VERSION ""
BS_:
BU_:

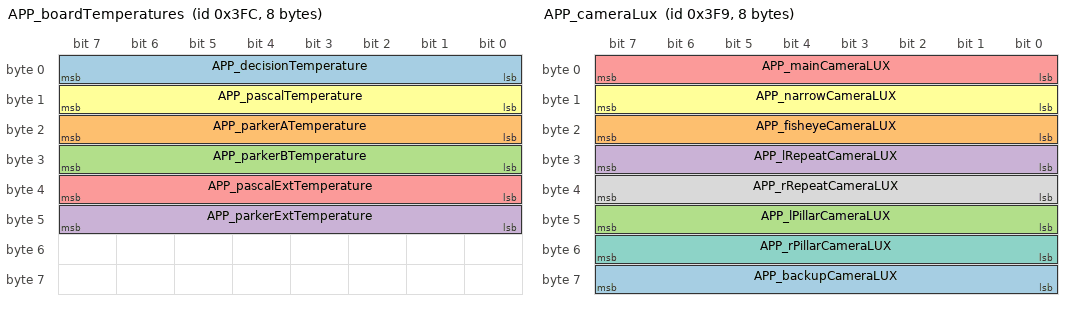
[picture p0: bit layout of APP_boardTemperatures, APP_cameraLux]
BO_ 1020 APP_boardTemperatures: 8 ETH
 SG_ APP_decisionTemperature: 0|8@1+ (1,-128) [0|0] "C" X
 SG_ APP_parkerATemperature: 16|8@1+ (1,-128) [0|0] "C" X
 SG_ APP_parkerBTemperature: 24|8@1+ (1,-128) [0|0] "C" X
 SG_ APP_parkerExtTemperature: 40|8@1+ (1,-128) [0|0] "C" X
 SG_ APP_pascalExtTemperature: 32|8@1+ (1,-128) [0|0] "C" X
 SG_ APP_pascalTemperature: 8|8@1+ (1,-128) [0|0] "C" X

BO_ 1010 APP_camCalibrationStatus: 6 ETH
 SG_ APP_cameraPosition M: 0|4@1+ (1,0) [0|0] "" X
 SG_ APP_mainCamExtPitchCal m1: 8|9@1+ (0.05,-12.5) [0|0] "deg" X
 SG_ APP_mainCamExtYawCal m1: 17|9@1+ (0.05,-12.5) [0|0] "deg" X
 SG_ APP_mainCalibTime m1: 26|7@1+ (1,0) [0|0] "min" X
 SG_ APP_mainCalibProgress m1: 33|7@1+ (1,0) [0|0] "percent" X
 SG_ APP_mainCalibrated m1: 40|1@1+ (1,0) [0|0] "" X
 SG_ APP_narrowCamExtPitchCal m2: 8|9@1+ (0.05,-12.5) [0|0] "deg" X
 SG_ APP_narrowCamExtYawCal m2: 17|9@1+ (0.05,-12.5) [0|0] "deg" X
 SG_ APP_narrowCalibTime m2: 26|7@1+ (1,0) [0|0] "min" X
 SG_ APP_narrowCalibProgress m2: 33|7@1+ (1,0) [0|0] "percent" X
 SG_ APP_narrowCalibrated m2: 40|1@1+ (1,0) [0|0] "" X
 SG_ APP_fisheyeCamExtPitchCal m3: 8|9@1+ (0.05,-12.5) [0|0] "deg" X
 SG_ APP_fisheyeCamExtYawCal m3: 17|9@1+ (0.05,-12.5) [0|0] "deg" X
 SG_ APP_fisheyeCalibTime m3: 26|7@1+ (1,0) [0|0] "min" X
 SG_ APP_fisheyeCalibProgress m3: 33|7@1+ (1,0) [0|0] "percent" X
 SG_ APP_fisheyeCalibrated m3: 40|1@1+ (1,0) [0|0] "" X
 SG_ APP_lPillarCamExtPitchCal m4: 8|9@1+ (0.05,-12.5) [0|0] "deg" X
 SG_ APP_lPillarCamExtYawCal m4: 17|9@1+ (0.05,-12.5) [0|0] "deg" X
 SG_ APP_lPillarCalibTime m4: 26|7@1+ (1,0) [0|0] "min" X
 SG_ APP_lPillarCalibProgress m4: 33|7@1+ (1,0) [0|0] "percent" X
 SG_ APP_lPillarCalibrated m4: 40|1@1+ (1,0) [0|0] "" X
 SG_ APP_rPillarCamExtPitchCal m5: 8|9@1+ (0.05,-12.5) [0|0] "deg" X
 SG_ APP_rPillarCamExtYawCal m5: 17|9@1+ (0.05,-12.5) [0|0] "deg" X
 SG_ APP_rPillarCalibTime m5: 26|7@1+ (1,0) [0|0] "min" X
 SG_ APP_rPillarCalibProgress m5: 33|7@1+ (1,0) [0|0] "percent" X
 SG_ APP_rPillarCalibrated m5: 40|1@1+ (1,0) [0|0] "" X
 SG_ APP_lRepeatCamExtPitchCal m6: 8|9@1+ (0.05,-12.5) [0|0] "deg" X
 SG_ APP_lRepeatCamExtYawCal m6: 17|9@1+ (0.05,-12.5) [0|0] "deg" X
 SG_ APP_lRepeatCalibTime m6: 26|7@1+ (1,0) [0|0] "min" X
 SG_ APP_lRepeatCalibProgress m6: 33|7@1+ (1,0) [0|0] "percent" X
 SG_ APP_lRepeatCalibrated m6: 40|1@1+ (1,0) [0|0] "" X
 SG_ APP_rRepeatCamExtPitchCal m7: 8|9@1+ (0.05,-12.5) [0|0] "deg" X
 SG_ APP_rRepeatCamExtYawCal m7: 17|9@1+ (0.05,-12.5) [0|0] "deg" X
 SG_ APP_rRepeatCalibTime m7: 26|7@1+ (1,0) [0|0] "min" X
 SG_ APP_rRepeatCalibProgress m7: 33|7@1+ (1,0) [0|0] "percent" X
 SG_ APP_rRepeatCalibrated m7: 40|1@1+ (1,0) [0|0] "" X
 SG_ APP_backupCamExtPitchCal m8: 8|9@1+ (0.05,-12.5) [0|0] "deg" X
 SG_ APP_backupCamExtYawCal m8: 17|9@1+ (0.05,-12.5) [0|0] "deg" X
 SG_ APP_backupCalibTime m8: 26|7@1+ (1,0) [0|0] "min" X
 SG_ APP_backupCalibProgress m8: 33|7@1+ (1,0) [0|0] "percent" X
 SG_ APP_backupCalibrated m8: 40|1@1+ (1,0) [0|0] "" X

BO_ 1017 APP_cameraLux: 8 ETH
 SG_ APP_backupCameraLUX: 56|8@1+ (50,0) [0|0] "lux" X
 SG_ APP_fisheyeCameraLUX: 16|8@1+ (50,0) [0|0] "lux" X
 SG_ APP_lPillarCameraLUX: 40|8@1+ (50,0) [0|0] "lux" X
 SG_ APP_lRepeatCameraLUX: 24|8@1+ (50,0) [0|0] "lux" X
 SG_ APP_mainCameraLUX: 0|8@1+ (50,0) [0|0] "lux" X
 SG_ APP_narrowCameraLUX: 8|8@1+ (50,0) [0|0] "lux" X
 SG_ APP_rPillarCameraLUX: 48|8@1+ (50,0) [0|0] "lux" X
 SG_ APP_rRepeatCameraLUX: 32|8@1+ (50,0) [0|0] "lux" X

BO_ 1040 APP_cameraStatus: 1 ETH
 SG_ APP_backupCameraFeedGood: 0|1@1+ (1,0) [0|0] "" X
 SG_ APP_backupCameraFrameRate: 1|6@1+ (1,0) [0|0] "" X

BO_ 1097 APP_warningMatrix0: 8 ETH
 SG_ APP_w002_ldwDisabled: 1|1@1+ (1,0) [0|0] "" X
 SG_ APP_w003_isaDisabled: 2|1@1+ (1,0) [0|0] "" X
 SG_ APP_w004_accDisabled: 3|1@1+ (1,0) [0|0] "" X
 SG_ APP_w005_fcwCancelled: 4|1@1+ (1,0) [0|0] "" X
 SG_ APP_w006_aebCancelled: 5|1@1+ (1,0) [0|0] "" X
 SG_ APP_w007_ahlbDisabled: 6|1@1+ (1,0) [0|0] "" X
 SG_ APP_w008_parkDisabled: 7|1@1+ (1,0) [0|0] "" X
 SG_ APP_w009_aebFault: 8|1@1+ (1,0) [0|0] "" X
 SG_ APP_w010_radcCalibIssue: 9|1@1+ (1,0) [0|0] "" X
 SG_ APP_w011_scaEvent: 10|1@1+ (1,0) [0|0] "" X
 SG_ APP_w012_Cam_BootFailure: 11|1@1+ (1,0) [0|0] "" X
 SG_ APP_w013_Cam_Watchdog: 12|1@1+ (1,0) [0|0] "" X
 SG_ APP_w014_swAssert: 13|1@1+ (1,0) [0|0] "" X
 SG_ APP_w015_Camera_Failsafes: 14|1@1+ (1,0) [0|0] "" X
 SG_ APP_w016_aeb_e_event: 15|1@1+ (1,0) [0|0] "" X
 SG_ APP_w017_Cam_Msg_MIA: 16|1@1+ (1,0) [0|0] "" X
 SG_ APP_w018_ECU_Power_Issue: 17|1@1+ (1,0) [0|0] "" X
 SG_ APP_w019_ECU_Stack_Overflow: 18|1@1+ (1,0) [0|0] "" X
 SG_ APP_w020_ECU_checkstopError: 19|1@1+ (1,0) [0|0] "" X
 SG_ APP_w021_ECU_Temperature_Issue: 20|1@1+ (1,0) [0|0] "" X
 SG_ APP_w022_ECU_EEPROM_Failure: 21|1@1+ (1,0) [0|0] "" X
 SG_ APP_w023_ECU_Cam_Statemismatc: 22|1@1+ (1,0) [0|0] "" X
 SG_ APP_w024_ECU_Watchdog_Reset: 23|1@1+ (1,0) [0|0] "" X
 SG_ APP_w025_LC_Steering_Override: 24|1@1+ (1,0) [0|0] "" X
 SG_ APP_w026_ECU_timingIssue: 25|1@1+ (1,0) [0|0] "" X
 SG_ APP_w027_ECU_Reset_Fault: 26|1@1+ (1,0) [0|0] "" X
 SG_ APP_w028_spi_rx_error: 27|1@1+ (1,0) [0|0] "" X
 SG_ APP_w029_spi_tx_error: 28|1@1+ (1,0) [0|0] "" X
 SG_ APP_w030_Heater_Issue: 29|1@1+ (1,0) [0|0] "" X
 SG_ APP_w031_canRxError: 30|1@1+ (1,0) [0|0] "" X
 SG_ APP_w032_canTxError: 31|1@1+ (1,0) [0|0] "" X
 SG_ APP_w033_gtwMia: 32|1@1+ (1,0) [0|0] "" X
 SG_ APP_w034_sccmMia: 33|1@1+ (1,0) [0|0] "" X
 SG_ APP_w035_espMia: 34|1@1+ (1,0) [0|0] "" X
 SG_ APP_w036_bdyMia: 35|1@1+ (1,0) [0|0] "" X
 SG_ APP_w037_camTacIssue: 36|1@1+ (1,0) [0|0] "" X
 SG_ APP_w038_camFailure: 37|1@1+ (1,0) [0|0] "" X
 SG_ APP_w039_sdm_rcm_Mia: 38|1@1+ (1,0) [0|0] "" X
 SG_ APP_w040_autopilotAngleSaturated: 39|1@1+ (1,0) [0|0] "" X
 SG_ APP_w041_autopilotRateSaturated: 40|1@1+ (1,0) [0|0] "" X
 SG_ APP_w042_autopilotAborting: 41|1@1+ (1,0) [0|0] "" X
 SG_ APP_w043_camLongRunTime: 42|1@1+ (1,0) [0|0] "" X
 SG_ APP_w044_appMobileyeFailure: 43|1@1+ (1,0) [0|0] "" X
 SG_ APP_w045_radMia: 44|1@1+ (1,0) [0|0] "" X
 SG_ APP_w046_eepromRecordAbsent: 45|1@1+ (1,0) [0|0] "" X
 SG_ APP_w047_edrEvent: 46|1@1+ (1,0) [0|0] "" X
 SG_ APP_w048_APP_Features_Disabled: 47|1@1+ (1,0) [0|0] "" X
 SG_ APP_w049_eyeqVersionMismatch: 48|1@1+ (1,0) [0|0] "" X
 SG_ APP_w050_aeb_event: 49|1@1+ (1,0) [0|0] "" X
 SG_ APP_w051_radcEcuIssue: 50|1@1+ (1,0) [0|0] "" X
 SG_ APP_w052_radcSensorIssue: 51|1@1+ (1,0) [0|0] "" X
 SG_ APP_w053_radcCommIssue: 52|1@1+ (1,0) [0|0] "" X
 SG_ APP_w054_camAutofix: 53|1@1+ (1,0) [0|0] "" X
 SG_ APP_w055_radcVersionMismatch: 54|1@1+ (1,0) [0|0] "" X
 SG_ APP_w056_diMia: 55|1@1+ (1,0) [0|0] "" X
 SG_ APP_w057_mcuMia: 56|1@1+ (1,0) [0|0] "" X
 SG_ APP_w058_epbMia: 57|1@1+ (1,0) [0|0] "" X
 SG_ APP_w059_parkMia: 58|1@1+ (1,0) [0|0] "" X
 SG_ APP_w060_fcw_event: 59|1@1+ (1,0) [0|0] "" X
 SG_ APP_w061_airSuspensionMia: 60|1@1+ (1,0) [0|0] "" X
 SG_ APP_w062_radcAlignment: 61|1@1+ (1,0) [0|0] "" X
 SG_ APP_w063_parkVersionMismatch: 62|1@1+ (1,0) [0|0] "" X
 SG_ APP_w064_epasMia: 63|1@1+ (1,0) [0|0] "" X

BO_ 1049 APP_warningMatrix1: 8 ETH
 SG_ APP_w065_deserializerOvercurrent: 0|1@1+ (1,0) [0|0] "" X
 SG_ APP_w066_deserializerLockLost: 1|1@1+ (1,0) [0|0] "" X
 SG_ APP_w067_steeringAlignment: 2|1@1+ (1,0) [0|0] "" X
 SG_ APP_w068_vlInconsistency: 3|1@1+ (1,0) [0|0] "" X
 SG_ APP_w069_apcSpaceMasked: 4|1@1+ (1,0) [0|0] "" X
 SG_ APP_w070_apcIncompleteCal: 5|1@1+ (1,0) [0|0] "" X
 SG_ APP_w071_selfparkStarted: 6|1@1+ (1,0) [0|0] "" X
 SG_ APP_w072_selfparkComplete: 7|1@1+ (1,0) [0|0] "" X
 SG_ APP_w073_issueEscalatedLDW: 8|1@1+ (1,0) [0|0] "" X
 SG_ APP_w074_inPathStationaryObst: 9|1@1+ (1,0) [0|0] "" X
 SG_ APP_w075_scMia: 10|1@1+ (1,0) [0|0] "" X
 SG_ APP_w076_mobilEyeSetC: 11|1@1+ (1,0) [0|0] "" X
 SG_ APP_w077_pmmActive: 12|1@1+ (1,0) [0|0] "" X
 SG_ APP_w078_pmmActive2: 13|1@1+ (1,0) [0|0] "" X
 SG_ APP_w079_edrAvailable: 14|1@1+ (1,0) [0|0] "" X
 SG_ APP_w080_accFailedActivation: 15|1@1+ (1,0) [0|0] "" X
 SG_ APP_w081_pmmActiveBraking: 16|1@1+ (1,0) [0|0] "" X
 SG_ APP_w082_inPathFSviolation: 17|1@1+ (1,0) [0|0] "" X
 SG_ APP_w083_inPathRADObject: 18|1@1+ (1,0) [0|0] "" X
 SG_ APP_w084_pmmIPSO: 19|1@1+ (1,0) [0|0] "" X
 SG_ APP_w085_pmmSteering: 20|1@1+ (1,0) [0|0] "" X
 SG_ APP_w086_robCollision: 21|1@1+ (1,0) [0|0] "" X
 SG_ APP_w087_DEPRECATED: 22|1@1+ (1,0) [0|0] "" X
 SG_ APP_w088_DEPRECATED: 23|1@1+ (1,0) [0|0] "" X
 SG_ APP_w089_DEPRECATED: 24|1@1+ (1,0) [0|0] "" X
 SG_ APP_w090_DEPRECATED: 25|1@1+ (1,0) [0|0] "" X
 SG_ APP_w091_DEPRECATED: 26|1@1+ (1,0) [0|0] "" X
 SG_ APP_w092_DEPRECATED: 27|1@1+ (1,0) [0|0] "" X
 SG_ APP_w093_DEPRECATED: 28|1@1+ (1,0) [0|0] "" X
 SG_ APP_w094_DEPRECATED: 29|1@1+ (1,0) [0|0] "" X
 SG_ APP_w095_DEPRECATED: 30|1@1+ (1,0) [0|0] "" X
 SG_ APP_w096_DEPRECATED: 31|1@1+ (1,0) [0|0] "" X
 SG_ APP_w097_DEPRECATED: 32|1@1+ (1,0) [0|0] "" X
 SG_ APP_w098_DEPRECATED: 33|1@1+ (1,0) [0|0] "" X
 SG_ APP_w099_DEPRECATED: 34|1@1+ (1,0) [0|0] "" X
 SG_ APP_w100_DEPRECATED: 35|1@1+ (1,0) [0|0] "" X
 SG_ APP_w101_DEPRECATED: 36|1@1+ (1,0) [0|0] "" X
 SG_ APP_w102_DEPRECATED: 37|1@1+ (1,0) [0|0] "" X
 SG_ APP_w103_robExperimentalAEB: 38|1@1+ (1,0) [0|0] "" X
 SG_ APP_w104_DEPRECATED: 39|1@1+ (1,0) [0|0] "" X
 SG_ APP_w105_DEPRECATED: 40|1@1+ (1,0) [0|0] "" X
 SG_ APP_w106_torsionBarCalibrated: 41|1@1+ (1,0) [0|0] "" X

BO_ 1065 APP_warningMatrix2: 8 ETH
 SG_ APP_w129_mainCamExtNotCal: 0|1@1+ (1,0) [0|0] "" X
 SG_ APP_w130_narrowCamExtNotCal: 1|1@1+ (1,0) [0|0] "" X
 SG_ APP_w131_mainCamCalSaved: 2|1@1+ (1,0) [0|0] "" X
 SG_ APP_w132_narrowCamCalSaved: 3|1@1+ (1,0) [0|0] "" X
 SG_ APP_w133_mainCamInitFault: 4|1@1+ (1,0) [0|0] "" X
 SG_ APP_w134_narrowCamInitFault: 5|1@1+ (1,0) [0|0] "" X
 SG_ APP_w135_fisheyeCamInitFault: 6|1@1+ (1,0) [0|0] "" X
 SG_ APP_w136_lPillarCamInitFault: 7|1@1+ (1,0) [0|0] "" X
 SG_ APP_w137_rPillarCamInitFault: 8|1@1+ (1,0) [0|0] "" X
 SG_ APP_w138_lRepeatCamInitFault: 9|1@1+ (1,0) [0|0] "" X
 SG_ APP_w139_rRepeatCamInitFault: 10|1@1+ (1,0) [0|0] "" X
 SG_ APP_w140_backupCamInitFault: 11|1@1+ (1,0) [0|0] "" X
 SG_ APP_w141_ECU_Thermal_Issue: 12|1@1+ (1,0) [0|0] "" X
 SG_ APP_w142_fwdCamPitchProblem: 13|1@1+ (1,0) [0|0] "" X
 SG_ APP_w143_IDF_event: 14|1@1+ (1,0) [0|0] "" X
 SG_ APP_w144_fanctrldError: 15|1@1+ (1,0) [0|0] "" X
 SG_ APP_w145_camSelfCalIssue: 16|1@1+ (1,0) [0|0] "" X
 SG_ APP_w146_telemetryProblem: 17|1@1+ (1,0) [0|0] "" X
 SG_ APP_w147_selfieCamInitFault: 18|1@1+ (1,0) [0|0] "" X
 SG_ APP_w148_overlayActive: 19|1@1+ (1,0) [0|0] "" X
 SG_ APP_w149_diskFull: 20|1@1+ (1,0) [0|0] "" X
 SG_ APP_w161_backupCameraUnavailable: 32|1@1+ (1,0) [0|0] "" X
 SG_ APP_w162_mainCameraTypeError: 33|1@1+ (1,0) [0|0] "" X
 SG_ APP_w163_narrowCameraTypeError: 34|1@1+ (1,0) [0|0] "" X
 SG_ APP_w164_fisheyeCameraTypeError: 35|1@1+ (1,0) [0|0] "" X
 SG_ APP_w165_lPillarCameraTypeError: 36|1@1+ (1,0) [0|0] "" X
 SG_ APP_w166_rPillarCameraTypeError: 37|1@1+ (1,0) [0|0] "" X
 SG_ APP_w167_lRepeatCameraTypeError: 38|1@1+ (1,0) [0|0] "" X
 SG_ APP_w168_rRepeatCameraTypeError: 39|1@1+ (1,0) [0|0] "" X
 SG_ APP_w169_backupCameraTypeError: 40|1@1+ (1,0) [0|0] "" X
 SG_ APP_w170_selfieCameraTypeError: 41|1@1+ (1,0) [0|0] "" X
 SG_ APP_w172_fisheyeCamExtNotCal: 43|1@1+ (1,0) [0|0] "" X
 SG_ APP_w173_lPillarCamExtNotCal: 44|1@1+ (1,0) [0|0] "" X
 SG_ APP_w174_rPillarCamExtNotCal: 45|1@1+ (1,0) [0|0] "" X
 SG_ APP_w175_lRepeatCamExtNotCal: 46|1@1+ (1,0) [0|0] "" X
 SG_ APP_w176_rRepeatCamExtNotCal: 47|1@1+ (1,0) [0|0] "" X
 SG_ APP_w177_fisheyeCamCalSaved: 48|1@1+ (1,0) [0|0] "" X
 SG_ APP_w178_lPillarCamCalSaved: 49|1@1+ (1,0) [0|0] "" X
 SG_ APP_w179_rPillarCamCalSaved: 50|1@1+ (1,0) [0|0] "" X
 SG_ APP_w180_lRepeatCamCalSaved: 51|1@1+ (1,0) [0|0] "" X
 SG_ APP_w181_rRepeatCamCalSaved: 52|1@1+ (1,0) [0|0] "" X
 SG_ APP_w182_mainCameraStreamExit: 53|1@1+ (1,0) [0|0] "" X
 SG_ APP_w183_narrowCameraStreamExit: 54|1@1+ (1,0) [0|0] "" X
 SG_ APP_w184_fisheyeCameraStreamExit: 55|1@1+ (1,0) [0|0] "" X
 SG_ APP_w185_lPillarCameraStreamExit: 56|1@1+ (1,0) [0|0] "" X
 SG_ APP_w186_rPillarCameraStreamExit: 57|1@1+ (1,0) [0|0] "" X
 SG_ APP_w187_lRepeatCameraStreamExit: 58|1@1+ (1,0) [0|0] "" X
 SG_ APP_w188_rRepeatCameraStreamExit: 59|1@1+ (1,0) [0|0] "" X
 SG_ APP_w189_backupCameraStreamExit: 60|1@1+ (1,0) [0|0] "" X
 SG_ APP_w190_selfieCameraStreamExit: 61|1@1+ (1,0) [0|0] "" X
 SG_ APP_w191_autopilotAborting: 62|1@1+ (1,0) [0|0] "" X
 SG_ APP_w192_emergencySpeakerFail: 63|1@1+ (1,0) [0|0] "" X

BO_ 1081 APP_warningMatrix3: 8 ETH
 SG_ APP_w193_camWindshieldUnclean: 0|1@1+ (1,0) [0|0] "" X
 SG_ APP_w194_accDriverResumeRqrd: 1|1@1+ (1,0) [0|0] "" X
 SG_ APP_w195_scwUnavailable: 2|1@1+ (1,0) [0|0] "" X
 SG_ APP_w196_stopSignWarning: 3|1@1+ (1,0) [0|0] "" X
 SG_ APP_w197_redLightWarning: 4|1@1+ (1,0) [0|0] "" X
 SG_ APP_w198_tsrUnavailable: 5|1@1+ (1,0) [0|0] "" X
 SG_ APP_w199_apcAbort: 6|1@1+ (1,0) [0|0] "" X
 SG_ APP_w200_lcSlowdown: 7|1@1+ (1,0) [0|0] "" X
 SG_ APP_w201_lcAborting: 8|1@1+ (1,0) [0|0] "" X
 SG_ APP_w202_scwNoisyEnvironment: 9|1@1+ (1,0) [0|0] "" X
 SG_ APP_w203_apcActivation: 10|1@1+ (1,0) [0|0] "" X
 SG_ APP_w204_apcFinalFront: 11|1@1+ (1,0) [0|0] "" X
 SG_ APP_w205_apcFinalRear: 12|1@1+ (1,0) [0|0] "" X
 SG_ APP_w206_autosteerNotEnabled: 13|1@1+ (1,0) [0|0] "" X
 SG_ APP_w207_autosteerUnavailable: 14|1@1+ (1,0) [0|0] "" X
 SG_ APP_w208_rackDetected: 15|1@1+ (1,0) [0|0] "" X
 SG_ APP_w209_autoSummonRequest: 16|1@1+ (1,0) [0|0] "" X
 SG_ APP_w210_camObstrcted: 17|1@1+ (1,0) [0|0] "" X
 SG_ APP_w211_accNoSeatBelt: 18|1@1+ (1,0) [0|0] "" X
 SG_ APP_w212_lcUnavailableStrikeOut: 19|1@1+ (1,0) [0|0] "" X
 SG_ APP_w213_autosteerStruckOut: 20|1@1+ (1,0) [0|0] "" X
 SG_ APP_w214_driverNotIntracting: 21|1@1+ (1,0) [0|0] "" X
 SG_ APP_w215_contDriverNotIntracting: 22|1@1+ (1,0) [0|0] "" X
 SG_ APP_w216_driverOverriding: 23|1@1+ (1,0) [0|0] "" X
 SG_ APP_w217_lcUnavailableSpeeding: 24|1@1+ (1,0) [0|0] "" X
 SG_ APP_w218_lcSpeedExceededLimit: 25|1@1+ (1,0) [0|0] "" X
 SG_ APP_w219_lcTempUnavailableSpeed: 26|1@1+ (1,0) [0|0] "" X
 SG_ APP_w220_lcTempUnavailableRoad: 27|1@1+ (1,0) [0|0] "" X
 SG_ APP_w221_accRadarBlind: 28|1@1+ (1,0) [0|0] "" X
 SG_ APP_w222_accCameraBlind: 29|1@1+ (1,0) [0|0] "" X
 SG_ APP_w223_accObjectInPath: 30|1@1+ (1,0) [0|0] "" X
 SG_ APP_w224_accCameraCalibration: 31|1@1+ (1,0) [0|0] "" X
 SG_ APP_w225_lcDegradedVisSpeedLmt: 32|1@1+ (1,0) [0|0] "" X
 SG_ APP_w226_lcCamCalNeededSpeedLmt: 33|1@1+ (1,0) [0|0] "" X
 SG_ APP_w227_virtualWallBlocked: 34|1@1+ (1,0) [0|0] "" X
 SG_ APP_w228_DEPRECATED: 35|1@1+ (1,0) [0|0] "" X
 SG_ APP_w229_alcUltrasoundDamaged: 36|1@1+ (1,0) [0|0] "" X
 SG_ APP_w230_alcUltrasoundBlocked: 37|1@1+ (1,0) [0|0] "" X
 SG_ APP_w231_idfEvent: 38|1@1+ (1,0) [0|0] "" X

BO_ 1129 APP_warningMatrix4: 8 ETH
 SG_ APP_w257_brakeJerkEvent: 0|1@1+ (1,0) [0|0] "" X
 SG_ APP_w258_aebEvent: 1|1@1+ (1,0) [0|0] "" X
 SG_ APP_w259_aebOverrideEvent: 2|1@1+ (1,0) [0|0] "" X
 SG_ APP_w260_collisionWarningEvent: 3|1@1+ (1,0) [0|0] "" X
 SG_ APP_w261_pcieHardwareErrors: 4|1@1+ (1,0) [0|0] "" X
 SG_ APP_w262_apeCalibMode: 5|1@1+ (1,0) [0|0] "" X
 SG_ APP_w263_lssAbort: 6|1@1+ (1,0) [0|0] "" X
 SG_ APP_w264_lssFault: 7|1@1+ (1,0) [0|0] "" X
 SG_ APP_w265_drvOnNavUnavailable: 8|1@1+ (1,0) [0|0] "" X
 SG_ APP_w266_visionScheduleFallback: 9|1@1+ (1,0) [0|0] "" X
 SG_ APP_w267_benchtopEcu: 10|1@1+ (1,0) [0|0] "" X
 SG_ APP_w268_backupCamExtNotCal: 11|1@1+ (1,0) [0|0] "" X
 SG_ APP_w269_autopilotLimited: 12|1@1+ (1,0) [0|0] "" X
 SG_ APP_w270_blindspotRestricted: 13|1@1+ (1,0) [0|0] "" X
 SG_ APP_w271_laneChangeAborted: 14|1@1+ (1,0) [0|0] "" X
 SG_ APP_w272_laneChangeUnavailable: 15|1@1+ (1,0) [0|0] "" X
 SG_ APP_w273_lssEvent: 16|1@1+ (1,0) [0|0] "" X
 SG_ APP_w274_mainCameraStreamErr: 17|1@1+ (1,0) [0|0] "" X
 SG_ APP_w275_narrowCameraStreamErr: 18|1@1+ (1,0) [0|0] "" X
 SG_ APP_w276_fisheyeCameraStreamErr: 19|1@1+ (1,0) [0|0] "" X
 SG_ APP_w277_lPillarCameraStreamErr: 20|1@1+ (1,0) [0|0] "" X
 SG_ APP_w278_rPillarCameraStreamErr: 21|1@1+ (1,0) [0|0] "" X
 SG_ APP_w279_lRepeatCameraStreamErr: 22|1@1+ (1,0) [0|0] "" X
 SG_ APP_w280_rRepeatCameraStreamErr: 23|1@1+ (1,0) [0|0] "" X
 SG_ APP_w281_backupCameraStreamErr: 24|1@1+ (1,0) [0|0] "" X
 SG_ APP_w282_selfieCameraStreamErr: 25|1@1+ (1,0) [0|0] "" X

BO_ 811 APS_warningMatrix0: 8 ETH
 SG_ APS_w002_ldwDisabled: 1|1@1+ (1,0) [0|0] "" X
 SG_ APS_w003_isaDisabled: 2|1@1+ (1,0) [0|0] "" X
 SG_ APS_w004_accDisabled: 3|1@1+ (1,0) [0|0] "" X
 SG_ APS_w005_fcwCancelled: 4|1@1+ (1,0) [0|0] "" X
 SG_ APS_w006_aebCancelled: 5|1@1+ (1,0) [0|0] "" X
 SG_ APS_w007_ahlbDisabled: 6|1@1+ (1,0) [0|0] "" X
 SG_ APS_w008_parkDisabled: 7|1@1+ (1,0) [0|0] "" X
 SG_ APS_w009_aebFault: 8|1@1+ (1,0) [0|0] "" X
 SG_ APS_w010_radcCalibIssue: 9|1@1+ (1,0) [0|0] "" X
 SG_ APS_w011_scaEvent: 10|1@1+ (1,0) [0|0] "" X
 SG_ APS_w012_Cam_BootFailure: 11|1@1+ (1,0) [0|0] "" X
 SG_ APS_w013_Cam_Watchdog: 12|1@1+ (1,0) [0|0] "" X
 SG_ APS_w014_swAssert: 13|1@1+ (1,0) [0|0] "" X
 SG_ APS_w015_Camera_Failsafes: 14|1@1+ (1,0) [0|0] "" X
 SG_ APS_w016_aeb_e_event: 15|1@1+ (1,0) [0|0] "" X
 SG_ APS_w017_Cam_Msg_MIA: 16|1@1+ (1,0) [0|0] "" X
 SG_ APS_w018_ECU_Power_Issue: 17|1@1+ (1,0) [0|0] "" X
 SG_ APS_w019_ECU_Stack_Overflow: 18|1@1+ (1,0) [0|0] "" X
 SG_ APS_w020_ECU_checkstopError: 19|1@1+ (1,0) [0|0] "" X
 SG_ APS_w021_ECU_Temperature_Issue: 20|1@1+ (1,0) [0|0] "" X
 SG_ APS_w022_ECU_EEPROM_Failure: 21|1@1+ (1,0) [0|0] "" X
 SG_ APS_w023_ECU_Cam_Statemismatc: 22|1@1+ (1,0) [0|0] "" X
 SG_ APS_w024_ECU_Watchdog_Reset: 23|1@1+ (1,0) [0|0] "" X
 SG_ APS_w025_LC_Steering_Override: 24|1@1+ (1,0) [0|0] "" X
 SG_ APS_w026_ECU_timingIssue: 25|1@1+ (1,0) [0|0] "" X
 SG_ APS_w027_ECU_Reset_Fault: 26|1@1+ (1,0) [0|0] "" X
 SG_ APS_w028_spi_rx_error: 27|1@1+ (1,0) [0|0] "" X
 SG_ APS_w029_spi_tx_error: 28|1@1+ (1,0) [0|0] "" X
 SG_ APS_w030_Heater_Issue: 29|1@1+ (1,0) [0|0] "" X
 SG_ APS_w031_canRxError: 30|1@1+ (1,0) [0|0] "" X
 SG_ APS_w032_canTxError: 31|1@1+ (1,0) [0|0] "" X
 SG_ APS_w033_gtwMia: 32|1@1+ (1,0) [0|0] "" X
 SG_ APS_w034_sccmMia: 33|1@1+ (1,0) [0|0] "" X
 SG_ APS_w035_espMia: 34|1@1+ (1,0) [0|0] "" X
 SG_ APS_w036_bdyMia: 35|1@1+ (1,0) [0|0] "" X
 SG_ APS_w037_camTacIssue: 36|1@1+ (1,0) [0|0] "" X
 SG_ APS_w038_camFailure: 37|1@1+ (1,0) [0|0] "" X
 SG_ APS_w039_sdm_rcm_Mia: 38|1@1+ (1,0) [0|0] "" X
 SG_ APS_w040_autopilotAngleSaturated: 39|1@1+ (1,0) [0|0] "" X
 SG_ APS_w041_autopilotRateSaturated: 40|1@1+ (1,0) [0|0] "" X
 SG_ APS_w042_autopilotAborting: 41|1@1+ (1,0) [0|0] "" X
 SG_ APS_w043_camLongRunTime: 42|1@1+ (1,0) [0|0] "" X
 SG_ APS_w044_appMobileyeFailure: 43|1@1+ (1,0) [0|0] "" X
 SG_ APS_w045_radMia: 44|1@1+ (1,0) [0|0] "" X
 SG_ APS_w046_eepromRecordAbsent: 45|1@1+ (1,0) [0|0] "" X
 SG_ APS_w047_edrEvent: 46|1@1+ (1,0) [0|0] "" X
 SG_ APS_w048_APS_Features_Disabled: 47|1@1+ (1,0) [0|0] "" X
 SG_ APS_w049_eyeqVersionMismatch: 48|1@1+ (1,0) [0|0] "" X
 SG_ APS_w050_aeb_event: 49|1@1+ (1,0) [0|0] "" X
 SG_ APS_w051_radcEcuIssue: 50|1@1+ (1,0) [0|0] "" X
 SG_ APS_w052_radcSensorIssue: 51|1@1+ (1,0) [0|0] "" X
 SG_ APS_w053_radcCommIssue: 52|1@1+ (1,0) [0|0] "" X
 SG_ APS_w054_camAutofix: 53|1@1+ (1,0) [0|0] "" X
 SG_ APS_w055_radcVersionMismatch: 54|1@1+ (1,0) [0|0] "" X
 SG_ APS_w056_diMia: 55|1@1+ (1,0) [0|0] "" X
 SG_ APS_w057_mcuMia: 56|1@1+ (1,0) [0|0] "" X
 SG_ APS_w058_epbMia: 57|1@1+ (1,0) [0|0] "" X
 SG_ APS_w059_parkMia: 58|1@1+ (1,0) [0|0] "" X
 SG_ APS_w060_fcw_event: 59|1@1+ (1,0) [0|0] "" X
 SG_ APS_w061_airSuspensionMia: 60|1@1+ (1,0) [0|0] "" X
 SG_ APS_w062_radcAlignment: 61|1@1+ (1,0) [0|0] "" X
 SG_ APS_w063_parkVersionMismatch: 62|1@1+ (1,0) [0|0] "" X
 SG_ APS_w064_epasMia: 63|1@1+ (1,0) [0|0] "" X

BO_ 876 APS_warningMatrix1: 8 ETH
 SG_ APS_w065_deserializerOvercurrent: 0|1@1+ (1,0) [0|0] "" X
 SG_ APS_w066_deserializerLockLost: 1|1@1+ (1,0) [0|0] "" X
 SG_ APS_w067_steeringAlignment: 2|1@1+ (1,0) [0|0] "" X
 SG_ APS_w068_vlInconsistency: 3|1@1+ (1,0) [0|0] "" X
 SG_ APS_w069_apcSpaceMasked: 4|1@1+ (1,0) [0|0] "" X
 SG_ APS_w070_apcIncompleteCal: 5|1@1+ (1,0) [0|0] "" X
 SG_ APS_w071_selfparkStarted: 6|1@1+ (1,0) [0|0] "" X
 SG_ APS_w072_selfparkComplete: 7|1@1+ (1,0) [0|0] "" X
 SG_ APS_w073_issueEscalatedLDW: 8|1@1+ (1,0) [0|0] "" X
 SG_ APS_w074_inPathStationaryObst: 9|1@1+ (1,0) [0|0] "" X
 SG_ APS_w075_scMia: 10|1@1+ (1,0) [0|0] "" X
 SG_ APS_w076_mobilEyeSetC: 11|1@1+ (1,0) [0|0] "" X
 SG_ APS_w077_pmmActive: 12|1@1+ (1,0) [0|0] "" X
 SG_ APS_w078_pmmActive2: 13|1@1+ (1,0) [0|0] "" X
 SG_ APS_w079_edrAvailable: 14|1@1+ (1,0) [0|0] "" X
 SG_ APS_w080_accFailedActivation: 15|1@1+ (1,0) [0|0] "" X
 SG_ APS_w081_pmmActiveBraking: 16|1@1+ (1,0) [0|0] "" X
 SG_ APS_w082_inPathFSviolation: 17|1@1+ (1,0) [0|0] "" X
 SG_ APS_w083_inPathRADObject: 18|1@1+ (1,0) [0|0] "" X
 SG_ APS_w084_pmmIPSO: 19|1@1+ (1,0) [0|0] "" X
 SG_ APS_w085_pmmSteering: 20|1@1+ (1,0) [0|0] "" X
 SG_ APS_w086_robCollision: 21|1@1+ (1,0) [0|0] "" X
 SG_ APS_w087_DEPRECATED: 22|1@1+ (1,0) [0|0] "" X
 SG_ APS_w088_DEPRECATED: 23|1@1+ (1,0) [0|0] "" X
 SG_ APS_w089_DEPRECATED: 24|1@1+ (1,0) [0|0] "" X
 SG_ APS_w090_DEPRECATED: 25|1@1+ (1,0) [0|0] "" X
 SG_ APS_w091_DEPRECATED: 26|1@1+ (1,0) [0|0] "" X
 SG_ APS_w092_DEPRECATED: 27|1@1+ (1,0) [0|0] "" X
 SG_ APS_w093_DEPRECATED: 28|1@1+ (1,0) [0|0] "" X
 SG_ APS_w094_DEPRECATED: 29|1@1+ (1,0) [0|0] "" X
 SG_ APS_w095_DEPRECATED: 30|1@1+ (1,0) [0|0] "" X
 SG_ APS_w096_DEPRECATED: 31|1@1+ (1,0) [0|0] "" X
 SG_ APS_w097_DEPRECATED: 32|1@1+ (1,0) [0|0] "" X
 SG_ APS_w098_DEPRECATED: 33|1@1+ (1,0) [0|0] "" X
 SG_ APS_w099_DEPRECATED: 34|1@1+ (1,0) [0|0] "" X
 SG_ APS_w100_DEPRECATED: 35|1@1+ (1,0) [0|0] "" X
 SG_ APS_w101_DEPRECATED: 36|1@1+ (1,0) [0|0] "" X
 SG_ APS_w102_DEPRECATED: 37|1@1+ (1,0) [0|0] "" X
 SG_ APS_w103_robExperimentalAEB: 38|1@1+ (1,0) [0|0] "" X
 SG_ APS_w104_DEPRECATED: 39|1@1+ (1,0) [0|0] "" X
 SG_ APS_w105_DEPRECATED: 40|1@1+ (1,0) [0|0] "" X
 SG_ APS_w106_torsionBarCalibrated: 41|1@1+ (1,0) [0|0] "" X

BO_ 1113 APS_warningMatrix2: 8 ETH
 SG_ APS_w129_ECU_Power_Issue: 0|1@1+ (1,0) [0|0] "" X
 SG_ APS_w130_ECU_Thermal_Issue: 1|1@1+ (1,0) [0|0] "" X
 SG_ APS_w131_trap_exception: 2|1@1+ (1,0) [0|0] "" X
 SG_ APS_w132_appVersionMismatch: 3|1@1+ (1,0) [0|0] "" X
 SG_ APS_w133_ETHSwitchError: 4|1@1+ (1,0) [0|0] "" X
 SG_ APS_w134_appMia: 5|1@1+ (1,0) [0|0] "" X
 SG_ APS_w135_appCritical: 6|1@1+ (1,0) [0|0] "" X
 SG_ APS_w136_gpsDisabled: 7|1@1+ (1,0) [0|0] "" X
 SG_ APS_w137_gpsFaultReset: 8|1@1+ (1,0) [0|0] "" X
 SG_ APS_w138_gpsComIssue: 9|1@1+ (1,0) [0|0] "" X
 SG_ APS_w139_udpBufferOverflow: 10|1@1+ (1,0) [0|0] "" X
 SG_ APS_w146_epas3pMiaPartyBus: 17|1@1+ (1,0) [0|0] "" X
 SG_ APS_w151_apRecovered: 22|1@1+ (1,0) [0|0] "" X
 SG_ APS_w152_gpsFusionStatus: 23|1@1+ (1,0) [0|0] "" X
 SG_ APS_w153_eacInhibit: 24|1@1+ (1,0) [0|0] "" X
 SG_ APS_w154_secEthPacketMIA: 25|1@1+ (1,0) [0|0] "" X
 SG_ APS_w155_ethLwipError: 26|1@1+ (1,0) [0|0] "" X
 SG_ APS_w156_lwipAssert: 27|1@1+ (1,0) [0|0] "" X
 SG_ APS_w157_autopilotReboot: 28|1@1+ (1,0) [0|0] "" X
 SG_ APS_w158_apbMia: 29|1@1+ (1,0) [0|0] "" X
 SG_ APS_w159_apbCritical: 30|1@1+ (1,0) [0|0] "" X
 SG_ APS_w160_apbVersionMismatch: 31|1@1+ (1,0) [0|0] "" X
 SG_ APS_w161_gpsAntennaDisconnected: 32|1@1+ (1,0) [0|0] "" X

BO_ 848 APS_warningMatrix3: 8 ETH
 SG_ APS_w193_camWindshieldUnclean: 0|1@1+ (1,0) [0|0] "" X
 SG_ APS_w194_accDriverResumeRqrd: 1|1@1+ (1,0) [0|0] "" X
 SG_ APS_w195_scwUnavailable: 2|1@1+ (1,0) [0|0] "" X
 SG_ APS_w196_stopSignWarning: 3|1@1+ (1,0) [0|0] "" X
 SG_ APS_w197_redLightWarning: 4|1@1+ (1,0) [0|0] "" X
 SG_ APS_w198_tsrUnavailable: 5|1@1+ (1,0) [0|0] "" X
 SG_ APS_w199_apcAbort: 6|1@1+ (1,0) [0|0] "" X
 SG_ APS_w200_lcSlowdown: 7|1@1+ (1,0) [0|0] "" X
 SG_ APS_w201_lcAborting: 8|1@1+ (1,0) [0|0] "" X
 SG_ APS_w202_scwNoisyEnvironment: 9|1@1+ (1,0) [0|0] "" X
 SG_ APS_w203_apcActivation: 10|1@1+ (1,0) [0|0] "" X
 SG_ APS_w204_apcFinalFront: 11|1@1+ (1,0) [0|0] "" X
 SG_ APS_w205_apcFinalRear: 12|1@1+ (1,0) [0|0] "" X
 SG_ APS_w206_autosteerNotEnabled: 13|1@1+ (1,0) [0|0] "" X
 SG_ APS_w207_autosteerUnavailable: 14|1@1+ (1,0) [0|0] "" X
 SG_ APS_w208_rackDetected: 15|1@1+ (1,0) [0|0] "" X
 SG_ APS_w209_autoSummonRequest: 16|1@1+ (1,0) [0|0] "" X
 SG_ APS_w210_camObstrcted: 17|1@1+ (1,0) [0|0] "" X
 SG_ APS_w211_accNoSeatBelt: 18|1@1+ (1,0) [0|0] "" X
 SG_ APS_w212_lcUnavailableStrikeOut: 19|1@1+ (1,0) [0|0] "" X
 SG_ APS_w213_autosteerStruckOut: 20|1@1+ (1,0) [0|0] "" X
 SG_ APS_w214_driverNotIntracting: 21|1@1+ (1,0) [0|0] "" X
 SG_ APS_w215_contDriverNotIntracting: 22|1@1+ (1,0) [0|0] "" X
 SG_ APS_w216_driverOverriding: 23|1@1+ (1,0) [0|0] "" X
 SG_ APS_w217_lcUnavailableSpeeding: 24|1@1+ (1,0) [0|0] "" X
 SG_ APS_w218_lcSpeedExceededLimit: 25|1@1+ (1,0) [0|0] "" X
 SG_ APS_w219_lcTempUnavailableSpeed: 26|1@1+ (1,0) [0|0] "" X
 SG_ APS_w220_lcTempUnavailableRoad: 27|1@1+ (1,0) [0|0] "" X
 SG_ APS_w221_accRadarBlind: 28|1@1+ (1,0) [0|0] "" X
 SG_ APS_w222_accCameraBlind: 29|1@1+ (1,0) [0|0] "" X
 SG_ APS_w223_accObjectInPath: 30|1@1+ (1,0) [0|0] "" X
 SG_ APS_w224_accCameraCalibration: 31|1@1+ (1,0) [0|0] "" X
 SG_ APS_w225_lcDegradedVisSpeedLmt: 32|1@1+ (1,0) [0|0] "" X
 SG_ APS_w226_lcCamCalNeededSpeedLmt: 33|1@1+ (1,0) [0|0] "" X
 SG_ APS_w227_virtualWallBlocked: 34|1@1+ (1,0) [0|0] "" X
 SG_ APS_w228_DEPRECATED: 35|1@1+ (1,0) [0|0] "" X
 SG_ APS_w229_alcUltrasoundDamaged: 36|1@1+ (1,0) [0|0] "" X
 SG_ APS_w230_alcUltrasoundBlocked: 37|1@1+ (1,0) [0|0] "" X
 SG_ APS_w231_idfEvent: 38|1@1+ (1,0) [0|0] "" X

BO_ 283 ASD_A2: 5 ETH
 SG_ ASD_A2_Checksum: 32|8@1+ (1,0) [0|0] "" X
 SG_ ASD_A2_Counter: 20|4@1+ (1,0) [0|0] "" X
 SG_ CompRun: 4|1@1+ (1,0) [0|0] "" X
 SG_ CurrentLevel: 16|3@1+ (1,0) [0|0] "" X
 SG_ EAS_HighLevelLamp: 26|1@1+ (1,0) [0|0] "" X
 SG_ EAS_JackModeLamp: 27|1@1+ (1,0) [0|0] "" X
 SG_ EAS_LevelingNotAllowed: 30|1@1+ (1,0) [0|0] "" X
 SG_ EAS_LevelingNotPossible: 29|1@1+ (1,0) [0|0] "" X
 SG_ EAS_LowLevelLamp: 24|1@1+ (1,0) [0|0] "" X
 SG_ EAS_NormalLevelLamp: 25|1@1+ (1,0) [0|0] "" X
 SG_ EAS_Req_ESP: 9|1@1+ (1,0) [0|0] "" X
 SG_ EAS_Req_VLimit: 8|1@1+ (1,0) [0|0] "" X
 SG_ EAS_VeryHighLevelLamp: 28|1@1+ (1,0) [0|0] "" X
 SG_ EAS_VeryLowLevelLamp: 31|1@1+ (1,0) [0|0] "" X
 SG_ EAS_extremeHighLevel: 2|1@1+ (1,0) [0|0] "" X
 SG_ EAS_extremeLowLevel: 3|1@1+ (1,0) [0|0] "" X
 SG_ EAS_reqReduceSpeedDisp: 10|1@1+ (1,0) [0|0] "" X
 SG_ LC_LimpHomeMode: 5|3@1- (1,0) [0|0] "" X
 SG_ SysDisabled: 11|1@1+ (1,0) [0|0] "" X
 SG_ TargetLevel: 12|3@1+ (1,0) [0|0] "" X
 SG_ Wala_LC_red: 0|1@1+ (1,0) [0|0] "" X
 SG_ Wala_LC_yel: 1|1@1+ (1,0) [0|0] "" X

BO_ 1297 BCCEN_info: 8 ETH
 SG_ BCCEN_infoIndex M: 0|8@1+ (1,0) [0|0] "" X
 SG_ BCCEN_infoBuildType m10: 8|8@1+ (1,0) [0|0] "" X
 SG_ BCCEN_infoBuildConfigID m10: 16|16@1+ (1,0) [0|0] "" X
 SG_ BCCEN_infoHardwareID m10: 32|16@1+ (1,0) [0|0] "" X
 SG_ BCCEN_infoComponentID m10: 48|16@1+ (1,0) [0|0] "" X
 SG_ BCCEN_infoPcbaID m11: 16|8@1+ (1,0) [0|0] "" X
 SG_ BCCEN_infoAssemblyID m11: 24|8@1+ (1,0) [0|0] "INTEGRAL" X
 SG_ BCCEN_infoUsageID m11: 32|16@1+ (1,0) [0|0] "" X
 SG_ BCCEN_infoSubUsageID m11: 48|16@1+ (1,0) [0|0] "" X
 SG_ BCCEN_infoApplicationCRC m13: 32|32@1+ (1,0) [0|0] "" X
 SG_ BCCEN_infoBootSvnRev m14: 8|24@1+ (1,0) [0|0] "" X
 SG_ BCCEN_infoSubcomponent1 m16: 16|32@1+ (1,0) [0|0] "" X
 SG_ BCCEN_infoAppGitHashBytes m17: 10|54@1+ (4,0) [0|0] "" X
 SG_ BCCEN_infoBootGitHashBytes m18: 10|54@1+ (4,0) [0|0] "" X
 SG_ BCCEN_infoPlatformType m19: 8|8@1+ (1,0) [0|0] "" X
 SG_ BCCEN_infoBootUdsProtoVersion m20: 8|8@1+ (1,0) [0|0] "" X
 SG_ BCCEN_infoBootloaderCRC m20: 32|32@1+ (1,0) [0|0] "" X
 SG_ BCCEN_infoSubcomponent2 m23: 16|32@1+ (1,0) [0|0] "" X
 SG_ BCCEN_infoSubcomponent3 m24: 16|32@1+ (1,0) [0|0] "" X
 SG_ BCCEN_infoSubcomponent4 m31: 16|32@1+ (1,0) [0|0] "" X

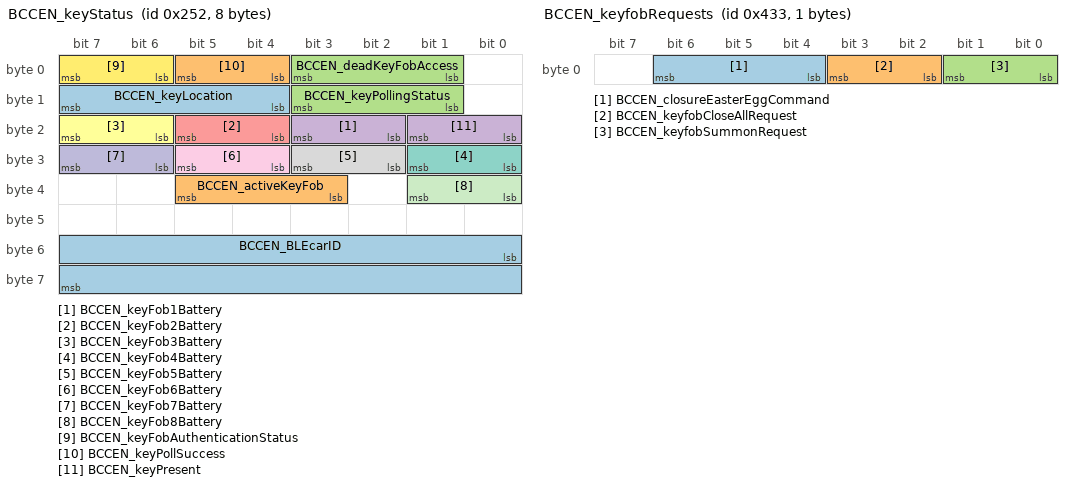
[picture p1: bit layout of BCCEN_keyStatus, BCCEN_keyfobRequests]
BO_ 594 BCCEN_keyStatus: 8 ETH
 SG_ BCCEN_BLEcarID: 48|16@1+ (1,0) [0|0] "" X
 SG_ BCCEN_activeKeyFob: 35|3@1+ (1,0) [0|0] "" X
 SG_ BCCEN_deadKeyFobAccess: 1|3@1+ (1,0) [0|0] "" X
 SG_ BCCEN_keyFob1Battery: 18|2@1+ (1,0) [0|0] "" X
 SG_ BCCEN_keyFob2Battery: 20|2@1+ (1,0) [0|0] "" X
 SG_ BCCEN_keyFob3Battery: 22|2@1+ (1,0) [0|0] "" X
 SG_ BCCEN_keyFob4Battery: 24|2@1+ (1,0) [0|0] "" X
 SG_ BCCEN_keyFob5Battery: 26|2@1+ (1,0) [0|0] "" X
 SG_ BCCEN_keyFob6Battery: 28|2@1+ (1,0) [0|0] "" X
 SG_ BCCEN_keyFob7Battery: 30|2@1+ (1,0) [0|0] "" X
 SG_ BCCEN_keyFob8Battery: 32|2@1+ (1,0) [0|0] "" X
 SG_ BCCEN_keyFobAuthenticationStatus: 6|2@1+ (1,0) [0|0] "" X
 SG_ BCCEN_keyLocation: 12|4@1+ (1,0) [0|0] "" X
 SG_ BCCEN_keyPollSuccess: 4|2@1+ (1,0) [0|0] "" X
 SG_ BCCEN_keyPollingStatus: 9|3@1+ (1,0) [0|0] "" X
 SG_ BCCEN_keyPresent: 16|2@1+ (1,0) [0|0] "" X

BO_ 1533 BCCEN_keyVersionInfo: 8 ETH
 SG_ BCCEN_keyVersionInfoIndex M: 0|8@1+ (1,0) [0|0] "" X
 SG_ BCCEN_key1HardwareID m0: 8|8@1+ (1,0) [0|0] "" X
 SG_ BCCEN_key1SEMajorVersion m0: 16|8@1+ (1,0) [0|0] "" X
 SG_ BCCEN_key1SEMinorVersion m0: 24|8@1+ (1,0) [0|0] "" X
 SG_ BCCEN_key1LFVersion m1: 8|32@1+ (1,0) [0|0] "" X
 SG_ BCCEN_key1ApplicationGitHash m2: 8|32@1+ (1,0) [0|0] "" X
 SG_ BCCEN_key1BootloaderGitHash m3: 8|32@1+ (1,0) [0|0] "" X
 SG_ BCCEN_key1ApplicationCRC m4: 8|16@1+ (1,0) [0|0] "" X
 SG_ BCCEN_key1BootloaderCRC m4: 24|16@1+ (1,0) [0|0] "" X
 SG_ BCCEN_key2HardwareID m5: 8|8@1+ (1,0) [0|0] "" X
 SG_ BCCEN_key2SEMajorVersion m5: 16|8@1+ (1,0) [0|0] "" X
 SG_ BCCEN_key2SEMinorVersion m5: 24|8@1+ (1,0) [0|0] "" X
 SG_ BCCEN_key2LFVersion m6: 8|32@1+ (1,0) [0|0] "" X
 SG_ BCCEN_key2ApplicationGitHash m7: 8|32@1+ (1,0) [0|0] "" X
 SG_ BCCEN_key2BootloaderGitHash m8: 8|32@1+ (1,0) [0|0] "" X
 SG_ BCCEN_key2ApplicationCRC m9: 8|16@1+ (1,0) [0|0] "" X
 SG_ BCCEN_key2BootloaderCRC m9: 24|16@1+ (1,0) [0|0] "" X
 SG_ BCCEN_key3HardwareID m10: 8|8@1+ (1,0) [0|0] "" X
 SG_ BCCEN_key3SEMajorVersion m10: 16|8@1+ (1,0) [0|0] "" X
 SG_ BCCEN_key3SEMinorVersion m10: 24|8@1+ (1,0) [0|0] "" X
 SG_ BCCEN_key3LFVersion m11: 8|32@1+ (1,0) [0|0] "" X
 SG_ BCCEN_key3ApplicationGitHash m12: 8|32@1+ (1,0) [0|0] "" X
 SG_ BCCEN_key3BootloaderGitHash m13: 8|32@1+ (1,0) [0|0] "" X
 SG_ BCCEN_key3ApplicationCRC m14: 8|16@1+ (1,0) [0|0] "" X
 SG_ BCCEN_key3BootloaderCRC m14: 24|16@1+ (1,0) [0|0] "" X
 SG_ BCCEN_key4HardwareID m15: 8|8@1+ (1,0) [0|0] "" X
 SG_ BCCEN_key4SEMajorVersion m15: 16|8@1+ (1,0) [0|0] "" X
 SG_ BCCEN_key4SEMinorVersion m15: 24|8@1+ (1,0) [0|0] "" X
 SG_ BCCEN_key4LFVersion m16: 8|32@1+ (1,0) [0|0] "" X
 SG_ BCCEN_key4ApplicationGitHash m17: 8|32@1+ (1,0) [0|0] "" X
 SG_ BCCEN_key4BootloaderGitHash m18: 8|32@1+ (1,0) [0|0] "" X
 SG_ BCCEN_key4ApplicationCRC m19: 8|16@1+ (1,0) [0|0] "" X
 SG_ BCCEN_key4BootloaderCRC m19: 24|16@1+ (1,0) [0|0] "" X
 SG_ BCCEN_key5HardwareID m20: 8|8@1+ (1,0) [0|0] "" X
 SG_ BCCEN_key5SEMajorVersion m20: 16|8@1+ (1,0) [0|0] "" X
 SG_ BCCEN_key5SEMinorVersion m20: 24|8@1+ (1,0) [0|0] "" X
 SG_ BCCEN_key5LFVersion m21: 8|32@1+ (1,0) [0|0] "" X
 SG_ BCCEN_key5ApplicationGitHash m22: 8|32@1+ (1,0) [0|0] "" X
 SG_ BCCEN_key5BootloaderGitHash m23: 8|32@1+ (1,0) [0|0] "" X
 SG_ BCCEN_key5ApplicationCRC m24: 8|16@1+ (1,0) [0|0] "" X
 SG_ BCCEN_key5BootloaderCRC m24: 24|16@1+ (1,0) [0|0] "" X
 SG_ BCCEN_key6HardwareID m25: 8|8@1+ (1,0) [0|0] "" X
 SG_ BCCEN_key6SEMajorVersion m25: 16|8@1+ (1,0) [0|0] "" X
 SG_ BCCEN_key6SEMinorVersion m25: 24|8@1+ (1,0) [0|0] "" X
 SG_ BCCEN_key6LFVersion m26: 8|32@1+ (1,0) [0|0] "" X
 SG_ BCCEN_key6ApplicationGitHash m27: 8|32@1+ (1,0) [0|0] "" X
 SG_ BCCEN_key6BootloaderGitHash m28: 8|32@1+ (1,0) [0|0] "" X
 SG_ BCCEN_key6ApplicationCRC m29: 8|16@1+ (1,0) [0|0] "" X
 SG_ BCCEN_key6BootloaderCRC m29: 24|16@1+ (1,0) [0|0] "" X
 SG_ BCCEN_key7HardwareID m30: 8|8@1+ (1,0) [0|0] "" X
 SG_ BCCEN_key7SEMajorVersion m30: 16|8@1+ (1,0) [0|0] "" X
 SG_ BCCEN_key7SEMinorVersion m30: 24|8@1+ (1,0) [0|0] "" X
 SG_ BCCEN_key7LFVersion m31: 8|32@1+ (1,0) [0|0] "" X
 SG_ BCCEN_key7ApplicationGitHash m32: 8|32@1+ (1,0) [0|0] "" X
 SG_ BCCEN_key7BootloaderGitHash m33: 8|32@1+ (1,0) [0|0] "" X
 SG_ BCCEN_key7ApplicationCRC m34: 8|16@1+ (1,0) [0|0] "" X
 SG_ BCCEN_key7BootloaderCRC m34: 24|16@1+ (1,0) [0|0] "" X
 SG_ BCCEN_key8HardwareID m35: 8|8@1+ (1,0) [0|0] "" X
 SG_ BCCEN_key8SEMajorVersion m35: 16|8@1+ (1,0) [0|0] "" X
 SG_ BCCEN_key8SEMinorVersion m35: 24|8@1+ (1,0) [0|0] "" X
 SG_ BCCEN_key8LFVersion m36: 8|32@1+ (1,0) [0|0] "" X
 SG_ BCCEN_key8ApplicationGitHash m37: 8|32@1+ (1,0) [0|0] "" X
 SG_ BCCEN_key8BootloaderGitHash m38: 8|32@1+ (1,0) [0|0] "" X
 SG_ BCCEN_key8ApplicationCRC m39: 8|16@1+ (1,0) [0|0] "" X
 SG_ BCCEN_key8BootloaderCRC m39: 24|16@1+ (1,0) [0|0] "" X
 SG_ BCCEN_blekeyTypeAStagedGitHash m40: 10|54@1+ (4,0) [0|0] "" X
 SG_ BCCEN_bckeyLFSEStagedGitHash m41: 10|54@1+ (4,0) [0|0] "" X
 SG_ BCCEN_bcSEStagedGitHash m42: 10|54@1+ (4,0) [0|0] "" X
 SG_ BCCEN_blekeyTypeAStagedHWID m43: 32|16@1+ (1,0) [0|0] "" X
 SG_ BCCEN_blekeyTypeAStagedCompID m43: 48|16@1+ (1,0) [0|0] "" X
 SG_ BCCEN_bckeyLfStagedCRC m44: 16|16@1+ (1,0) [0|0] "" X
 SG_ BCCEN_bckeyLfStagedHWID m44: 32|16@1+ (1,0) [0|0] "" X
 SG_ BCCEN_bckeyLfStagedCompID m44: 48|16@1+ (1,0) [0|0] "" X
 SG_ BCCEN_bcSEStagedCRC m45: 16|32@1+ (1,0) [0|0] "" X
 SG_ BCCEN_bcSEStagedHWID m45: 48|16@1+ (1,0) [0|0] "" X

BO_ 1075 BCCEN_keyfobRequests: 1 ETH
 SG_ BCCEN_closureEasterEggCommand: 4|3@1+ (1,0) [0|0] "" X
 SG_ BCCEN_keyfobCloseAllRequest: 2|2@1+ (1,0) [0|0] "" X
 SG_ BCCEN_keyfobSummonRequest: 0|2@1+ (1,0) [0|0] "" X

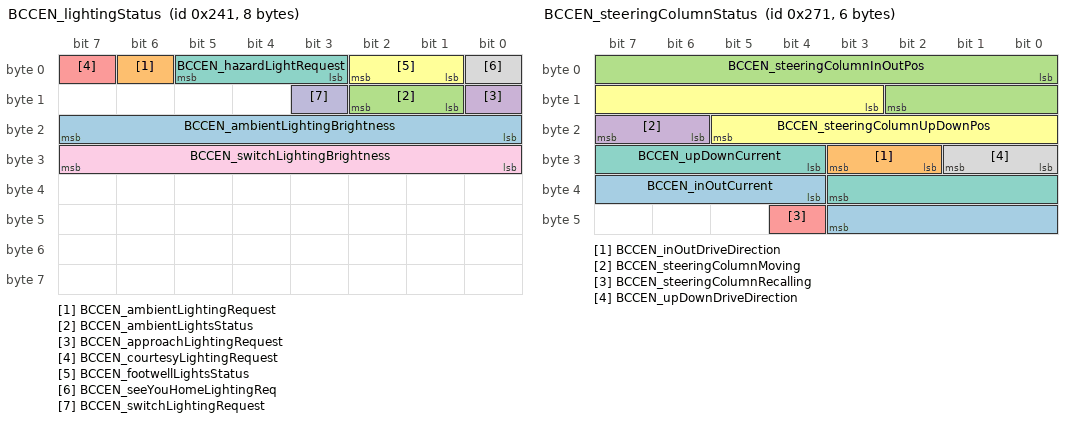
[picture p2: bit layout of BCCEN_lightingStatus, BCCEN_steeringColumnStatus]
BO_ 577 BCCEN_lightingStatus: 8 ETH
 SG_ BCCEN_ambientLightingBrightness: 16|8@1+ (0.5,0) [0|0] "%" X
 SG_ BCCEN_ambientLightingRequest: 6|1@1+ (1,0) [0|0] "" X
 SG_ BCCEN_ambientLightsStatus: 9|2@1+ (1,0) [0|0] "" X
 SG_ BCCEN_approachLightingRequest: 8|1@1+ (1,0) [0|0] "" X
 SG_ BCCEN_courtesyLightingRequest: 7|1@1+ (1,0) [0|0] "" X
 SG_ BCCEN_footwellLightsStatus: 1|2@1+ (1,0) [0|0] "" X
 SG_ BCCEN_hazardLightRequest: 3|3@1+ (1,0) [0|0] "" X
 SG_ BCCEN_seeYouHomeLightingReq: 0|1@1+ (1,0) [0|0] "" X
 SG_ BCCEN_switchLightingBrightness: 24|8@1+ (0.5,0) [0|0] "%" X
 SG_ BCCEN_switchLightingRequest: 11|1@1+ (1,0) [0|0] "" X

BO_ 517 BCCEN_status: 8 ETH
 SG_ BCCEN_accRailStatus: 63|1@1+ (1,0) [0|0] "" X
 SG_ BCCEN_alarmStatus: 0|4@1+ (1,0) [0|0] "" X
 SG_ BCCEN_anyKeyfobButtonPressed: 54|1@1+ (1,0) [0|0] "" X
 SG_ BCCEN_batteryBackedSirenStatus: 24|2@1+ (1,0) [0|0] "" X
 SG_ BCCEN_brakePressed: 58|1@1+ (1,0) [0|0] "" X
 SG_ BCCEN_chargePortRequest: 8|2@1+ (1,0) [0|0] "" X
 SG_ BCCEN_crashStatus: 16|2@1+ (1,0) [0|0] "" X
 SG_ BCCEN_driveRailStatus: 62|1@1+ (1,0) [0|0] "" X
 SG_ BCCEN_driverFrontLockStatus: 48|1@1+ (1,0) [0|0] "" X
 SG_ BCCEN_driverPresent: 52|1@1+ (1,0) [0|0] "" X
 SG_ BCCEN_driverRearLockStatus: 49|1@1+ (1,0) [0|0] "" X
 SG_ BCCEN_falconLeftRequest: 34|2@1+ (1,0) [0|0] "" X
 SG_ BCCEN_falconRightRequest: 36|2@1+ (1,0) [0|0] "" X
 SG_ BCCEN_frontHoodCommand: 44|2@1+ (1,0) [0|0] "" X
 SG_ BCCEN_frunkLockStatus: 61|1@1+ (1,0) [0|0] "" X
 SG_ BCCEN_gloveBoxStatus: 56|2@1+ (1,0) [0|0] "" X
 SG_ BCCEN_gloveBoxSwitchStatus: 29|3@1+ (1,0) [0|0] "" X
 SG_ BCCEN_hvacRailStatus: 60|1@1+ (1,0) [0|0] "" X
 SG_ BCCEN_indicatorLeftRequest: 40|2@1+ (1,0) [0|0] "" X
 SG_ BCCEN_indicatorRightRequest: 42|2@1+ (1,0) [0|0] "" X
 SG_ BCCEN_intrusionTiltSensorStatus: 18|2@1+ (1,0) [0|0] "" X
 SG_ BCCEN_lastRKEKeyChannel: 13|3@1+ (1,0) [0|0] "" X
 SG_ BCCEN_lockRejected: 53|1@1+ (1,0) [0|0] "" X
 SG_ BCCEN_lockRequestType: 20|4@1+ (1,0) [0|0] "" X
 SG_ BCCEN_numberOfKeysPaired: 4|4@1+ (1,0) [0|0] "" X
 SG_ BCCEN_passengerFrontLockStatus: 50|1@1+ (1,0) [0|0] "" X
 SG_ BCCEN_passengerRearLockStatus: 51|1@1+ (1,0) [0|0] "" X
 SG_ BCCEN_rearTrunkRequest: 38|2@1+ (1,0) [0|0] "" X
 SG_ BCCEN_remoteAccessState: 46|2@1+ (1,0) [0|0] "" X
 SG_ BCCEN_rkeUnlockRequiredForStart: 55|1@1+ (1,0) [0|0] "" X
 SG_ BCCEN_trunkLockStatus: 59|1@1+ (1,0) [0|0] "" X
 SG_ BCCEN_vehicleLockStatus: 10|3@1+ (1,0) [0|0] "" X
 SG_ BCCEN_windowControlAvailable: 32|2@1+ (1,0) [0|0] "" X
 SG_ BCCEN_windowRequest: 26|3@1+ (1,0) [0|0] "" X

BO_ 938 BCCEN_status2: 8 ETH
 SG_ BCCEN_SBCTemperature: 0|8@1- (1,0) [0|0] "C" X
 SG_ BCCEN_SEMajorVersion: 20|3@1+ (1,0) [0|0] "" X
 SG_ BCCEN_SEMinorVersion: 23|3@1+ (1,0) [0|0] "" X
 SG_ BCCEN_autoPairingStatus: 38|3@1+ (1,0) [0|0] "" X
 SG_ BCCEN_autoUpdateFault: 52|4@1+ (1,0) [0|0] "" X
 SG_ BCCEN_autoUpdateStatus: 48|4@1+ (1,0) [0|0] "" X
 SG_ BCCEN_autoUpdaterFile: 56|1@1+ (1,0) [0|0] "" X
 SG_ BCCEN_closeAllStatus: 58|2@1+ (1,0) [0|0] "" X
 SG_ BCCEN_connection1Status: 26|3@1+ (1,0) [0|0] "" X
 SG_ BCCEN_connection2Status: 29|3@1+ (1,0) [0|0] "" X
 SG_ BCCEN_connection3Status: 32|3@1+ (1,0) [0|0] "" X
 SG_ BCCEN_immobilizerState: 16|4@1+ (1,0) [0|0] "" X
 SG_ BCCEN_keyUpdatePercentComplete: 41|7@1+ (1,0) [0|0] "" X
 SG_ BCCEN_pairingStep: 35|3@1+ (1,0) [0|0] "" X
 SG_ BCCEN_parkECUPowerStatus: 62|2@1+ (1,0) [0|0] "" X
 SG_ BCCEN_remoteControlLockedOut: 57|1@1+ (1,0) [0|0] "" X
 SG_ BCCEN_vehicle12V: 8|8@1+ (0.1,0) [0|0] "V" X

BO_ 625 BCCEN_steeringColumnStatus: 6 ETH
 SG_ BCCEN_inOutCurrent: 36|8@1+ (0.1,0) [0|0] "A" X
 SG_ BCCEN_inOutDriveDirection: 26|2@1+ (1,0) [0|0] "" X
 SG_ BCCEN_steeringColumnInOutPos: 0|11@1- (1,0) [0|0] "INTEGRAL" X
 SG_ BCCEN_steeringColumnMoving: 22|2@1+ (1,0) [0|0] "" X
 SG_ BCCEN_steeringColumnRecalling: 44|1@1+ (1,0) [0|0] "" X
 SG_ BCCEN_steeringColumnUpDownPos: 11|11@1- (1,0) [0|0] "INTEGRAL" X
 SG_ BCCEN_upDownCurrent: 28|8@1+ (0.1,0) [0|0] "A" X
 SG_ BCCEN_upDownDriveDirection: 24|2@1+ (1,0) [0|0] "" X

BO_ 1681 BCCEN_udsResponse: 8 ETH
 SG_ BCCEN_udsResponseData_H: 0|32@0+ (1,0) [0|0] "" X
 SG_ BCCEN_udsResponseData_L: 32|32@0+ (1,0) [0|0] "" X

BO_ 769 BCCEN_warningMatrix1: 8 ETH
 SG_ BCCEN_w001_WatchdogReset: 0|1@1+ (1,0) [0|0] "" X
 SG_ BCCEN_w002_PowerLossReset: 1|1@1+ (1,0) [0|0] "" X
 SG_ BCCEN_w003_SWAssertion: 2|1@1+ (1,0) [0|0] "" X
 SG_ BCCEN_w004_CANMIA: 3|1@1+ (1,0) [0|0] "" X
 SG_ BCCEN_w005_CANHighError: 4|1@1+ (1,0) [0|0] "" X
 SG_ BCCEN_w006_CANLowError: 5|1@1+ (1,0) [0|0] "" X
 SG_ BCCEN_w007_LINTimeout: 6|1@1+ (1,0) [0|0] "" X
 SG_ BCCEN_w008_LIN2Error: 7|1@1+ (1,0) [0|0] "" X
 SG_ BCCEN_w009_LIN3Error: 8|1@1+ (1,0) [0|0] "" X
 SG_ BCCEN_w010_ExtSupplyVoltError: 9|1@1+ (1,0) [0|0] "" X
 SG_ BCCEN_w011_ECUSupplyVoltError: 10|1@1+ (1,0) [0|0] "" X
 SG_ BCCEN_w012_CPUReset: 11|1@1+ (1,0) [0|0] "" X
 SG_ BCCEN_w013_Shared13: 12|1@1+ (1,0) [0|0] "" X
 SG_ BCCEN_w014_BridgeFault: 13|1@1+ (1,0) [0|0] "" X
 SG_ BCCEN_w015_NVMMAlert: 14|1@1+ (1,0) [0|0] "" X
 SG_ BCCEN_w016_MessageTimingError: 15|1@1+ (1,0) [0|0] "" X
 SG_ BCCEN_w017_AwakeForTooLong: 16|1@1+ (1,0) [0|0] "" X
 SG_ BCCEN_w018_ADCError: 17|1@1+ (1,0) [0|0] "" X
 SG_ BCCEN_w019_I2CError: 18|1@1+ (1,0) [0|0] "" X
 SG_ BCCEN_w020_PWMError: 19|1@1+ (1,0) [0|0] "" X
 SG_ BCCEN_w021_TaskSchedulerError: 20|1@1+ (1,0) [0|0] "" X
 SG_ BCCEN_w022_TaskInitError: 21|1@1+ (1,0) [0|0] "" X
 SG_ BCCEN_w023_SleepError: 22|1@1+ (1,0) [0|0] "" X
 SG_ BCCEN_w024_WakeError: 23|1@1+ (1,0) [0|0] "" X
 SG_ BCCEN_w025_CrashEvent: 24|1@1+ (1,0) [0|0] "" X
 SG_ BCCEN_w026_FlashMemoryError: 25|1@1+ (1,0) [0|0] "" X
 SG_ BCCEN_w027_NVRAMCorruption: 26|1@1+ (1,0) [0|0] "" X
 SG_ BCCEN_w028_NVRAMNotResponding: 27|1@1+ (1,0) [0|0] "" X
 SG_ BCCEN_w029_NVRAMUninitialized: 28|1@1+ (1,0) [0|0] "" X
 SG_ BCCEN_w035_UHFAntennaError: 34|1@1+ (1,0) [0|0] "" X
 SG_ BCCEN_w036_BLEAntenna0Error: 35|1@1+ (1,0) [0|0] "" X
 SG_ BCCEN_w037_KeyAuthError: 36|1@1+ (1,0) [0|0] "" X
 SG_ BCCEN_w038_KeyfobLowBattery: 37|1@1+ (1,0) [0|0] "" X
 SG_ BCCEN_w039_transponderAccess: 38|1@1+ (1,0) [0|0] "" X
 SG_ BCCEN_w040_BaseStationCommError: 39|1@1+ (1,0) [0|0] "" X
 SG_ BCCEN_w041_KeyfobRSSIError: 40|1@1+ (1,0) [0|0] "" X
 SG_ BCCEN_w042_SecureElementError: 41|1@1+ (1,0) [0|0] "" X
 SG_ BCCEN_w043_SecureElementFailure: 42|1@1+ (1,0) [0|0] "" X
 SG_ BCCEN_w044_BCCENSEVerNotLatest: 43|1@1+ (1,0) [0|0] "" X
 SG_ BCCEN_w045_BaseStationFWUpdate: 44|1@1+ (1,0) [0|0] "" X
 SG_ BCCEN_w046_KeyfobCommError: 45|1@1+ (1,0) [0|0] "" X
 SG_ BCCEN_w047_KeyfobButtonError: 46|1@1+ (1,0) [0|0] "" X
 SG_ BCCEN_w048_KeyfobCoilError: 47|1@1+ (1,0) [0|0] "" X
 SG_ BCCEN_w049_BrakePedalMismatch: 48|1@1+ (1,0) [0|0] "" X
 SG_ BCCEN_w050_RearFootwellIllum: 49|1@1+ (1,0) [0|0] "" X
 SG_ BCCEN_w051_CourtesyLightingReq: 50|1@1+ (1,0) [0|0] "" X
 SG_ BCCEN_w052_GloveBoxSwitchLED: 51|1@1+ (1,0) [0|0] "" X
 SG_ BCCEN_w053_RLSError: 52|1@1+ (1,0) [0|0] "" X
 SG_ BCCEN_w054_RLSCommError: 53|1@1+ (1,0) [0|0] "" X
 SG_ BCCEN_w055_HazardSwitchLED: 54|1@1+ (1,0) [0|0] "" X
 SG_ BCCEN_w056_SeeYouHomeLighting: 55|1@1+ (1,0) [0|0] "" X
 SG_ BCCEN_w057_ApproachLighting: 56|1@1+ (1,0) [0|0] "" X
 SG_ BCCEN_w058_HornFault: 57|1@1+ (1,0) [0|0] "" X
 SG_ BCCEN_w059_SteeringColumnMIA: 58|1@1+ (1,0) [0|0] "" X
 SG_ BCCEN_w060_WiperECUError: 59|1@1+ (1,0) [0|0] "" X
 SG_ BCCEN_w061_WiperLINError: 60|1@1+ (1,0) [0|0] "" X
 SG_ BCCEN_w062_WiperCommError: 61|1@1+ (1,0) [0|0] "" X
 SG_ BCCEN_w063_WiperParkError: 62|1@1+ (1,0) [0|0] "" X
 SG_ BCCEN_w064_AccRailError: 63|1@1+ (1,0) [0|0] "" X

BO_ 785 BCCEN_warningMatrix2: 8 ETH
 SG_ BCCEN_w065_DriverDetection: 0|1@1+ (1,0) [0|0] "" X
 SG_ BCCEN_w066_AlarmReporting: 1|1@1+ (1,0) [0|0] "" X
 SG_ BCCEN_w067_ValetMode: 2|1@1+ (1,0) [0|0] "" X
 SG_ BCCEN_w068_GloveBoxSwitch: 3|1@1+ (1,0) [0|0] "" X
 SG_ BCCEN_w069_GloveBoxLight: 4|1@1+ (1,0) [0|0] "" X
 SG_ BCCEN_w070_RemoteAuthFail: 5|1@1+ (1,0) [0|0] "" X
 SG_ BCCEN_w071_IntrusionCommError: 6|1@1+ (1,0) [0|0] "" X
 SG_ BCCEN_w072_SCMotorError: 7|1@1+ (1,0) [0|0] "" X
 SG_ BCCEN_w073_SteeringColumnMemory: 8|1@1+ (1,0) [0|0] "" X
 SG_ BCCEN_w074_SirenCommError: 9|1@1+ (1,0) [0|0] "" X
 SG_ BCCEN_w075_SCUncalibrated: 10|1@1+ (1,0) [0|0] "" X
 SG_ BCCEN_w076_HVACRailError: 11|1@1+ (1,0) [0|0] "" X
 SG_ BCCEN_w077_DriveRailError: 12|1@1+ (1,0) [0|0] "" X
 SG_ BCCEN_w078_GloveBoxHSD: 13|1@1+ (1,0) [0|0] "" X
 SG_ BCCEN_w079_DvrSideCfgMismatch: 14|1@1+ (1,0) [0|0] "" X
 SG_ BCCEN_w080_GloveBoxLatch: 15|1@1+ (1,0) [0|0] "" X
 SG_ BCCEN_w081_AmbientLighting: 16|1@1+ (1,0) [0|0] "" X
 SG_ BCCEN_w082_FrontFootwellIllum: 17|1@1+ (1,0) [0|0] "" X
 SG_ BCCEN_w083_CourtesyLighting: 18|1@1+ (1,0) [0|0] "" X
 SG_ BCCEN_w084_KeyfobSEVersionTooOld: 19|1@1+ (1,0) [0|0] "" X
 SG_ BCCEN_w085_UHFReceiverReset: 20|1@1+ (1,0) [0|0] "" X
 SG_ BCCEN_w086_UHFResponseTimeout: 21|1@1+ (1,0) [0|0] "" X
 SG_ BCCEN_w087_UHFSpiTimeout: 22|1@1+ (1,0) [0|0] "" X
 SG_ BCCEN_w088_UHFRadioBadState: 23|1@1+ (1,0) [0|0] "" X
 SG_ BCCEN_w089_AutomaticPairAttempt: 24|1@1+ (1,0) [0|0] "" X
 SG_ BCCEN_w090_CrashUnlockError: 25|1@1+ (1,0) [0|0] "" X
 SG_ BCCEN_w091_CrashStateMismatch: 26|1@1+ (1,0) [0|0] "" X
 SG_ BCCEN_w092_AmbientTmpSensor: 27|1@1+ (1,0) [0|0] "" X
 SG_ BCCEN_w093_OTPError: 28|1@1+ (1,0) [0|0] "" X
 SG_ BCCEN_w094_transponderKeyNotSet: 29|1@1+ (1,0) [0|0] "" X
 SG_ BCCEN_w095_AlarmTriggered: 30|1@1+ (1,0) [0|0] "" X
 SG_ BCCEN_w096_UHFPLLNotlocked: 31|1@1+ (1,0) [0|0] "" X
 SG_ BCCEN_w097_UHFCalibrationFail: 32|1@1+ (1,0) [0|0] "" X
 SG_ BCCEN_w098_UHFSleepRequestFail: 33|1@1+ (1,0) [0|0] "" X
 SG_ BCCEN_w099_UHFWakeRequestFail: 34|1@1+ (1,0) [0|0] "" X
 SG_ BCCEN_w100_TrailerAuxRailError: 35|1@1+ (1,0) [0|0] "" X
 SG_ BCCEN_w102_CloseAllFlicker: 37|1@1+ (1,0) [0|0] "" X
 SG_ BCCEN_w103_KeyfobUpdateFailure: 38|1@1+ (1,0) [0|0] "" X
 SG_ BCCEN_w104_KeyfobUpdateSuccess: 39|1@1+ (1,0) [0|0] "" X
 SG_ BCCEN_w105_ECUDebugMode: 40|1@1+ (1,0) [0|0] "" X
 SG_ BCCEN_w106_HighCPULoad: 41|1@1+ (1,0) [0|0] "" X
 SG_ BCCEN_w107_HighStackUsage: 42|1@1+ (1,0) [0|0] "" X
 SG_ BCCEN_w108_immobOperationFault: 43|1@1+ (1,0) [0|0] "" X
 SG_ BCCEN_w109_LFBootloading: 44|1@1+ (1,0) [0|0] "" X
 SG_ BCCEN_w110_LFAntErrorPassenger: 45|1@1+ (1,0) [0|0] "" X
 SG_ BCCEN_w111_LFAntErrorFront: 46|1@1+ (1,0) [0|0] "" X
 SG_ BCCEN_w112_LFAntErrorRear: 47|1@1+ (1,0) [0|0] "" X
 SG_ BCCEN_w113_LFAntErrorCenter: 48|1@1+ (1,0) [0|0] "" X
 SG_ BCCEN_w114_LFAntErrorDriver: 49|1@1+ (1,0) [0|0] "" X
 SG_ BCCEN_w115_LF_MAX2153_MIA: 50|1@1+ (1,0) [0|0] "" X
 SG_ BCCEN_w116_SeeYouHomeNoResponse: 51|1@1+ (1,0) [0|0] "" X
 SG_ BCCEN_w117_BLENotInReceivingMode: 52|1@1+ (1,0) [0|0] "" X
 SG_ BCCEN_w118_BLE1DeviceDiscoFail: 53|1@1+ (1,0) [0|0] "" X
 SG_ BCCEN_w119_BLE2DeviceDiscoFail: 54|1@1+ (1,0) [0|0] "" X
 SG_ BCCEN_w120_BLE3DeviceDiscoFail: 55|1@1+ (1,0) [0|0] "" X
 SG_ BCCEN_w121_BLE1FailedHeap: 56|1@1+ (1,0) [0|0] "" X
 SG_ BCCEN_w122_BLE2FailedHeap: 57|1@1+ (1,0) [0|0] "" X
 SG_ BCCEN_w123_BLE3FailedHeap: 58|1@1+ (1,0) [0|0] "" X
 SG_ BCCEN_w124_holidayParty: 59|1@1+ (1,0) [0|0] "" X
 SG_ BCCEN_w125_immobKeyNotGenerated: 60|1@1+ (1,0) [0|0] "" X
 SG_ BCCEN_w126_tooFewKeysPaired: 61|1@1+ (1,0) [0|0] "" X
 SG_ BCCEN_w127_VINNotLearnt: 62|1@1+ (1,0) [0|0] "" X
 SG_ BCCEN_w128_SENotLockedDown: 63|1@1+ (1,0) [0|0] "" X

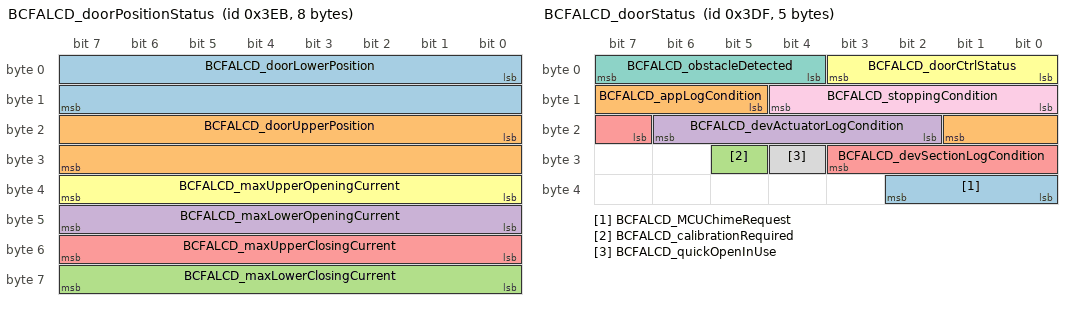
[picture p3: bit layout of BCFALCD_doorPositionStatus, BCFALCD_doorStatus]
BO_ 1003 BCFALCD_doorPositionStatus: 8 ETH
 SG_ BCFALCD_doorLowerPosition: 0|16@1- (0.00549325,0) [0|0] "deg" X
 SG_ BCFALCD_doorUpperPosition: 16|16@1- (0.00549325,0) [0|0] "deg" X
 SG_ BCFALCD_maxLowerClosingCurrent: 56|8@1- (0.2,0) [0|0] "A" X
 SG_ BCFALCD_maxLowerOpeningCurrent: 40|8@1- (0.2,0) [0|0] "A" X
 SG_ BCFALCD_maxUpperClosingCurrent: 48|8@1- (0.2,0) [0|0] "A" X
 SG_ BCFALCD_maxUpperOpeningCurrent: 32|8@1- (0.2,0) [0|0] "A" X

BO_ 991 BCFALCD_doorStatus: 5 ETH
 SG_ BCFALCD_MCUChimeRequest: 32|3@1+ (1,0) [0|0] "" X
 SG_ BCFALCD_appLogCondition: 13|5@1+ (1,0) [0|0] "" X
 SG_ BCFALCD_calibrationRequired: 29|1@1+ (1,0) [0|0] "" X
 SG_ BCFALCD_devActuatorLogCondition: 18|5@1+ (1,0) [0|0] "" X
 SG_ BCFALCD_devSectionLogCondition: 23|5@1+ (1,0) [0|0] "" X
 SG_ BCFALCD_doorCtrlStatus: 0|4@1+ (1,0) [0|0] "" X
 SG_ BCFALCD_obstacleDetected: 4|4@1+ (1,0) [0|0] "" X
 SG_ BCFALCD_quickOpenInUse: 28|1@1+ (1,0) [0|0] "" X
 SG_ BCFALCD_stoppingCondition: 8|5@1+ (1,0) [0|0] "" X

BO_ 1313 BCFALCD_info: 8 ETH
 SG_ BCFALCD_infoIndex M: 0|8@1+ (1,0) [0|0] "" X
 SG_ BCFALCD_infoBuildType m10: 8|8@1+ (1,0) [0|0] "" X
 SG_ BCFALCD_infoBuildConfigID m10: 16|16@1+ (1,0) [0|0] "" X
 SG_ BCFALCD_infoHardwareID m10: 32|16@1+ (1,0) [0|0] "" X
 SG_ BCFALCD_infoComponentID m10: 48|16@1+ (1,0) [0|0] "" X
 SG_ BCFALCD_infoPcbaID m11: 16|8@1+ (1,0) [0|0] "" X
 SG_ BCFALCD_infoAssemblyID m11: 24|8@1+ (1,0) [0|0] "INTEGRAL" X
 SG_ BCFALCD_infoUsageID m11: 32|16@1+ (1,0) [0|0] "" X
 SG_ BCFALCD_infoSubUsageID m11: 48|16@1+ (1,0) [0|0] "" X
 SG_ BCFALCD_infoApplicationCRC m13: 32|32@1+ (1,0) [0|0] "" X
 SG_ BCFALCD_infoBootSvnRev m14: 8|24@1+ (1,0) [0|0] "" X
 SG_ BCFALCD_infoAppGitHashBytes m17: 10|54@1+ (4,0) [0|0] "" X
 SG_ BCFALCD_infoBootGitHashBytes m18: 10|54@1+ (4,0) [0|0] "" X
 SG_ BCFALCD_infoPlatformType m19: 8|8@1+ (1,0) [0|0] "" X
 SG_ BCFALCD_infoBootUdsProtoVersion m20: 8|8@1+ (1,0) [0|0] "" X
 SG_ BCFALCD_infoBootloaderCRC m20: 32|32@1+ (1,0) [0|0] "" X

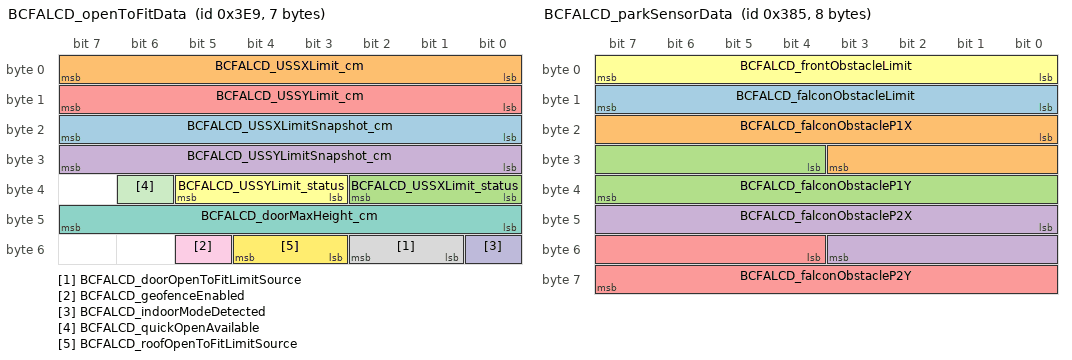
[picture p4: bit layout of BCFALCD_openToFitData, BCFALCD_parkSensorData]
BO_ 1001 BCFALCD_openToFitData: 7 ETH
 SG_ BCFALCD_USSXLimitSnapshot_cm: 16|8@1+ (1,0) [0|0] "cm" X
 SG_ BCFALCD_USSXLimit_cm: 0|8@1+ (1,0) [0|0] "cm" X
 SG_ BCFALCD_USSXLimit_status: 32|3@1+ (1,0) [0|0] "" X
 SG_ BCFALCD_USSYLimitSnapshot_cm: 24|8@1+ (1,0) [0|0] "cm" X
 SG_ BCFALCD_USSYLimit_cm: 8|8@1+ (1,0) [0|0] "cm" X
 SG_ BCFALCD_USSYLimit_status: 35|3@1+ (1,0) [0|0] "" X
 SG_ BCFALCD_doorMaxHeight_cm: 40|8@1+ (1,0) [0|0] "cm" X
 SG_ BCFALCD_doorOpenToFitLimitSource: 49|2@1+ (1,0) [0|0] "" X
 SG_ BCFALCD_geofenceEnabled: 53|1@1+ (1,0) [0|0] "" X
 SG_ BCFALCD_indoorModeDetected: 48|1@1+ (1,0) [0|0] "" X
 SG_ BCFALCD_quickOpenAvailable: 38|1@1+ (1,0) [0|0] "" X
 SG_ BCFALCD_roofOpenToFitLimitSource: 51|2@1+ (1,0) [0|0] "" X

BO_ 901 BCFALCD_parkSensorData: 8 ETH
 SG_ BCFALCD_falconObstacleLimit: 8|8@1+ (1,0) [0|0] "cm" X
 SG_ BCFALCD_falconObstacleP1X: 16|12@1- (1,0) [0|0] "" X
 SG_ BCFALCD_falconObstacleP1Y: 28|12@1- (1,0) [0|0] "" X
 SG_ BCFALCD_falconObstacleP2X: 40|12@1- (1,0) [0|0] "" X
 SG_ BCFALCD_falconObstacleP2Y: 52|12@1- (1,0) [0|0] "" X
 SG_ BCFALCD_frontObstacleLimit: 0|8@1+ (1,0) [0|0] "cm" X

BO_ 1726 BCFALCD_udsResponse: 8 ETH
 SG_ BCFALCD_udsResponseData_H: 0|32@0+ (1,0) [0|0] "" X
 SG_ BCFALCD_udsResponseData_L: 32|32@0+ (1,0) [0|0] "" X

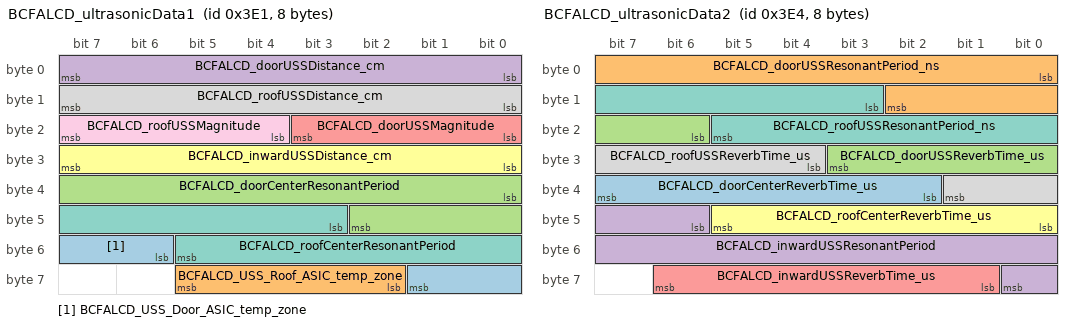
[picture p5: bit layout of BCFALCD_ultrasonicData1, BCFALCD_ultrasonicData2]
BO_ 993 BCFALCD_ultrasonicData1: 8 ETH
 SG_ BCFALCD_USS_Door_ASIC_temp_zone: 54|4@1+ (1,0) [0|0] "" X
 SG_ BCFALCD_USS_Roof_ASIC_temp_zone: 58|4@1+ (1,0) [0|0] "" X
 SG_ BCFALCD_doorCenterResonantPeriod: 32|11@1+ (25,0) [0|0] "ns" X
 SG_ BCFALCD_doorUSSDistance_cm: 0|8@1+ (1,0) [0|0] "cm" X
 SG_ BCFALCD_doorUSSMagnitude: 16|4@1+ (6.66667,0) [0|0] "%" X
 SG_ BCFALCD_inwardUSSDistance_cm: 24|8@1+ (1,0) [0|0] "cm" X
 SG_ BCFALCD_roofCenterResonantPeriod: 43|11@1+ (25,0) [0|0] "ns" X
 SG_ BCFALCD_roofUSSDistance_cm: 8|8@1+ (1,0) [0|0] "cm" X
 SG_ BCFALCD_roofUSSMagnitude: 20|4@1+ (6.66667,0) [0|0] "%" X

BO_ 996 BCFALCD_ultrasonicData2: 8 ETH
 SG_ BCFALCD_doorCenterReverbTime_us: 34|6@1+ (51.2,0) [0|0] "us" X
 SG_ BCFALCD_doorUSSResonantPeriod_ns: 0|11@1+ (25,0) [0|0] "ns" X
 SG_ BCFALCD_doorUSSReverbTime_us: 22|6@1+ (51.2,0) [0|0] "us" X
 SG_ BCFALCD_inwardUSSResonantPeriod: 46|11@1+ (25,0) [0|0] "ns" X
 SG_ BCFALCD_inwardUSSReverbTime_us: 57|6@1+ (51.2,0) [0|0] "us" X
 SG_ BCFALCD_roofCenterReverbTime_us: 40|6@1+ (51.2,0) [0|0] "us" X
 SG_ BCFALCD_roofUSSResonantPeriod_ns: 11|11@1+ (25,0) [0|0] "ns" X
 SG_ BCFALCD_roofUSSReverbTime_us: 28|6@1+ (51.2,0) [0|0] "us" X

BO_ 318 BCFALCD_warningMatrix1: 8 ETH
 SG_ BCFALCD_w001_WatchdogReset: 0|1@1+ (1,0) [0|0] "" X
 SG_ BCFALCD_w002_PowerLossReset: 1|1@1+ (1,0) [0|0] "" X
 SG_ BCFALCD_w003_SWAssertion: 2|1@1+ (1,0) [0|0] "" X
 SG_ BCFALCD_w004_CANMIA: 3|1@1+ (1,0) [0|0] "" X
 SG_ BCFALCD_w005_CANHighError: 4|1@1+ (1,0) [0|0] "" X
 SG_ BCFALCD_w006_CANLowError: 5|1@1+ (1,0) [0|0] "" X
 SG_ BCFALCD_w007_LINTimeout: 6|1@1+ (1,0) [0|0] "" X
 SG_ BCFALCD_w008_LIN2Error: 7|1@1+ (1,0) [0|0] "" X
 SG_ BCFALCD_w009_LIN3Error: 8|1@1+ (1,0) [0|0] "" X
 SG_ BCFALCD_w010_ExtSupplyVoltError: 9|1@1+ (1,0) [0|0] "" X
 SG_ BCFALCD_w011_ECUSupplyVoltError: 10|1@1+ (1,0) [0|0] "" X
 SG_ BCFALCD_w012_CPUReset: 11|1@1+ (1,0) [0|0] "" X
 SG_ BCFALCD_w013_Shared13: 12|1@1+ (1,0) [0|0] "" X
 SG_ BCFALCD_w014_BridgeFault: 13|1@1+ (1,0) [0|0] "" X
 SG_ BCFALCD_w015_NVMMAlert: 14|1@1+ (1,0) [0|0] "" X
 SG_ BCFALCD_w016_MessageTimingError: 15|1@1+ (1,0) [0|0] "" X
 SG_ BCFALCD_w017_AwakeForTooLong: 16|1@1+ (1,0) [0|0] "" X
 SG_ BCFALCD_w018_ADCError: 17|1@1+ (1,0) [0|0] "" X
 SG_ BCFALCD_w019_I2CError: 18|1@1+ (1,0) [0|0] "" X
 SG_ BCFALCD_w020_PWMError: 19|1@1+ (1,0) [0|0] "" X
 SG_ BCFALCD_w021_TaskSchedulerError: 20|1@1+ (1,0) [0|0] "" X
 SG_ BCFALCD_w022_TaskInitError: 21|1@1+ (1,0) [0|0] "" X
 SG_ BCFALCD_w023_SleepError: 22|1@1+ (1,0) [0|0] "" X
 SG_ BCFALCD_w024_WakeError: 23|1@1+ (1,0) [0|0] "" X
 SG_ BCFALCD_w025_CrashEvent: 24|1@1+ (1,0) [0|0] "" X
 SG_ BCFALCD_w026_FlashMemoryError: 25|1@1+ (1,0) [0|0] "" X
 SG_ BCFALCD_w027_NVRAMCorruption: 26|1@1+ (1,0) [0|0] "" X
 SG_ BCFALCD_w028_NVRAMNotResponding: 27|1@1+ (1,0) [0|0] "" X
 SG_ BCFALCD_w029_NVRAMUninitialized: 28|1@1+ (1,0) [0|0] "" X
 SG_ BCFALCD_w042_actuator12VFault: 41|1@1+ (1,0) [0|0] "" X
 SG_ BCFALCD_w044_FalconOpenAtSpeed: 43|1@1+ (1,0) [0|0] "" X
 SG_ BCFALCD_w045_ChassisCollision: 44|1@1+ (1,0) [0|0] "" X
 SG_ BCFALCD_w046_doorUSSInvaliddist: 45|1@1+ (1,0) [0|0] "" X
 SG_ BCFALCD_w047_roofUSSInvaliddist: 46|1@1+ (1,0) [0|0] "" X
 SG_ BCFALCD_w050_sideConfigError: 49|1@1+ (1,0) [0|0] "" X
 SG_ BCFALCD_w051_BlockedDoorRequest: 50|1@1+ (1,0) [0|0] "" X
 SG_ BCFALCD_w052_USS_RHOverTemp: 51|1@1+ (1,0) [0|0] "" X
 SG_ BCFALCD_w053_USS_RHSnsBlocked: 52|1@1+ (1,0) [0|0] "" X
 SG_ BCFALCD_w054_USS_RHSnsIntrnlFail: 53|1@1+ (1,0) [0|0] "" X
 SG_ BCFALCD_w055_USS_RHLinCommError: 54|1@1+ (1,0) [0|0] "" X
 SG_ BCFALCD_w056_USS_LHOverTemp: 55|1@1+ (1,0) [0|0] "" X
 SG_ BCFALCD_w057_USS_LHSnsBlocked: 56|1@1+ (1,0) [0|0] "" X
 SG_ BCFALCD_w058_USS_RoofSnsBlocked: 57|1@1+ (1,0) [0|0] "" X
 SG_ BCFALCD_w059_USS_LHSnsIntrnlFail: 58|1@1+ (1,0) [0|0] "" X
 SG_ BCFALCD_w060_USS_LHLinCommError: 59|1@1+ (1,0) [0|0] "" X
 SG_ BCFALCD_w061_USS_RoofOverTemp: 60|1@1+ (1,0) [0|0] "" X
 SG_ BCFALCD_w062_USS_RoofSnsIntFail: 61|1@1+ (1,0) [0|0] "" X
 SG_ BCFALCD_w063_USS_RoofLinComError: 62|1@1+ (1,0) [0|0] "" X
 SG_ BCFALCD_w064_USS_ECUUnderVoltage: 63|1@1+ (1,0) [0|0] "" X

BO_ 334 BCFALCD_warningMatrix2: 8 ETH
 SG_ BCFALCD_w065_USS_ECUOverVoltage: 0|1@1+ (1,0) [0|0] "" X
 SG_ BCFALCD_w066_USS_SnsSupplyError: 1|1@1+ (1,0) [0|0] "" X
 SG_ BCFALCD_w067_USS_ECUIntrnlFailur: 2|1@1+ (1,0) [0|0] "" X
 SG_ BCFALCD_w068_USS_calibCRCFailure: 3|1@1+ (1,0) [0|0] "" X
 SG_ BCFALCD_w069_USS_calibMissing: 4|1@1+ (1,0) [0|0] "" X
 SG_ BCFALCD_w070_USS_canBusOff: 5|1@1+ (1,0) [0|0] "" X
 SG_ BCFALCD_w071_USS_hwWatchdogFail: 6|1@1+ (1,0) [0|0] "" X
 SG_ BCFALCD_w072_USS_LHInwardLINerr: 7|1@1+ (1,0) [0|0] "" X
 SG_ BCFALCD_w073_USS_RHInwardLINerr: 8|1@1+ (1,0) [0|0] "" X
 SG_ BCFALCD_w074_USS_LHInwardIntFail: 9|1@1+ (1,0) [0|0] "" X
 SG_ BCFALCD_w075_USS_RHInwardIntFail: 10|1@1+ (1,0) [0|0] "" X
 SG_ BCFALCD_w079_DvrSideCfgMismatch: 14|1@1+ (1,0) [0|0] "" X
 SG_ BCFALCD_w083_FalconPinchFault: 18|1@1+ (1,0) [0|0] "" X
 SG_ BCFALCD_w086_CalibrationRequired: 21|1@1+ (1,0) [0|0] "" X
 SG_ BCFALCD_w087_UpperSagPrevention: 22|1@1+ (1,0) [0|0] "" X
 SG_ BCFALCD_w088_LowerPinchProtect: 23|1@1+ (1,0) [0|0] "" X
 SG_ BCFALCD_w089_UnexpectedStop: 24|1@1+ (1,0) [0|0] "" X
 SG_ BCFALCD_w090_CrashUnlockError: 25|1@1+ (1,0) [0|0] "" X
 SG_ BCFALCD_w091_CrashStateMismatch: 26|1@1+ (1,0) [0|0] "" X
 SG_ BCFALCD_w092_movementPrevented: 27|1@1+ (1,0) [0|0] "" X
 SG_ BCFALCD_w093_OTPError: 28|1@1+ (1,0) [0|0] "" X
 SG_ BCFALCD_w094_ObstacleOverride: 29|1@1+ (1,0) [0|0] "" X
 SG_ BCFALCD_w095_UnexpectLatchClosed: 30|1@1+ (1,0) [0|0] "" X
 SG_ BCFALCD_w096_UnexpectedDuty: 31|1@1+ (1,0) [0|0] "" X
 SG_ BCFALCD_w097_inwardUSSLog: 32|1@1+ (1,0) [0|0] "" X
 SG_ BCFALCD_w098_LatchCinchRelease: 33|1@1+ (1,0) [0|0] "" X
 SG_ BCFALCD_w100_ChargePumpFault: 35|1@1+ (1,0) [0|0] "" X
 SG_ BCFALCD_w101_VbatUnplugged: 36|1@1+ (1,0) [0|0] "" X
 SG_ BCFALCD_w102_RegulatorFault: 37|1@1+ (1,0) [0|0] "" X
 SG_ BCFALCD_w103_OverCurrent: 38|1@1+ (1,0) [0|0] "" X
 SG_ BCFALCD_w105_ECUDebugMode: 40|1@1+ (1,0) [0|0] "" X
 SG_ BCFALCD_w106_HighCPULoad: 41|1@1+ (1,0) [0|0] "" X
 SG_ BCFALCD_w107_HighStackUsage: 42|1@1+ (1,0) [0|0] "" X
 SG_ BCFALCD_w110_InteriorOpenSwitch: 45|1@1+ (1,0) [0|0] "" X
 SG_ BCFALCD_w111_InteriorCloseSwitch: 46|1@1+ (1,0) [0|0] "" X
 SG_ BCFALCD_w112_LatchEntryTimeout: 47|1@1+ (1,0) [0|0] "" X
 SG_ BCFALCD_w113_InfoCapTripleTap: 48|1@1+ (1,0) [0|0] "" X
 SG_ BCFALCD_w114_InfoCapSwipeFront: 49|1@1+ (1,0) [0|0] "" X
 SG_ BCFALCD_w115_InfoCapSwipeRear: 50|1@1+ (1,0) [0|0] "" X
 SG_ BCFALCD_w116_InfoCapHold: 51|1@1+ (1,0) [0|0] "" X
 SG_ BCFALCD_w117_InfoV2CapTripleTap: 52|1@1+ (1,0) [0|0] "" X
 SG_ BCFALCD_w118_InfoV2CapSwipe: 53|1@1+ (1,0) [0|0] "" X
 SG_ BCFALCD_w119_InfoV2CapHold: 54|1@1+ (1,0) [0|0] "" X
 SG_ BCFALCD_w120_IMUMIA: 55|1@1+ (1,0) [0|0] "" X
 SG_ BCFALCD_w121_DoorUSSMIA: 56|1@1+ (1,0) [0|0] "" X
 SG_ BCFALCD_w122_RoofUSSMIA: 57|1@1+ (1,0) [0|0] "" X
 SG_ BCFALCD_w123_capacitiveMIA: 58|1@1+ (1,0) [0|0] "" X
 SG_ BCFALCD_w124_inductiveMIA: 59|1@1+ (1,0) [0|0] "" X

BO_ 350 BCFALCD_warningMatrix3: 8 ETH
 SG_ BCFALCD_w130_upperFrontCurError: 1|1@1+ (1,0) [0|0] "" X
 SG_ BCFALCD_w131_upperRearCurError: 2|1@1+ (1,0) [0|0] "" X
 SG_ BCFALCD_w132_lowerFrontCurError: 3|1@1+ (1,0) [0|0] "" X
 SG_ BCFALCD_w133_lowerRearCurError: 4|1@1+ (1,0) [0|0] "" X
 SG_ BCFALCD_w134_lowerEndStopDetect: 5|1@1+ (1,0) [0|0] "" X
 SG_ BCFALCD_w140_upperFrontPosError: 11|1@1+ (1,0) [0|0] "" X
 SG_ BCFALCD_w141_upperRearPosError: 12|1@1+ (1,0) [0|0] "" X
 SG_ BCFALCD_w142_lowerFrontPosError: 13|1@1+ (1,0) [0|0] "" X
 SG_ BCFALCD_w143_lowerRearPosError: 14|1@1+ (1,0) [0|0] "" X
 SG_ BCFALCD_w144_upperFrontCurLimit: 15|1@1+ (1,0) [0|0] "" X
 SG_ BCFALCD_w145_upperRearCurLimit: 16|1@1+ (1,0) [0|0] "" X
 SG_ BCFALCD_w146_lowerFrontCurLimit: 17|1@1+ (1,0) [0|0] "" X
 SG_ BCFALCD_w147_lowerRearCurLimit: 18|1@1+ (1,0) [0|0] "" X
 SG_ BCFALCD_w148_upperSpeedAdjusted: 19|1@1+ (1,0) [0|0] "" X
 SG_ BCFALCD_w149_lowerSpeedAdjusted: 20|1@1+ (1,0) [0|0] "" X
 SG_ BCFALCD_w150_upperFrontNoResp: 21|1@1+ (1,0) [0|0] "" X
 SG_ BCFALCD_w151_upperRearNoResp: 22|1@1+ (1,0) [0|0] "" X
 SG_ BCFALCD_w152_lowerFrontNoResp: 23|1@1+ (1,0) [0|0] "" X
 SG_ BCFALCD_w153_lowerRearNoResp: 24|1@1+ (1,0) [0|0] "" X
 SG_ BCFALCD_w159_IMUSensitiveTrigger: 30|1@1+ (1,0) [0|0] "" X
 SG_ BCFALCD_w160_IMUObstacleDetected: 31|1@1+ (1,0) [0|0] "" X
 SG_ BCFALCD_w161_DoorUSSObsDetected: 32|1@1+ (1,0) [0|0] "" X
 SG_ BCFALCD_w162_RoofUSSObsDetected: 33|1@1+ (1,0) [0|0] "" X
 SG_ BCFALCD_w163_CapacitObsDetected: 34|1@1+ (1,0) [0|0] "" X
 SG_ BCFALCD_w164_InductivObsDetected: 35|1@1+ (1,0) [0|0] "" X
 SG_ BCFALCD_w165_PinchObsDetected: 36|1@1+ (1,0) [0|0] "" X
 SG_ BCFALCD_w166_CapHarnessErr: 37|1@1+ (1,0) [0|0] "" X
 SG_ BCFALCD_w167_CapGenealogyErr: 38|1@1+ (1,0) [0|0] "" X
 SG_ BCFALCD_w168_IndHarnessErr: 39|1@1+ (1,0) [0|0] "" X
 SG_ BCFALCD_w169_IndGenealogyErr: 40|1@1+ (1,0) [0|0] "" X
 SG_ BCFALCD_w170_upperFrontOverTemp: 41|1@1+ (1,0) [0|0] "" X
 SG_ BCFALCD_w171_upperRearOverTemp: 42|1@1+ (1,0) [0|0] "" X
 SG_ BCFALCD_w172_lowerFrontOverTemp: 43|1@1+ (1,0) [0|0] "" X
 SG_ BCFALCD_w173_lowerRearOverTemp: 44|1@1+ (1,0) [0|0] "" X
 SG_ BCFALCD_w174_USSRoofResonanceErr: 45|1@1+ (1,0) [0|0] "" X
 SG_ BCFALCD_w175_USSRoofReverbErr: 46|1@1+ (1,0) [0|0] "" X
 SG_ BCFALCD_w176_USSRoofNotCaptured: 47|1@1+ (1,0) [0|0] "" X
 SG_ BCFALCD_w177_USSDoorResonanceErr: 48|1@1+ (1,0) [0|0] "" X
 SG_ BCFALCD_w178_USSDoorReverbErr: 49|1@1+ (1,0) [0|0] "" X
 SG_ BCFALCD_w179_USSDoorNotCaptured: 50|1@1+ (1,0) [0|0] "" X
 SG_ BCFALCD_w180_UpperCurrentThresh: 51|1@1+ (1,0) [0|0] "" X
 SG_ BCFALCD_w181_UpperTrajPosition: 52|1@1+ (1,0) [0|0] "" X
 SG_ BCFALCD_w182_UpperTrajSpeed: 53|1@1+ (1,0) [0|0] "" X
 SG_ BCFALCD_w183_UpperLatchEntry: 54|1@1+ (1,0) [0|0] "" X
 SG_ BCFALCD_w184_LowerCurrentThresh: 55|1@1+ (1,0) [0|0] "" X
 SG_ BCFALCD_w185_LowerTrajPosition: 56|1@1+ (1,0) [0|0] "" X
 SG_ BCFALCD_w186_LowerTrajSpeed: 57|1@1+ (1,0) [0|0] "" X
 SG_ BCFALCD_w187_LowerLatchEntry: 58|1@1+ (1,0) [0|0] "" X
 SG_ BCFALCD_w190_RoofUSSUnstable: 61|1@1+ (1,0) [0|0] "" X
 SG_ BCFALCD_w191_DoorUSSUnstable: 62|1@1+ (1,0) [0|0] "" X
 SG_ BCFALCD_w192_eFuseNotReady: 63|1@1+ (1,0) [0|0] "" X

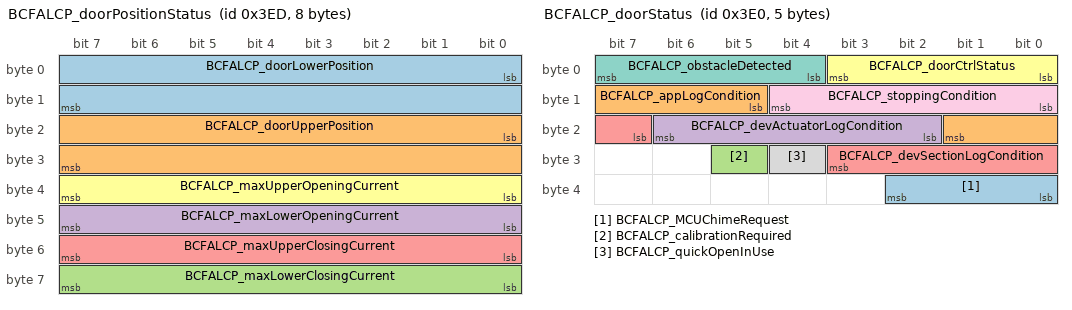
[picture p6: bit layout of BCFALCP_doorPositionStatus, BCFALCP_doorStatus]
BO_ 1005 BCFALCP_doorPositionStatus: 8 ETH
 SG_ BCFALCP_doorLowerPosition: 0|16@1- (0.00549325,0) [0|0] "deg" X
 SG_ BCFALCP_doorUpperPosition: 16|16@1- (0.00549325,0) [0|0] "deg" X
 SG_ BCFALCP_maxLowerClosingCurrent: 56|8@1- (0.2,0) [0|0] "A" X
 SG_ BCFALCP_maxLowerOpeningCurrent: 40|8@1- (0.2,0) [0|0] "A" X
 SG_ BCFALCP_maxUpperClosingCurrent: 48|8@1- (0.2,0) [0|0] "A" X
 SG_ BCFALCP_maxUpperOpeningCurrent: 32|8@1- (0.2,0) [0|0] "A" X

BO_ 992 BCFALCP_doorStatus: 5 ETH
 SG_ BCFALCP_MCUChimeRequest: 32|3@1+ (1,0) [0|0] "" X
 SG_ BCFALCP_appLogCondition: 13|5@1+ (1,0) [0|0] "" X
 SG_ BCFALCP_calibrationRequired: 29|1@1+ (1,0) [0|0] "" X
 SG_ BCFALCP_devActuatorLogCondition: 18|5@1+ (1,0) [0|0] "" X
 SG_ BCFALCP_devSectionLogCondition: 23|5@1+ (1,0) [0|0] "" X
 SG_ BCFALCP_doorCtrlStatus: 0|4@1+ (1,0) [0|0] "" X
 SG_ BCFALCP_obstacleDetected: 4|4@1+ (1,0) [0|0] "" X
 SG_ BCFALCP_quickOpenInUse: 28|1@1+ (1,0) [0|0] "" X
 SG_ BCFALCP_stoppingCondition: 8|5@1+ (1,0) [0|0] "" X

BO_ 1316 BCFALCP_info: 8 ETH
 SG_ BCFALCP_infoIndex M: 0|8@1+ (1,0) [0|0] "" X
 SG_ BCFALCP_infoBuildType m10: 8|8@1+ (1,0) [0|0] "" X
 SG_ BCFALCP_infoBuildConfigID m10: 16|16@1+ (1,0) [0|0] "" X
 SG_ BCFALCP_infoHardwareID m10: 32|16@1+ (1,0) [0|0] "" X
 SG_ BCFALCP_infoComponentID m10: 48|16@1+ (1,0) [0|0] "" X
 SG_ BCFALCP_infoPcbaID m11: 16|8@1+ (1,0) [0|0] "" X
 SG_ BCFALCP_infoAssemblyID m11: 24|8@1+ (1,0) [0|0] "INTEGRAL" X
 SG_ BCFALCP_infoUsageID m11: 32|16@1+ (1,0) [0|0] "" X
 SG_ BCFALCP_infoSubUsageID m11: 48|16@1+ (1,0) [0|0] "" X
 SG_ BCFALCP_infoApplicationCRC m13: 32|32@1+ (1,0) [0|0] "" X
 SG_ BCFALCP_infoBootSvnRev m14: 8|24@1+ (1,0) [0|0] "" X
 SG_ BCFALCP_infoAppGitHashBytes m17: 10|54@1+ (4,0) [0|0] "" X
 SG_ BCFALCP_infoBootGitHashBytes m18: 10|54@1+ (4,0) [0|0] "" X
 SG_ BCFALCP_infoPlatformType m19: 8|8@1+ (1,0) [0|0] "" X
 SG_ BCFALCP_infoBootUdsProtoVersion m20: 8|8@1+ (1,0) [0|0] "" X
 SG_ BCFALCP_infoBootloaderCRC m20: 32|32@1+ (1,0) [0|0] "" X

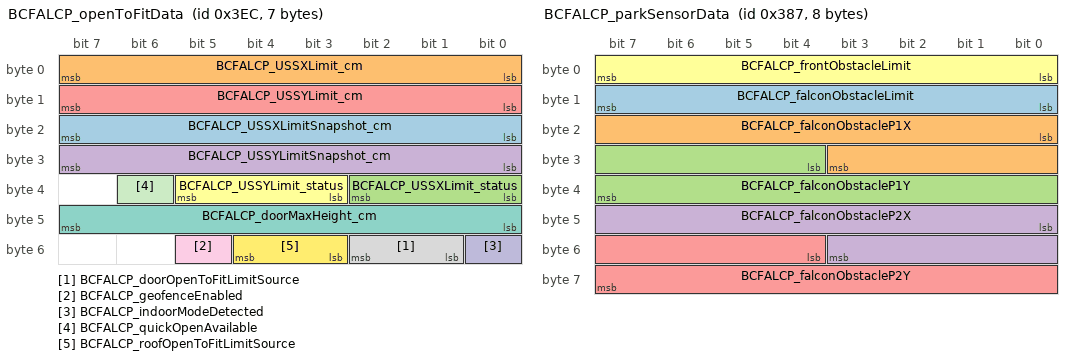
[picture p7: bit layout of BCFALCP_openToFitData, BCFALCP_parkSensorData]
BO_ 1004 BCFALCP_openToFitData: 7 ETH
 SG_ BCFALCP_USSXLimitSnapshot_cm: 16|8@1+ (1,0) [0|0] "cm" X
 SG_ BCFALCP_USSXLimit_cm: 0|8@1+ (1,0) [0|0] "cm" X
 SG_ BCFALCP_USSXLimit_status: 32|3@1+ (1,0) [0|0] "" X
 SG_ BCFALCP_USSYLimitSnapshot_cm: 24|8@1+ (1,0) [0|0] "cm" X
 SG_ BCFALCP_USSYLimit_cm: 8|8@1+ (1,0) [0|0] "cm" X
 SG_ BCFALCP_USSYLimit_status: 35|3@1+ (1,0) [0|0] "" X
 SG_ BCFALCP_doorMaxHeight_cm: 40|8@1+ (1,0) [0|0] "cm" X
 SG_ BCFALCP_doorOpenToFitLimitSource: 49|2@1+ (1,0) [0|0] "" X
 SG_ BCFALCP_geofenceEnabled: 53|1@1+ (1,0) [0|0] "" X
 SG_ BCFALCP_indoorModeDetected: 48|1@1+ (1,0) [0|0] "" X
 SG_ BCFALCP_quickOpenAvailable: 38|1@1+ (1,0) [0|0] "" X
 SG_ BCFALCP_roofOpenToFitLimitSource: 51|2@1+ (1,0) [0|0] "" X

BO_ 903 BCFALCP_parkSensorData: 8 ETH
 SG_ BCFALCP_falconObstacleLimit: 8|8@1+ (1,0) [0|0] "cm" X
 SG_ BCFALCP_falconObstacleP1X: 16|12@1- (1,0) [0|0] "" X
 SG_ BCFALCP_falconObstacleP1Y: 28|12@1- (1,0) [0|0] "" X
 SG_ BCFALCP_falconObstacleP2X: 40|12@1- (1,0) [0|0] "" X
 SG_ BCFALCP_falconObstacleP2Y: 52|12@1- (1,0) [0|0] "" X
 SG_ BCFALCP_frontObstacleLimit: 0|8@1+ (1,0) [0|0] "cm" X

BO_ 1722 BCFALCP_udsResponse: 8 ETH
 SG_ BCFALCP_udsResponseData_H: 0|32@0+ (1,0) [0|0] "" X
 SG_ BCFALCP_udsResponseData_L: 32|32@0+ (1,0) [0|0] "" X

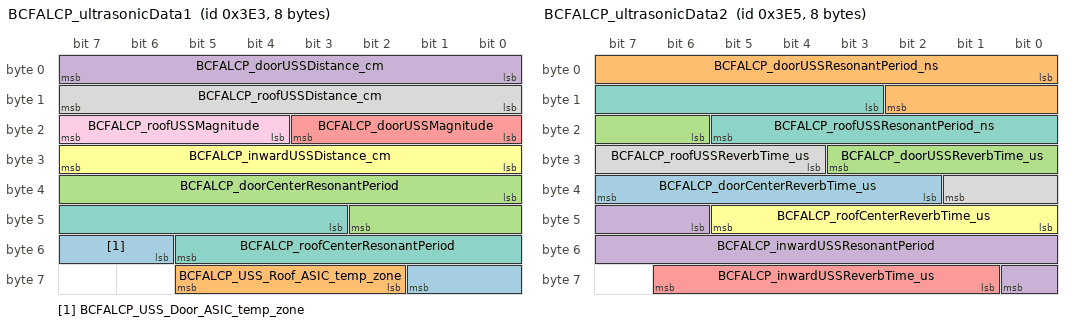
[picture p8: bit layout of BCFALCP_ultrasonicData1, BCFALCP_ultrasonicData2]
BO_ 995 BCFALCP_ultrasonicData1: 8 ETH
 SG_ BCFALCP_USS_Door_ASIC_temp_zone: 54|4@1+ (1,0) [0|0] "" X
 SG_ BCFALCP_USS_Roof_ASIC_temp_zone: 58|4@1+ (1,0) [0|0] "" X
 SG_ BCFALCP_doorCenterResonantPeriod: 32|11@1+ (25,0) [0|0] "ns" X
 SG_ BCFALCP_doorUSSDistance_cm: 0|8@1+ (1,0) [0|0] "cm" X
 SG_ BCFALCP_doorUSSMagnitude: 16|4@1+ (6.66667,0) [0|0] "%" X
 SG_ BCFALCP_inwardUSSDistance_cm: 24|8@1+ (1,0) [0|0] "cm" X
 SG_ BCFALCP_roofCenterResonantPeriod: 43|11@1+ (25,0) [0|0] "ns" X
 SG_ BCFALCP_roofUSSDistance_cm: 8|8@1+ (1,0) [0|0] "cm" X
 SG_ BCFALCP_roofUSSMagnitude: 20|4@1+ (6.66667,0) [0|0] "%" X

BO_ 997 BCFALCP_ultrasonicData2: 8 ETH
 SG_ BCFALCP_doorCenterReverbTime_us: 34|6@1+ (51.2,0) [0|0] "us" X
 SG_ BCFALCP_doorUSSResonantPeriod_ns: 0|11@1+ (25,0) [0|0] "ns" X
 SG_ BCFALCP_doorUSSReverbTime_us: 22|6@1+ (51.2,0) [0|0] "us" X
 SG_ BCFALCP_inwardUSSResonantPeriod: 46|11@1+ (25,0) [0|0] "ns" X
 SG_ BCFALCP_inwardUSSReverbTime_us: 57|6@1+ (51.2,0) [0|0] "us" X
 SG_ BCFALCP_roofCenterReverbTime_us: 40|6@1+ (51.2,0) [0|0] "us" X
 SG_ BCFALCP_roofUSSResonantPeriod_ns: 11|11@1+ (25,0) [0|0] "ns" X
 SG_ BCFALCP_roofUSSReverbTime_us: 28|6@1+ (51.2,0) [0|0] "us" X

BO_ 314 BCFALCP_warningMatrix1: 8 ETH
 SG_ BCFALCP_w001_WatchdogReset: 0|1@1+ (1,0) [0|0] "" X
 SG_ BCFALCP_w002_PowerLossReset: 1|1@1+ (1,0) [0|0] "" X
 SG_ BCFALCP_w003_SWAssertion: 2|1@1+ (1,0) [0|0] "" X
 SG_ BCFALCP_w004_CANMIA: 3|1@1+ (1,0) [0|0] "" X
 SG_ BCFALCP_w005_CANHighError: 4|1@1+ (1,0) [0|0] "" X
 SG_ BCFALCP_w006_CANLowError: 5|1@1+ (1,0) [0|0] "" X
 SG_ BCFALCP_w007_LINTimeout: 6|1@1+ (1,0) [0|0] "" X
 SG_ BCFALCP_w008_LIN2Error: 7|1@1+ (1,0) [0|0] "" X
 SG_ BCFALCP_w009_LIN3Error: 8|1@1+ (1,0) [0|0] "" X
 SG_ BCFALCP_w010_ExtSupplyVoltError: 9|1@1+ (1,0) [0|0] "" X
 SG_ BCFALCP_w011_ECUSupplyVoltError: 10|1@1+ (1,0) [0|0] "" X
 SG_ BCFALCP_w012_CPUReset: 11|1@1+ (1,0) [0|0] "" X
 SG_ BCFALCP_w013_Shared13: 12|1@1+ (1,0) [0|0] "" X
 SG_ BCFALCP_w014_BridgeFault: 13|1@1+ (1,0) [0|0] "" X
 SG_ BCFALCP_w015_NVMMAlert: 14|1@1+ (1,0) [0|0] "" X
 SG_ BCFALCP_w016_MessageTimingError: 15|1@1+ (1,0) [0|0] "" X
 SG_ BCFALCP_w017_AwakeForTooLong: 16|1@1+ (1,0) [0|0] "" X
 SG_ BCFALCP_w018_ADCError: 17|1@1+ (1,0) [0|0] "" X
 SG_ BCFALCP_w019_I2CError: 18|1@1+ (1,0) [0|0] "" X
 SG_ BCFALCP_w020_PWMError: 19|1@1+ (1,0) [0|0] "" X
 SG_ BCFALCP_w021_TaskSchedulerError: 20|1@1+ (1,0) [0|0] "" X
 SG_ BCFALCP_w022_TaskInitError: 21|1@1+ (1,0) [0|0] "" X
 SG_ BCFALCP_w023_SleepError: 22|1@1+ (1,0) [0|0] "" X
 SG_ BCFALCP_w024_WakeError: 23|1@1+ (1,0) [0|0] "" X
 SG_ BCFALCP_w025_CrashEvent: 24|1@1+ (1,0) [0|0] "" X
 SG_ BCFALCP_w026_FlashMemoryError: 25|1@1+ (1,0) [0|0] "" X
 SG_ BCFALCP_w027_NVRAMCorruption: 26|1@1+ (1,0) [0|0] "" X
 SG_ BCFALCP_w028_NVRAMNotResponding: 27|1@1+ (1,0) [0|0] "" X
 SG_ BCFALCP_w029_NVRAMUninitialized: 28|1@1+ (1,0) [0|0] "" X
 SG_ BCFALCP_w042_actuator12VFault: 41|1@1+ (1,0) [0|0] "" X
 SG_ BCFALCP_w044_FalconOpenAtSpeed: 43|1@1+ (1,0) [0|0] "" X
 SG_ BCFALCP_w045_ChassisCollision: 44|1@1+ (1,0) [0|0] "" X
 SG_ BCFALCP_w046_doorUSSInvaliddist: 45|1@1+ (1,0) [0|0] "" X
 SG_ BCFALCP_w047_roofUSSInvaliddist: 46|1@1+ (1,0) [0|0] "" X
 SG_ BCFALCP_w050_sideConfigError: 49|1@1+ (1,0) [0|0] "" X
 SG_ BCFALCP_w051_BlockedDoorRequest: 50|1@1+ (1,0) [0|0] "" X
 SG_ BCFALCP_w052_USS_RHOverTemp: 51|1@1+ (1,0) [0|0] "" X
 SG_ BCFALCP_w053_USS_RHSnsBlocked: 52|1@1+ (1,0) [0|0] "" X
 SG_ BCFALCP_w054_USS_RHSnsIntrnlFail: 53|1@1+ (1,0) [0|0] "" X
 SG_ BCFALCP_w055_USS_RHLinCommError: 54|1@1+ (1,0) [0|0] "" X
 SG_ BCFALCP_w056_USS_LHOverTemp: 55|1@1+ (1,0) [0|0] "" X
 SG_ BCFALCP_w057_USS_LHSnsBlocked: 56|1@1+ (1,0) [0|0] "" X
 SG_ BCFALCP_w058_USS_RoofSnsBlocked: 57|1@1+ (1,0) [0|0] "" X
 SG_ BCFALCP_w059_USS_LHSnsIntrnlFail: 58|1@1+ (1,0) [0|0] "" X
 SG_ BCFALCP_w060_USS_LHLinCommError: 59|1@1+ (1,0) [0|0] "" X
 SG_ BCFALCP_w061_USS_RoofOverTemp: 60|1@1+ (1,0) [0|0] "" X
 SG_ BCFALCP_w062_USS_RoofSnsIntFail: 61|1@1+ (1,0) [0|0] "" X
 SG_ BCFALCP_w063_USS_RoofLinComError: 62|1@1+ (1,0) [0|0] "" X
 SG_ BCFALCP_w064_USS_ECUUnderVoltage: 63|1@1+ (1,0) [0|0] "" X

BO_ 330 BCFALCP_warningMatrix2: 8 ETH
 SG_ BCFALCP_w065_USS_ECUOverVoltage: 0|1@1+ (1,0) [0|0] "" X
 SG_ BCFALCP_w066_USS_SnsSupplyError: 1|1@1+ (1,0) [0|0] "" X
 SG_ BCFALCP_w067_USS_ECUIntrnlFailur: 2|1@1+ (1,0) [0|0] "" X
 SG_ BCFALCP_w068_USS_calibCRCFailure: 3|1@1+ (1,0) [0|0] "" X
 SG_ BCFALCP_w069_USS_calibMissing: 4|1@1+ (1,0) [0|0] "" X
 SG_ BCFALCP_w070_USS_canBusOff: 5|1@1+ (1,0) [0|0] "" X
 SG_ BCFALCP_w071_USS_hwWatchdogFail: 6|1@1+ (1,0) [0|0] "" X
 SG_ BCFALCP_w072_USS_LHInwardLINerr: 7|1@1+ (1,0) [0|0] "" X
 SG_ BCFALCP_w073_USS_RHInwardLINerr: 8|1@1+ (1,0) [0|0] "" X
 SG_ BCFALCP_w074_USS_LHInwardIntFail: 9|1@1+ (1,0) [0|0] "" X
 SG_ BCFALCP_w075_USS_RHInwardIntFail: 10|1@1+ (1,0) [0|0] "" X
 SG_ BCFALCP_w079_DvrSideCfgMismatch: 14|1@1+ (1,0) [0|0] "" X
 SG_ BCFALCP_w083_FalconPinchFault: 18|1@1+ (1,0) [0|0] "" X
 SG_ BCFALCP_w086_CalibrationRequired: 21|1@1+ (1,0) [0|0] "" X
 SG_ BCFALCP_w087_UpperSagPrevention: 22|1@1+ (1,0) [0|0] "" X
 SG_ BCFALCP_w088_LowerPinchProtect: 23|1@1+ (1,0) [0|0] "" X
 SG_ BCFALCP_w089_UnexpectedStop: 24|1@1+ (1,0) [0|0] "" X
 SG_ BCFALCP_w090_CrashUnlockError: 25|1@1+ (1,0) [0|0] "" X
 SG_ BCFALCP_w091_CrashStateMismatch: 26|1@1+ (1,0) [0|0] "" X
 SG_ BCFALCP_w092_movementPrevented: 27|1@1+ (1,0) [0|0] "" X
 SG_ BCFALCP_w093_OTPError: 28|1@1+ (1,0) [0|0] "" X
 SG_ BCFALCP_w094_ObstacleOverride: 29|1@1+ (1,0) [0|0] "" X
 SG_ BCFALCP_w095_UnexpectLatchClosed: 30|1@1+ (1,0) [0|0] "" X
 SG_ BCFALCP_w096_UnexpectedDuty: 31|1@1+ (1,0) [0|0] "" X
 SG_ BCFALCP_w097_inwardUSSLog: 32|1@1+ (1,0) [0|0] "" X
 SG_ BCFALCP_w098_LatchCinchRelease: 33|1@1+ (1,0) [0|0] "" X
 SG_ BCFALCP_w100_ChargePumpFault: 35|1@1+ (1,0) [0|0] "" X
 SG_ BCFALCP_w101_VbatUnplugged: 36|1@1+ (1,0) [0|0] "" X
 SG_ BCFALCP_w102_RegulatorFault: 37|1@1+ (1,0) [0|0] "" X
 SG_ BCFALCP_w103_OverCurrent: 38|1@1+ (1,0) [0|0] "" X
 SG_ BCFALCP_w105_ECUDebugMode: 40|1@1+ (1,0) [0|0] "" X
 SG_ BCFALCP_w106_HighCPULoad: 41|1@1+ (1,0) [0|0] "" X
 SG_ BCFALCP_w107_HighStackUsage: 42|1@1+ (1,0) [0|0] "" X
 SG_ BCFALCP_w110_InteriorOpenSwitch: 45|1@1+ (1,0) [0|0] "" X
 SG_ BCFALCP_w111_InteriorCloseSwitch: 46|1@1+ (1,0) [0|0] "" X
 SG_ BCFALCP_w112_LatchEntryTimeout: 47|1@1+ (1,0) [0|0] "" X
 SG_ BCFALCP_w113_InfoCapTripleTap: 48|1@1+ (1,0) [0|0] "" X
 SG_ BCFALCP_w114_InfoCapSwipeFront: 49|1@1+ (1,0) [0|0] "" X
 SG_ BCFALCP_w115_InfoCapSwipeRear: 50|1@1+ (1,0) [0|0] "" X
 SG_ BCFALCP_w116_InfoCapHold: 51|1@1+ (1,0) [0|0] "" X
 SG_ BCFALCP_w117_InfoV2CapTripleTap: 52|1@1+ (1,0) [0|0] "" X
 SG_ BCFALCP_w118_InfoV2CapSwipe: 53|1@1+ (1,0) [0|0] "" X
 SG_ BCFALCP_w119_InfoV2CapHold: 54|1@1+ (1,0) [0|0] "" X
 SG_ BCFALCP_w120_IMUMIA: 55|1@1+ (1,0) [0|0] "" X
 SG_ BCFALCP_w121_DoorUSSMIA: 56|1@1+ (1,0) [0|0] "" X
 SG_ BCFALCP_w122_RoofUSSMIA: 57|1@1+ (1,0) [0|0] "" X
 SG_ BCFALCP_w123_capacitiveMIA: 58|1@1+ (1,0) [0|0] "" X
 SG_ BCFALCP_w124_inductiveMIA: 59|1@1+ (1,0) [0|0] "" X

BO_ 346 BCFALCP_warningMatrix3: 8 ETH
 SG_ BCFALCP_w130_upperFrontCurError: 1|1@1+ (1,0) [0|0] "" X
 SG_ BCFALCP_w131_upperRearCurError: 2|1@1+ (1,0) [0|0] "" X
 SG_ BCFALCP_w132_lowerFrontCurError: 3|1@1+ (1,0) [0|0] "" X
 SG_ BCFALCP_w133_lowerRearCurError: 4|1@1+ (1,0) [0|0] "" X
 SG_ BCFALCP_w134_lowerEndStopDetect: 5|1@1+ (1,0) [0|0] "" X
 SG_ BCFALCP_w140_upperFrontPosError: 11|1@1+ (1,0) [0|0] "" X
 SG_ BCFALCP_w141_upperRearPosError: 12|1@1+ (1,0) [0|0] "" X
 SG_ BCFALCP_w142_lowerFrontPosError: 13|1@1+ (1,0) [0|0] "" X
 SG_ BCFALCP_w143_lowerRearPosError: 14|1@1+ (1,0) [0|0] "" X
 SG_ BCFALCP_w144_upperFrontCurLimit: 15|1@1+ (1,0) [0|0] "" X
 SG_ BCFALCP_w145_upperRearCurLimit: 16|1@1+ (1,0) [0|0] "" X
 SG_ BCFALCP_w146_lowerFrontCurLimit: 17|1@1+ (1,0) [0|0] "" X
 SG_ BCFALCP_w147_lowerRearCurLimit: 18|1@1+ (1,0) [0|0] "" X
 SG_ BCFALCP_w148_upperSpeedAdjusted: 19|1@1+ (1,0) [0|0] "" X
 SG_ BCFALCP_w149_lowerSpeedAdjusted: 20|1@1+ (1,0) [0|0] "" X
 SG_ BCFALCP_w150_upperFrontNoResp: 21|1@1+ (1,0) [0|0] "" X
 SG_ BCFALCP_w151_upperRearNoResp: 22|1@1+ (1,0) [0|0] "" X
 SG_ BCFALCP_w152_lowerFrontNoResp: 23|1@1+ (1,0) [0|0] "" X
 SG_ BCFALCP_w153_lowerRearNoResp: 24|1@1+ (1,0) [0|0] "" X
 SG_ BCFALCP_w159_IMUSensitiveTrigger: 30|1@1+ (1,0) [0|0] "" X
 SG_ BCFALCP_w160_IMUObstacleDetected: 31|1@1+ (1,0) [0|0] "" X
 SG_ BCFALCP_w161_DoorUSSObsDetected: 32|1@1+ (1,0) [0|0] "" X
 SG_ BCFALCP_w162_RoofUSSObsDetected: 33|1@1+ (1,0) [0|0] "" X
 SG_ BCFALCP_w163_CapacitObsDetected: 34|1@1+ (1,0) [0|0] "" X
 SG_ BCFALCP_w164_InductivObsDetected: 35|1@1+ (1,0) [0|0] "" X
 SG_ BCFALCP_w165_PinchObsDetected: 36|1@1+ (1,0) [0|0] "" X
 SG_ BCFALCP_w166_CapHarnessErr: 37|1@1+ (1,0) [0|0] "" X
 SG_ BCFALCP_w167_CapGenealogyErr: 38|1@1+ (1,0) [0|0] "" X
 SG_ BCFALCP_w168_IndHarnessErr: 39|1@1+ (1,0) [0|0] "" X
 SG_ BCFALCP_w169_IndGenealogyErr: 40|1@1+ (1,0) [0|0] "" X
 SG_ BCFALCP_w170_upperFrontOverTemp: 41|1@1+ (1,0) [0|0] "" X
 SG_ BCFALCP_w171_upperRearOverTemp: 42|1@1+ (1,0) [0|0] "" X
 SG_ BCFALCP_w172_lowerFrontOverTemp: 43|1@1+ (1,0) [0|0] "" X
 SG_ BCFALCP_w173_lowerRearOverTemp: 44|1@1+ (1,0) [0|0] "" X
 SG_ BCFALCP_w174_USSRoofResonanceErr: 45|1@1+ (1,0) [0|0] "" X
 SG_ BCFALCP_w175_USSRoofReverbErr: 46|1@1+ (1,0) [0|0] "" X
 SG_ BCFALCP_w176_USSRoofNotCaptured: 47|1@1+ (1,0) [0|0] "" X
 SG_ BCFALCP_w177_USSDoorResonanceErr: 48|1@1+ (1,0) [0|0] "" X
 SG_ BCFALCP_w178_USSDoorReverbErr: 49|1@1+ (1,0) [0|0] "" X
 SG_ BCFALCP_w179_USSDoorNotCaptured: 50|1@1+ (1,0) [0|0] "" X
 SG_ BCFALCP_w180_UpperCurrentThresh: 51|1@1+ (1,0) [0|0] "" X
 SG_ BCFALCP_w181_UpperTrajPosition: 52|1@1+ (1,0) [0|0] "" X
 SG_ BCFALCP_w182_UpperTrajSpeed: 53|1@1+ (1,0) [0|0] "" X
 SG_ BCFALCP_w183_UpperLatchEntry: 54|1@1+ (1,0) [0|0] "" X
 SG_ BCFALCP_w184_LowerCurrentThresh: 55|1@1+ (1,0) [0|0] "" X
 SG_ BCFALCP_w185_LowerTrajPosition: 56|1@1+ (1,0) [0|0] "" X
 SG_ BCFALCP_w186_LowerTrajSpeed: 57|1@1+ (1,0) [0|0] "" X
 SG_ BCFALCP_w187_LowerLatchEntry: 58|1@1+ (1,0) [0|0] "" X
 SG_ BCFALCP_w190_RoofUSSUnstable: 61|1@1+ (1,0) [0|0] "" X
 SG_ BCFALCP_w191_DoorUSSUnstable: 62|1@1+ (1,0) [0|0] "" X
 SG_ BCFALCP_w192_eFuseNotReady: 63|1@1+ (1,0) [0|0] "" X

BO_ 1956 BCFDM_debug: 3 ETH
 SG_ BCFDM_LINFailure: 3|4@1+ (1,0) [0|0] "" X
 SG_ BCFDM_LINMechRelease: 7|1@1+ (1,0) [0|0] "" X
 SG_ BCFDM_LINOpenRequested: 8|1@1+ (1,0) [0|0] "" X
 SG_ BCFDM_LINStatus: 0|3@1+ (1,0) [0|0] "" X
 SG_ BCFDM_LINVehicleLocked: 9|1@1+ (1,0) [0|0] "" X
 SG_ BCFDM_LINVehicleMoving: 10|1@1+ (1,0) [0|0] "" X
 SG_ BCFDM_cinchStatusSwitchActive: 20|1@1+ (1,0) [0|0] "" X
 SG_ BCFDM_cinchStatusSwitchEnabled: 21|1@1+ (1,0) [0|0] "" X
 SG_ BCFDM_keyAbsenceCloseReqStatus: 18|1@1+ (1,0) [0|0] "" X
 SG_ BCFDM_keyLocationCloseReqStatus: 17|1@1+ (1,0) [0|0] "" X
 SG_ BCFDM_keyLockInhibitAutoPresent: 16|1@1+ (1,0) [0|0] "" X
 SG_ BCFDM_keyRegionOpenReqStatus: 14|1@1+ (1,0) [0|0] "" X
 SG_ BCFDM_keyVectorOpenReqStatus: 15|1@1+ (1,0) [0|0] "" X
 SG_ BCFDM_nonLINAjarSwitchActive: 12|1@1+ (1,0) [0|0] "" X
 SG_ BCFDM_nonLINCinchMotorDriven: 19|1@1+ (1,0) [0|0] "" X
 SG_ BCFDM_nonLINOpenSwitchActive: 13|1@1+ (1,0) [0|0] "" X
 SG_ BCFDM_nonLINReleaseMotorDriven: 11|1@1+ (1,0) [0|0] "" X

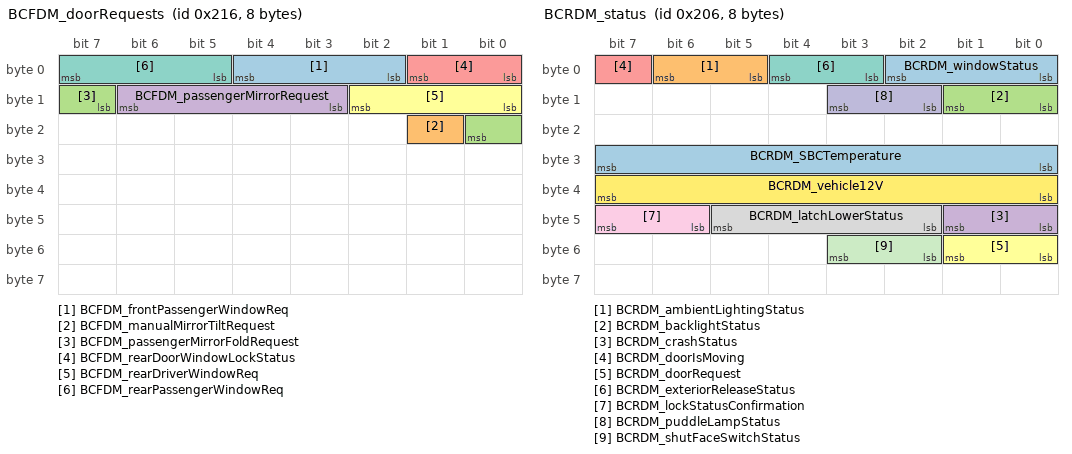
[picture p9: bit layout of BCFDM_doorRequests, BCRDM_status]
BO_ 534 BCFDM_doorRequests: 8 ETH
 SG_ BCFDM_frontPassengerWindowReq: 2|3@1+ (1,0) [0|0] "" X
 SG_ BCFDM_manualMirrorTiltRequest: 17|1@1+ (1,0) [0|0] "" X
 SG_ BCFDM_passengerMirrorFoldRequest: 15|2@1+ (1,0) [0|0] "" X
 SG_ BCFDM_passengerMirrorRequest: 11|4@1+ (1,0) [0|0] "" X
 SG_ BCFDM_rearDoorWindowLockStatus: 0|2@1+ (1,0) [0|0] "" X
 SG_ BCFDM_rearDriverWindowReq: 8|3@1+ (1,0) [0|0] "" X
 SG_ BCFDM_rearPassengerWindowReq: 5|3@1+ (1,0) [0|0] "" X

BO_ 1295 BCFDM_info: 8 ETH
 SG_ BCFDM_infoIndex M: 0|8@1+ (1,0) [0|0] "" X
 SG_ BCFDM_infoBuildType m10: 8|8@1+ (1,0) [0|0] "" X
 SG_ BCFDM_infoBuildConfigID m10: 16|16@1+ (1,0) [0|0] "" X
 SG_ BCFDM_infoHardwareID m10: 32|16@1+ (1,0) [0|0] "" X
 SG_ BCFDM_infoComponentID m10: 48|16@1+ (1,0) [0|0] "" X
 SG_ BCFDM_infoPcbaID m11: 16|8@1+ (1,0) [0|0] "" X
 SG_ BCFDM_infoAssemblyID m11: 24|8@1+ (1,0) [0|0] "INTEGRAL" X
 SG_ BCFDM_infoUsageID m11: 32|16@1+ (1,0) [0|0] "" X
 SG_ BCFDM_infoSubUsageID m11: 48|16@1+ (1,0) [0|0] "" X
 SG_ BCFDM_infoApplicationCRC m13: 32|32@1+ (1,0) [0|0] "" X
 SG_ BCFDM_infoBootSvnRev m14: 8|24@1+ (1,0) [0|0] "" X
 SG_ BCFDM_infoAppGitHashBytes m17: 10|54@1+ (4,0) [0|0] "" X
 SG_ BCFDM_infoBootGitHashBytes m18: 10|54@1+ (4,0) [0|0] "" X
 SG_ BCFDM_infoPlatformType m19: 8|8@1+ (1,0) [0|0] "" X
 SG_ BCFDM_infoBootUdsProtoVersion m20: 8|8@1+ (1,0) [0|0] "" X
 SG_ BCFDM_infoBootloaderCRC m20: 32|32@1+ (1,0) [0|0] "" X

BO_ 514 BCFDM_status: 8 ETH
 SG_ BCFDM_PFDSimpleState: 52|3@1+ (1,0) [0|0] "" X
 SG_ BCFDM_SBCTemperature: 24|8@1- (1,0) [0|0] "C" X
 SG_ BCFDM_ambientLightingStatus: 4|4@1+ (1,0) [0|0] "" X
 SG_ BCFDM_backlightStatus: 20|2@1+ (1,0) [0|0] "" X
 SG_ BCFDM_crashStatus: 22|2@1+ (1,0) [0|0] "" X
 SG_ BCFDM_doorHandleLampStatus: 50|2@1+ (1,0) [0|0] "" X
 SG_ BCFDM_doorIsMoving: 11|1@1+ (1,0) [0|0] "" X
 SG_ BCFDM_doorNextAction: 59|1@1+ (1,0) [0|0] "" X
 SG_ BCFDM_doorPercentOpen: 32|8@1+ (0.5,0) [0|0] "%" X
 SG_ BCFDM_exteriorReleaseStatus: 14|2@1+ (1,0) [0|0] "" X
 SG_ BCFDM_interiorReleaseStatus: 12|2@1+ (1,0) [0|0] "" X
 SG_ BCFDM_keyLocationRequired: 55|1@1+ (1,0) [0|0] "" X
 SG_ BCFDM_latchStatus: 0|4@1+ (1,0) [0|0] "" X
 SG_ BCFDM_lockStatusConfirmation: 16|2@1+ (1,0) [0|0] "" X
 SG_ BCFDM_masterKeyChannel: 56|3@1+ (1,0) [0|0] "" X
 SG_ BCFDM_partyStatus: 60|3@1+ (1,0) [0|0] "" X
 SG_ BCFDM_puddleLampStatus: 18|2@1+ (1,0) [0|0] "" X
 SG_ BCFDM_vehicle12V: 40|8@1+ (0.1,0) [0|0] "V" X
 SG_ BCFDM_windowStatus: 8|3@1+ (1,0) [0|0] "" X

BO_ 1716 BCFDM_udsResponse: 8 ETH
 SG_ BCFDM_udsResponseData_H: 0|32@0+ (1,0) [0|0] "" X
 SG_ BCFDM_udsResponseData_L: 32|32@0+ (1,0) [0|0] "" X

BO_ 872 BCFDM_warningMatrix1: 8 ETH
 SG_ BCFDM_w001_WatchdogReset: 0|1@1+ (1,0) [0|0] "" X
 SG_ BCFDM_w002_PowerLossReset: 1|1@1+ (1,0) [0|0] "" X
 SG_ BCFDM_w003_SWAssertion: 2|1@1+ (1,0) [0|0] "" X
 SG_ BCFDM_w004_CANMIA: 3|1@1+ (1,0) [0|0] "" X
 SG_ BCFDM_w005_CANHighError: 4|1@1+ (1,0) [0|0] "" X
 SG_ BCFDM_w006_CANLowError: 5|1@1+ (1,0) [0|0] "" X
 SG_ BCFDM_w007_LINTimeout: 6|1@1+ (1,0) [0|0] "" X
 SG_ BCFDM_w008_LIN2Error: 7|1@1+ (1,0) [0|0] "" X
 SG_ BCFDM_w009_LIN3Error: 8|1@1+ (1,0) [0|0] "" X
 SG_ BCFDM_w010_ExtSupplyVoltError: 9|1@1+ (1,0) [0|0] "" X
 SG_ BCFDM_w011_ECUSupplyVoltError: 10|1@1+ (1,0) [0|0] "" X
 SG_ BCFDM_w012_CPUReset: 11|1@1+ (1,0) [0|0] "" X
 SG_ BCFDM_w013_Shared13: 12|1@1+ (1,0) [0|0] "" X
 SG_ BCFDM_w014_BridgeFault: 13|1@1+ (1,0) [0|0] "" X
 SG_ BCFDM_w015_NVMMAlert: 14|1@1+ (1,0) [0|0] "" X
 SG_ BCFDM_w016_MessageTimingError: 15|1@1+ (1,0) [0|0] "" X
 SG_ BCFDM_w017_AwakeForTooLong: 16|1@1+ (1,0) [0|0] "" X
 SG_ BCFDM_w018_ADCError: 17|1@1+ (1,0) [0|0] "" X
 SG_ BCFDM_w019_I2CError: 18|1@1+ (1,0) [0|0] "" X
 SG_ BCFDM_w020_PWMError: 19|1@1+ (1,0) [0|0] "" X
 SG_ BCFDM_w021_TaskSchedulerError: 20|1@1+ (1,0) [0|0] "" X
 SG_ BCFDM_w022_TaskInitError: 21|1@1+ (1,0) [0|0] "" X
 SG_ BCFDM_w023_SleepError: 22|1@1+ (1,0) [0|0] "" X
 SG_ BCFDM_w024_WakeError: 23|1@1+ (1,0) [0|0] "" X
 SG_ BCFDM_w025_CrashEvent: 24|1@1+ (1,0) [0|0] "" X
 SG_ BCFDM_w026_FlashMemoryError: 25|1@1+ (1,0) [0|0] "" X
 SG_ BCFDM_w027_NVRAMCorruption: 26|1@1+ (1,0) [0|0] "" X
 SG_ BCFDM_w028_NVRAMNotResponding: 27|1@1+ (1,0) [0|0] "" X
 SG_ BCFDM_w029_NVRAMUninitialized: 28|1@1+ (1,0) [0|0] "" X
 SG_ BCFDM_w030_LockedDoorOpened: 29|1@1+ (1,0) [0|0] "" X
 SG_ BCFDM_w031_WindowRegulator: 30|1@1+ (1,0) [0|0] "" X
 SG_ BCFDM_w032_WindowCommError: 31|1@1+ (1,0) [0|0] "" X
 SG_ BCFDM_w033_PuddleLamp: 32|1@1+ (1,0) [0|0] "" X
 SG_ BCFDM_w034_WindowSwitchLED: 33|1@1+ (1,0) [0|0] "" X
 SG_ BCFDM_w035_AmbientLighting: 34|1@1+ (1,0) [0|0] "" X
 SG_ BCFDM_w036_InteriorSwitch: 35|1@1+ (1,0) [0|0] "" X
 SG_ BCFDM_w037_ExteriorSwitch: 36|1@1+ (1,0) [0|0] "" X
 SG_ BCFDM_w038_SwitchpackError: 37|1@1+ (1,0) [0|0] "" X
 SG_ BCFDM_w039_MirrorMovement: 38|1@1+ (1,0) [0|0] "" X
 SG_ BCFDM_w040_MirrorMotor: 39|1@1+ (1,0) [0|0] "" X
 SG_ BCFDM_w041_MirrorPosition: 40|1@1+ (1,0) [0|0] "" X
 SG_ BCFDM_w042_MirrorMemory: 41|1@1+ (1,0) [0|0] "" X
 SG_ BCFDM_w043_MirrorFolding: 42|1@1+ (1,0) [0|0] "" X
 SG_ BCFDM_w044_MirrorHeat: 43|1@1+ (1,0) [0|0] "" X
 SG_ BCFDM_w045_doorIcedRetryUnlatch: 44|1@1+ (1,0) [0|0] "" X
 SG_ BCFDM_w046_DoorIceBreaker: 45|1@1+ (1,0) [0|0] "" X
 SG_ BCFDM_w047_DoorEncoder: 46|1@1+ (1,0) [0|0] "" X
 SG_ BCFDM_w048_DoorMotor: 47|1@1+ (1,0) [0|0] "" X
 SG_ BCFDM_w049_DoorStall: 48|1@1+ (1,0) [0|0] "" X
 SG_ BCFDM_w050_DoorReactiveObstacle: 49|1@1+ (1,0) [0|0] "" X
 SG_ BCFDM_w051_DoorBrake: 50|1@1+ (1,0) [0|0] "" X
 SG_ BCFDM_w052_PFDBadState: 51|1@1+ (1,0) [0|0] "" X
 SG_ BCFDM_w053_PFDIOInit: 52|1@1+ (1,0) [0|0] "" X
 SG_ BCFDM_w054_PFDIOProcessData: 53|1@1+ (1,0) [0|0] "" X
 SG_ BCFDM_w055_PFDSetState: 54|1@1+ (1,0) [0|0] "" X
 SG_ BCFDM_w056_MirrorHeatError: 55|1@1+ (1,0) [0|0] "" X
 SG_ BCFDM_w057_ReflectorLamp: 56|1@1+ (1,0) [0|0] "" X
 SG_ BCFDM_w058_DoorConfigError: 57|1@1+ (1,0) [0|0] "" X
 SG_ BCFDM_w059_LatchCommError: 58|1@1+ (1,0) [0|0] "" X
 SG_ BCFDM_w060_LatchReportsFailure: 59|1@1+ (1,0) [0|0] "" X
 SG_ BCFDM_w061_DoorBrakeUncalibrated: 60|1@1+ (1,0) [0|0] "" X
 SG_ BCFDM_w062_PFDLinkageFault: 61|1@1+ (1,0) [0|0] "" X
 SG_ BCFDM_w063_LatchSwitchError: 62|1@1+ (1,0) [0|0] "" X
 SG_ BCFDM_w064_LatchReleaseError: 63|1@1+ (1,0) [0|0] "" X

BO_ 988 BCFDM_warningMatrix2: 8 ETH
 SG_ BCFDM_w065_ratchetingDetected: 0|1@1+ (1,0) [0|0] "" X
 SG_ BCFDM_w066_falseLatchCinch: 1|1@1+ (1,0) [0|0] "" X
 SG_ BCFDM_w067_missedShortDrop: 2|1@1+ (1,0) [0|0] "" X
 SG_ BCFDM_w068_missedUndrop: 3|1@1+ (1,0) [0|0] "" X
 SG_ BCFDM_w069_LatchStatusIgnored: 4|1@1+ (1,0) [0|0] "" X
 SG_ BCFDM_w070_LatchFailedToCinch: 5|1@1+ (1,0) [0|0] "" X
 SG_ BCFDM_w071_LatchFailedToRelease: 6|1@1+ (1,0) [0|0] "" X
 SG_ BCFDM_w072_UnexpectLatchClosed: 7|1@1+ (1,0) [0|0] "" X
 SG_ BCFDM_w073_UnexpectLatchOpen: 8|1@1+ (1,0) [0|0] "" X
 SG_ BCFDM_w074_NoLatchEntryOnClose: 9|1@1+ (1,0) [0|0] "" X
 SG_ BCFDM_w075_DoorIceBreakerAttempt: 10|1@1+ (1,0) [0|0] "" X
 SG_ BCFDM_w076_DoorIceBreakerFailure: 11|1@1+ (1,0) [0|0] "" X
 SG_ BCFDM_w077_LatchMechReleaseStuck: 12|1@1+ (1,0) [0|0] "" X
 SG_ BCFDM_w078_DoorUnzeroed: 13|1@1+ (1,0) [0|0] "" X
 SG_ BCFDM_w079_DvrSideCfgMismatch: 14|1@1+ (1,0) [0|0] "" X
 SG_ BCFDM_w080_CurrentDropOut: 15|1@1+ (1,0) [0|0] "" X
 SG_ BCFDM_w081_LatchOpenInMotion: 16|1@1+ (1,0) [0|0] "" X
 SG_ BCFDM_w082_doorZeroed: 17|1@1+ (1,0) [0|0] "" X
 SG_ BCFDM_w083_UnexpectedStop: 18|1@1+ (1,0) [0|0] "" X
 SG_ BCFDM_w084_ReleaseEndStop: 19|1@1+ (1,0) [0|0] "" X
 SG_ BCFDM_w085_ESPGyroUnstable: 20|1@1+ (1,0) [0|0] "" X
 SG_ BCFDM_w086_badESPData: 21|1@1+ (1,0) [0|0] "" X
 SG_ BCFDM_w087_MirrTiltTestFailure: 22|1@1+ (1,0) [0|0] "" X
 SG_ BCFDM_w090_CrashUnlockError: 25|1@1+ (1,0) [0|0] "" X
 SG_ BCFDM_w091_CrashStateMismatch: 26|1@1+ (1,0) [0|0] "" X
 SG_ BCFDM_w093_OTPError: 28|1@1+ (1,0) [0|0] "" X
 SG_ BCFDM_w105_ECUDebugMode: 40|1@1+ (1,0) [0|0] "" X
 SG_ BCFDM_w106_HighCPULoad: 41|1@1+ (1,0) [0|0] "" X
 SG_ BCFDM_w107_HighStackUsage: 42|1@1+ (1,0) [0|0] "" X

BO_ 1957 BCFPM_debug: 3 ETH
 SG_ BCFPM_LINFailure: 3|4@1+ (1,0) [0|0] "" X
 SG_ BCFPM_LINMechRelease: 7|1@1+ (1,0) [0|0] "" X
 SG_ BCFPM_LINOpenRequested: 8|1@1+ (1,0) [0|0] "" X
 SG_ BCFPM_LINStatus: 0|3@1+ (1,0) [0|0] "" X
 SG_ BCFPM_LINVehicleLocked: 9|1@1+ (1,0) [0|0] "" X
 SG_ BCFPM_LINVehicleMoving: 10|1@1+ (1,0) [0|0] "" X
 SG_ BCFPM_cinchStatusSwitchActive: 20|1@1+ (1,0) [0|0] "" X
 SG_ BCFPM_cinchStatusSwitchEnabled: 21|1@1+ (1,0) [0|0] "" X
 SG_ BCFPM_keyAbsenceCloseReqStatus: 18|1@1+ (1,0) [0|0] "" X
 SG_ BCFPM_keyLocationCloseReqStatus: 17|1@1+ (1,0) [0|0] "" X
 SG_ BCFPM_keyLockInhibitAutoPresent: 16|1@1+ (1,0) [0|0] "" X
 SG_ BCFPM_keyRegionOpenReqStatus: 14|1@1+ (1,0) [0|0] "" X
 SG_ BCFPM_keyVectorOpenReqStatus: 15|1@1+ (1,0) [0|0] "" X
 SG_ BCFPM_nonLINAjarSwitchActive: 12|1@1+ (1,0) [0|0] "" X
 SG_ BCFPM_nonLINCinchMotorDriven: 19|1@1+ (1,0) [0|0] "" X
 SG_ BCFPM_nonLINOpenSwitchActive: 13|1@1+ (1,0) [0|0] "" X
 SG_ BCFPM_nonLINReleaseMotorDriven: 11|1@1+ (1,0) [0|0] "" X

BO_ 1296 BCFPM_info: 8 ETH
 SG_ BCFPM_infoIndex M: 0|8@1+ (1,0) [0|0] "" X
 SG_ BCFPM_infoBuildType m10: 8|8@1+ (1,0) [0|0] "" X
 SG_ BCFPM_infoBuildConfigID m10: 16|16@1+ (1,0) [0|0] "" X
 SG_ BCFPM_infoHardwareID m10: 32|16@1+ (1,0) [0|0] "" X
 SG_ BCFPM_infoComponentID m10: 48|16@1+ (1,0) [0|0] "" X
 SG_ BCFPM_infoPcbaID m11: 16|8@1+ (1,0) [0|0] "" X
 SG_ BCFPM_infoAssemblyID m11: 24|8@1+ (1,0) [0|0] "INTEGRAL" X
 SG_ BCFPM_infoUsageID m11: 32|16@1+ (1,0) [0|0] "" X
 SG_ BCFPM_infoSubUsageID m11: 48|16@1+ (1,0) [0|0] "" X
 SG_ BCFPM_infoApplicationCRC m13: 32|32@1+ (1,0) [0|0] "" X
 SG_ BCFPM_infoBootSvnRev m14: 8|24@1+ (1,0) [0|0] "" X
 SG_ BCFPM_infoAppGitHashBytes m17: 10|54@1+ (4,0) [0|0] "" X
 SG_ BCFPM_infoBootGitHashBytes m18: 10|54@1+ (4,0) [0|0] "" X
 SG_ BCFPM_infoPlatformType m19: 8|8@1+ (1,0) [0|0] "" X
 SG_ BCFPM_infoBootUdsProtoVersion m20: 8|8@1+ (1,0) [0|0] "" X
 SG_ BCFPM_infoBootloaderCRC m20: 32|32@1+ (1,0) [0|0] "" X

BO_ 512 BCFPM_status: 8 ETH
 SG_ BCFPM_PFDSimpleState: 52|3@1+ (1,0) [0|0] "" X
 SG_ BCFPM_SBCTemperature: 24|8@1- (1,0) [0|0] "C" X
 SG_ BCFPM_ambientLightingStatus: 4|4@1+ (1,0) [0|0] "" X
 SG_ BCFPM_backlightStatus: 20|2@1+ (1,0) [0|0] "" X
 SG_ BCFPM_crashStatus: 22|2@1+ (1,0) [0|0] "" X
 SG_ BCFPM_doorHandleLampStatus: 50|2@1+ (1,0) [0|0] "" X
 SG_ BCFPM_doorIsMoving: 11|1@1+ (1,0) [0|0] "" X
 SG_ BCFPM_doorNextAction: 59|1@1+ (1,0) [0|0] "" X
 SG_ BCFPM_doorPercentOpen: 32|8@1+ (0.5,0) [0|0] "%" X
 SG_ BCFPM_exteriorReleaseStatus: 14|2@1+ (1,0) [0|0] "" X
 SG_ BCFPM_interiorReleaseStatus: 12|2@1+ (1,0) [0|0] "" X
 SG_ BCFPM_keyLocationRequired: 55|1@1+ (1,0) [0|0] "" X
 SG_ BCFPM_latchStatus: 0|4@1+ (1,0) [0|0] "" X
 SG_ BCFPM_lockStatusConfirmation: 16|2@1+ (1,0) [0|0] "" X
 SG_ BCFPM_masterKeyChannel: 56|3@1+ (1,0) [0|0] "" X
 SG_ BCFPM_partyStatus: 60|3@1+ (1,0) [0|0] "" X
 SG_ BCFPM_puddleLampStatus: 18|2@1+ (1,0) [0|0] "" X
 SG_ BCFPM_vehicle12V: 40|8@1+ (0.1,0) [0|0] "V" X
 SG_ BCFPM_windowStatus: 8|3@1+ (1,0) [0|0] "" X

BO_ 1717 BCFPM_udsResponse: 8 ETH
 SG_ BCFPM_udsResponseData_H: 0|32@0+ (1,0) [0|0] "" X
 SG_ BCFPM_udsResponseData_L: 32|32@0+ (1,0) [0|0] "" X

BO_ 773 BCFPM_warningMatrix1: 8 ETH
 SG_ BCFPM_w001_WatchdogReset: 0|1@1+ (1,0) [0|0] "" X
 SG_ BCFPM_w002_PowerLossReset: 1|1@1+ (1,0) [0|0] "" X
 SG_ BCFPM_w003_SWAssertion: 2|1@1+ (1,0) [0|0] "" X
 SG_ BCFPM_w004_CANMIA: 3|1@1+ (1,0) [0|0] "" X
 SG_ BCFPM_w005_CANHighError: 4|1@1+ (1,0) [0|0] "" X
 SG_ BCFPM_w006_CANLowError: 5|1@1+ (1,0) [0|0] "" X
 SG_ BCFPM_w007_LINTimeout: 6|1@1+ (1,0) [0|0] "" X
 SG_ BCFPM_w008_LIN2Error: 7|1@1+ (1,0) [0|0] "" X
 SG_ BCFPM_w009_LIN3Error: 8|1@1+ (1,0) [0|0] "" X
 SG_ BCFPM_w010_ExtSupplyVoltError: 9|1@1+ (1,0) [0|0] "" X
 SG_ BCFPM_w011_ECUSupplyVoltError: 10|1@1+ (1,0) [0|0] "" X
 SG_ BCFPM_w012_CPUReset: 11|1@1+ (1,0) [0|0] "" X
 SG_ BCFPM_w013_Shared13: 12|1@1+ (1,0) [0|0] "" X
 SG_ BCFPM_w014_BridgeFault: 13|1@1+ (1,0) [0|0] "" X
 SG_ BCFPM_w015_NVMMAlert: 14|1@1+ (1,0) [0|0] "" X
 SG_ BCFPM_w016_MessageTimingError: 15|1@1+ (1,0) [0|0] "" X
 SG_ BCFPM_w017_AwakeForTooLong: 16|1@1+ (1,0) [0|0] "" X
 SG_ BCFPM_w018_ADCError: 17|1@1+ (1,0) [0|0] "" X
 SG_ BCFPM_w019_I2CError: 18|1@1+ (1,0) [0|0] "" X
 SG_ BCFPM_w020_PWMError: 19|1@1+ (1,0) [0|0] "" X
 SG_ BCFPM_w021_TaskSchedulerError: 20|1@1+ (1,0) [0|0] "" X
 SG_ BCFPM_w022_TaskInitError: 21|1@1+ (1,0) [0|0] "" X
 SG_ BCFPM_w023_SleepError: 22|1@1+ (1,0) [0|0] "" X
 SG_ BCFPM_w024_WakeError: 23|1@1+ (1,0) [0|0] "" X
 SG_ BCFPM_w025_CrashEvent: 24|1@1+ (1,0) [0|0] "" X
 SG_ BCFPM_w026_FlashMemoryError: 25|1@1+ (1,0) [0|0] "" X
 SG_ BCFPM_w027_NVRAMCorruption: 26|1@1+ (1,0) [0|0] "" X
 SG_ BCFPM_w028_NVRAMNotResponding: 27|1@1+ (1,0) [0|0] "" X
 SG_ BCFPM_w029_NVRAMUninitialized: 28|1@1+ (1,0) [0|0] "" X
 SG_ BCFPM_w030_LockedDoorOpened: 29|1@1+ (1,0) [0|0] "" X
 SG_ BCFPM_w031_WindowRegulator: 30|1@1+ (1,0) [0|0] "" X
 SG_ BCFPM_w032_WindowCommError: 31|1@1+ (1,0) [0|0] "" X
 SG_ BCFPM_w033_PuddleLamp: 32|1@1+ (1,0) [0|0] "" X
 SG_ BCFPM_w034_WindowSwitchLED: 33|1@1+ (1,0) [0|0] "" X
 SG_ BCFPM_w035_AmbientLighting: 34|1@1+ (1,0) [0|0] "" X
 SG_ BCFPM_w036_InteriorSwitch: 35|1@1+ (1,0) [0|0] "" X
 SG_ BCFPM_w037_ExteriorSwitch: 36|1@1+ (1,0) [0|0] "" X
 SG_ BCFPM_w038_SwitchpackError: 37|1@1+ (1,0) [0|0] "" X
 SG_ BCFPM_w039_MirrorMovement: 38|1@1+ (1,0) [0|0] "" X
 SG_ BCFPM_w040_MirrorMotor: 39|1@1+ (1,0) [0|0] "" X
 SG_ BCFPM_w041_MirrorPosition: 40|1@1+ (1,0) [0|0] "" X
 SG_ BCFPM_w042_MirrorMemory: 41|1@1+ (1,0) [0|0] "" X
 SG_ BCFPM_w043_MirrorFolding: 42|1@1+ (1,0) [0|0] "" X
 SG_ BCFPM_w044_MirrorHeat: 43|1@1+ (1,0) [0|0] "" X
 SG_ BCFPM_w045_doorIcedRetryUnlatch: 44|1@1+ (1,0) [0|0] "" X
 SG_ BCFPM_w046_DoorIceBreaker: 45|1@1+ (1,0) [0|0] "" X
 SG_ BCFPM_w047_DoorEncoder: 46|1@1+ (1,0) [0|0] "" X
 SG_ BCFPM_w048_DoorMotor: 47|1@1+ (1,0) [0|0] "" X
 SG_ BCFPM_w049_DoorStall: 48|1@1+ (1,0) [0|0] "" X
 SG_ BCFPM_w050_DoorReactiveObstacle: 49|1@1+ (1,0) [0|0] "" X
 SG_ BCFPM_w051_DoorBrake: 50|1@1+ (1,0) [0|0] "" X
 SG_ BCFPM_w052_PFDBadState: 51|1@1+ (1,0) [0|0] "" X
 SG_ BCFPM_w053_PFDIOInit: 52|1@1+ (1,0) [0|0] "" X
 SG_ BCFPM_w054_PFDIOProcessData: 53|1@1+ (1,0) [0|0] "" X
 SG_ BCFPM_w055_PFDSetState: 54|1@1+ (1,0) [0|0] "" X
 SG_ BCFPM_w056_MirrorHeatError: 55|1@1+ (1,0) [0|0] "" X
 SG_ BCFPM_w057_ReflectorLamp: 56|1@1+ (1,0) [0|0] "" X
 SG_ BCFPM_w058_DoorConfigError: 57|1@1+ (1,0) [0|0] "" X
 SG_ BCFPM_w059_LatchCommError: 58|1@1+ (1,0) [0|0] "" X
 SG_ BCFPM_w060_LatchReportsFailure: 59|1@1+ (1,0) [0|0] "" X
 SG_ BCFPM_w061_DoorBrakeUncalibrated: 60|1@1+ (1,0) [0|0] "" X
 SG_ BCFPM_w062_PFDLinkageFault: 61|1@1+ (1,0) [0|0] "" X
 SG_ BCFPM_w063_LatchSwitchError: 62|1@1+ (1,0) [0|0] "" X
 SG_ BCFPM_w064_LatchReleaseError: 63|1@1+ (1,0) [0|0] "" X

BO_ 789 BCFPM_warningMatrix2: 8 ETH
 SG_ BCFPM_w065_ratchetingDetected: 0|1@1+ (1,0) [0|0] "" X
 SG_ BCFPM_w066_falseLatchCinch: 1|1@1+ (1,0) [0|0] "" X
 SG_ BCFPM_w067_missedShortDrop: 2|1@1+ (1,0) [0|0] "" X
 SG_ BCFPM_w068_missedUndrop: 3|1@1+ (1,0) [0|0] "" X
 SG_ BCFPM_w069_LatchStatusIgnored: 4|1@1+ (1,0) [0|0] "" X
 SG_ BCFPM_w070_LatchFailedToCinch: 5|1@1+ (1,0) [0|0] "" X
 SG_ BCFPM_w071_LatchFailedToRelease: 6|1@1+ (1,0) [0|0] "" X
 SG_ BCFPM_w072_UnexpectLatchClosed: 7|1@1+ (1,0) [0|0] "" X
 SG_ BCFPM_w073_UnexpectLatchOpen: 8|1@1+ (1,0) [0|0] "" X
 SG_ BCFPM_w074_NoLatchEntryOnClose: 9|1@1+ (1,0) [0|0] "" X
 SG_ BCFPM_w075_DoorIceBreakerAttempt: 10|1@1+ (1,0) [0|0] "" X
 SG_ BCFPM_w076_DoorIceBreakerFailure: 11|1@1+ (1,0) [0|0] "" X
 SG_ BCFPM_w077_LatchMechReleaseStuck: 12|1@1+ (1,0) [0|0] "" X
 SG_ BCFPM_w078_DoorUnzeroed: 13|1@1+ (1,0) [0|0] "" X
 SG_ BCFPM_w079_DvrSideCfgMismatch: 14|1@1+ (1,0) [0|0] "" X
 SG_ BCFPM_w080_CurrentDropOut: 15|1@1+ (1,0) [0|0] "" X
 SG_ BCFPM_w081_LatchOpenInMotion: 16|1@1+ (1,0) [0|0] "" X
 SG_ BCFPM_w082_doorZeroed: 17|1@1+ (1,0) [0|0] "" X
 SG_ BCFPM_w083_UnexpectedStop: 18|1@1+ (1,0) [0|0] "" X
 SG_ BCFPM_w084_ReleaseEndStop: 19|1@1+ (1,0) [0|0] "" X
 SG_ BCFPM_w085_ESPGyroUnstable: 20|1@1+ (1,0) [0|0] "" X
 SG_ BCFPM_w086_badESPData: 21|1@1+ (1,0) [0|0] "" X
 SG_ BCFPM_w087_MirrTiltTestFailure: 22|1@1+ (1,0) [0|0] "" X
 SG_ BCFPM_w090_CrashUnlockError: 25|1@1+ (1,0) [0|0] "" X
 SG_ BCFPM_w091_CrashStateMismatch: 26|1@1+ (1,0) [0|0] "" X
 SG_ BCFPM_w093_OTPError: 28|1@1+ (1,0) [0|0] "" X
 SG_ BCFPM_w105_ECUDebugMode: 40|1@1+ (1,0) [0|0] "" X
 SG_ BCFPM_w106_HighCPULoad: 41|1@1+ (1,0) [0|0] "" X
 SG_ BCFPM_w107_HighStackUsage: 42|1@1+ (1,0) [0|0] "" X

BO_ 1301 BCFRONT_info: 8 ETH
 SG_ BCFRONT_infoIndex M: 0|8@1+ (1,0) [0|0] "" X
 SG_ BCFRONT_infoBuildType m10: 8|8@1+ (1,0) [0|0] "" X
 SG_ BCFRONT_infoBuildConfigID m10: 16|16@1+ (1,0) [0|0] "" X
 SG_ BCFRONT_infoHardwareID m10: 32|16@1+ (1,0) [0|0] "" X
 SG_ BCFRONT_infoComponentID m10: 48|16@1+ (1,0) [0|0] "" X
 SG_ BCFRONT_infoPcbaID m11: 16|8@1+ (1,0) [0|0] "" X
 SG_ BCFRONT_infoAssemblyID m11: 24|8@1+ (1,0) [0|0] "INTEGRAL" X
 SG_ BCFRONT_infoUsageID m11: 32|16@1+ (1,0) [0|0] "" X
 SG_ BCFRONT_infoSubUsageID m11: 48|16@1+ (1,0) [0|0] "" X
 SG_ BCFRONT_infoApplicationCRC m13: 32|32@1+ (1,0) [0|0] "" X
 SG_ BCFRONT_infoBootSvnRev m14: 8|24@1+ (1,0) [0|0] "" X
 SG_ BCFRONT_infoSubcomponent1 m16: 16|32@1+ (1,0) [0|0] "" X
 SG_ BCFRONT_infoAppGitHashBytes m17: 10|54@1+ (4,0) [0|0] "" X
 SG_ BCFRONT_infoBootGitHashBytes m18: 10|54@1+ (4,0) [0|0] "" X
 SG_ BCFRONT_infoPlatformType m19: 8|8@1+ (1,0) [0|0] "" X
 SG_ BCFRONT_infoBootUdsProtoVersion m20: 8|8@1+ (1,0) [0|0] "" X
 SG_ BCFRONT_infoBootloaderCRC m20: 32|32@1+ (1,0) [0|0] "" X
 SG_ BCFRONT_infoSubcomponent2 m23: 16|32@1+ (1,0) [0|0] "" X
 SG_ BCFRONT_infoSubcomponent3 m24: 16|32@1+ (1,0) [0|0] "" X
 SG_ BCFRONT_infoSubcomponent4 m31: 16|32@1+ (1,0) [0|0] "" X

BO_ 530 BCFRONT_lightStatus: 8 ETH
 SG_ BCFRONT_approachLightingActive: 48|2@1+ (1,0) [0|0] "" X
 SG_ BCFRONT_corneringLeft1Status: 32|2@1+ (1,0) [0|0] "" X
 SG_ BCFRONT_corneringLeft2Status: 34|2@1+ (1,0) [0|0] "" X
 SG_ BCFRONT_corneringLeft3Status: 36|2@1+ (1,0) [0|0] "" X
 SG_ BCFRONT_corneringRight1Status: 38|2@1+ (1,0) [0|0] "" X
 SG_ BCFRONT_corneringRight2Status: 40|2@1+ (1,0) [0|0] "" X
 SG_ BCFRONT_corneringRight3Status: 42|2@1+ (1,0) [0|0] "" X
 SG_ BCFRONT_drlLeftStatus: 44|2@1+ (1,0) [0|0] "" X
 SG_ BCFRONT_drlRightStatus: 46|2@1+ (1,0) [0|0] "" X
 SG_ BCFRONT_fasciaLeftECUPower: 58|2@1+ (1,0) [0|0] "" X
 SG_ BCFRONT_fasciaRightECUPower: 60|2@1+ (1,0) [0|0] "" X
 SG_ BCFRONT_fogLightLeftStatus: 16|2@1+ (1,0) [0|0] "" X
 SG_ BCFRONT_fogLightRightStatus: 18|2@1+ (1,0) [0|0] "" X
 SG_ BCFRONT_frunkLightStatus: 52|2@1+ (1,0) [0|0] "" X
 SG_ BCFRONT_headlightLeftECUPower: 54|2@1+ (1,0) [0|0] "" X
 SG_ BCFRONT_headlightRightECUPower: 56|2@1+ (1,0) [0|0] "" X
 SG_ BCFRONT_highBeamLeftStatus: 8|2@1+ (1,0) [0|0] "" X
 SG_ BCFRONT_highBeamRightStatus: 10|2@1+ (1,0) [0|0] "" X
 SG_ BCFRONT_indicatorLeftStatus: 20|2@1+ (1,0) [0|0] "" X
 SG_ BCFRONT_indicatorRightStatus: 22|2@1+ (1,0) [0|0] "" X
 SG_ BCFRONT_lowBeamLeftStatus: 0|2@1+ (1,0) [0|0] "" X
 SG_ BCFRONT_lowBeamRightStatus: 2|2@1+ (1,0) [0|0] "" X
 SG_ BCFRONT_lowBeamsOnlyForDRL: 62|1@1+ (1,0) [0|0] "" X
 SG_ BCFRONT_parkLeftStatus: 28|2@1+ (1,0) [0|0] "" X
 SG_ BCFRONT_parkRightStatus: 30|2@1+ (1,0) [0|0] "" X
 SG_ BCFRONT_repeaterLeftStatus: 24|2@1+ (1,0) [0|0] "" X
 SG_ BCFRONT_repeaterRightStatus: 26|2@1+ (1,0) [0|0] "" X
 SG_ BCFRONT_seeYouHomeLightingActive: 50|2@1+ (1,0) [0|0] "" X
 SG_ BCFRONT_sideMarkerLeftStatus: 12|2@1+ (1,0) [0|0] "" X
 SG_ BCFRONT_sideMarkerRightStatus: 14|2@1+ (1,0) [0|0] "" X
 SG_ BCFRONT_signatureLeftStatus: 4|2@1+ (1,0) [0|0] "" X
 SG_ BCFRONT_signatureRightStatus: 6|2@1+ (1,0) [0|0] "" X

BO_ 527 BCFRONT_status: 8 ETH
 SG_ BCFRONT_SBCTemperature: 24|8@1- (1,0) [0|0] "C" X
 SG_ BCFRONT_brakeFluidLevel: 14|2@1+ (1,0) [0|0] "" X
 SG_ BCFRONT_crashStatus: 40|2@1+ (1,0) [0|0] "" X
 SG_ BCFRONT_frontLeftRideHeight: 44|8@1+ (1,-100) [0|0] "mm" X
 SG_ BCFRONT_frunkIntSwStatus: 12|2@1+ (1,0) [0|0] "" X
 SG_ BCFRONT_frunkLatchStatus: 0|4@1+ (1,0) [0|0] "" X
 SG_ BCFRONT_headlampLevelSetting: 52|3@1+ (1,0) [0|0] "" X
 SG_ BCFRONT_homelinkPowerStatus: 42|2@1+ (1,0) [0|0] "" X
 SG_ BCFRONT_hornStatus: 16|2@1+ (1,0) [0|0] "" X
 SG_ BCFRONT_leftFasciaLampFWVersion: 55|4@1+ (1,0) [0|0] "" X
 SG_ BCFRONT_lowBeamReason: 20|3@1+ (1,0) [0|0] "" X
 SG_ BCFRONT_rearDefrostStatus: 4|2@1+ (1,0) [0|0] "" X
 SG_ BCFRONT_rightFasciaLampFWVersion: 59|4@1+ (1,0) [0|0] "" X
 SG_ BCFRONT_vehicle12V: 32|8@1+ (0.1,0) [0|0] "V" X
 SG_ BCFRONT_washPumpStatus: 6|2@1+ (1,0) [0|0] "" X
 SG_ BCFRONT_washerFluidLevel: 18|2@1+ (1,0) [0|0] "" X
 SG_ BCFRONT_wiperDefrostStatus: 10|2@1+ (1,0) [0|0] "" X
 SG_ BCFRONT_wiperNozzleDefrostStatus: 8|2@1+ (1,0) [0|0] "" X

BO_ 1715 BCFRONT_udsResponse: 8 ETH
 SG_ BCFRONT_udsResponseData_H: 0|32@0+ (1,0) [0|0] "" X
 SG_ BCFRONT_udsResponseData_L: 32|32@0+ (1,0) [0|0] "" X

BO_ 871 BCFRONT_warningMatrix1: 8 ETH
 SG_ BCFRONT_w001_WatchdogReset: 0|1@1+ (1,0) [0|0] "" X
 SG_ BCFRONT_w002_PowerLossReset: 1|1@1+ (1,0) [0|0] "" X
 SG_ BCFRONT_w003_SWAssertion: 2|1@1+ (1,0) [0|0] "" X
 SG_ BCFRONT_w004_CANMIA: 3|1@1+ (1,0) [0|0] "" X
 SG_ BCFRONT_w005_CANHighError: 4|1@1+ (1,0) [0|0] "" X
 SG_ BCFRONT_w006_CANLowError: 5|1@1+ (1,0) [0|0] "" X
 SG_ BCFRONT_w007_LINTimeout: 6|1@1+ (1,0) [0|0] "" X
 SG_ BCFRONT_w008_LIN2Error: 7|1@1+ (1,0) [0|0] "" X
 SG_ BCFRONT_w009_LIN3Error: 8|1@1+ (1,0) [0|0] "" X
 SG_ BCFRONT_w010_ExtSupplyVoltError: 9|1@1+ (1,0) [0|0] "" X
 SG_ BCFRONT_w011_ECUSupplyVoltError: 10|1@1+ (1,0) [0|0] "" X
 SG_ BCFRONT_w012_CPUReset: 11|1@1+ (1,0) [0|0] "" X
 SG_ BCFRONT_w013_Shared13: 12|1@1+ (1,0) [0|0] "" X
 SG_ BCFRONT_w014_BridgeFault: 13|1@1+ (1,0) [0|0] "" X
 SG_ BCFRONT_w015_NVMMAlert: 14|1@1+ (1,0) [0|0] "" X
 SG_ BCFRONT_w016_MessageTimingError: 15|1@1+ (1,0) [0|0] "" X
 SG_ BCFRONT_w017_AwakeForTooLong: 16|1@1+ (1,0) [0|0] "" X
 SG_ BCFRONT_w018_ADCError: 17|1@1+ (1,0) [0|0] "" X
 SG_ BCFRONT_w019_I2CError: 18|1@1+ (1,0) [0|0] "" X
 SG_ BCFRONT_w020_PWMError: 19|1@1+ (1,0) [0|0] "" X
 SG_ BCFRONT_w021_TaskSchedulerError: 20|1@1+ (1,0) [0|0] "" X
 SG_ BCFRONT_w022_TaskInitError: 21|1@1+ (1,0) [0|0] "" X
 SG_ BCFRONT_w023_SleepError: 22|1@1+ (1,0) [0|0] "" X
 SG_ BCFRONT_w024_WakeError: 23|1@1+ (1,0) [0|0] "" X
 SG_ BCFRONT_w025_CrashEvent: 24|1@1+ (1,0) [0|0] "" X
 SG_ BCFRONT_w026_FlashMemoryError: 25|1@1+ (1,0) [0|0] "" X
 SG_ BCFRONT_w027_NVRAMCorruption: 26|1@1+ (1,0) [0|0] "" X
 SG_ BCFRONT_w028_NVRAMNotResponding: 27|1@1+ (1,0) [0|0] "" X
 SG_ BCFRONT_w029_NVRAMUninitialized: 28|1@1+ (1,0) [0|0] "" X
 SG_ BCFRONT_w030_FrunkPriOvercurr: 29|1@1+ (1,0) [0|0] "" X
 SG_ BCFRONT_w031_FrunkPriUndercurr: 30|1@1+ (1,0) [0|0] "" X
 SG_ BCFRONT_w033_FrunkSecOvercurr: 32|1@1+ (1,0) [0|0] "" X
 SG_ BCFRONT_w034_FrunkSecUndercurr: 33|1@1+ (1,0) [0|0] "" X
 SG_ BCFRONT_w035_FrunkOpenedAtSpeed: 34|1@1+ (1,0) [0|0] "" X
 SG_ BCFRONT_w036_FrunkOpenRejected: 35|1@1+ (1,0) [0|0] "" X
 SG_ BCFRONT_w037_FrunkIntSwitchError: 36|1@1+ (1,0) [0|0] "" X
 SG_ BCFRONT_w038_FrunkIllumError: 37|1@1+ (1,0) [0|0] "" X
 SG_ BCFRONT_w039_FrunkReleaseMisuse: 38|1@1+ (1,0) [0|0] "" X
 SG_ BCFRONT_w040_FrunkReleaseError: 39|1@1+ (1,0) [0|0] "" X
 SG_ BCFRONT_w041_BrakeFluidLow: 40|1@1+ (1,0) [0|0] "" X
 SG_ BCFRONT_w042_BrakeFluidSwError: 41|1@1+ (1,0) [0|0] "" X
 SG_ BCFRONT_w043_WndshldWashFluidLow: 42|1@1+ (1,0) [0|0] "" X
 SG_ BCFRONT_w044_HomelinkError: 43|1@1+ (1,0) [0|0] "" X
 SG_ BCFRONT_w045_WiperDefrostError: 44|1@1+ (1,0) [0|0] "" X
 SG_ BCFRONT_w046_NozzleDefrostError: 45|1@1+ (1,0) [0|0] "" X
 SG_ BCFRONT_w047_RearDefrostError: 46|1@1+ (1,0) [0|0] "" X
 SG_ BCFRONT_w048_HeadlightLevelError: 47|1@1+ (1,0) [0|0] "" X
 SG_ BCFRONT_w049_WashPumpError: 48|1@1+ (1,0) [0|0] "" X
 SG_ BCFRONT_w050_HornOvercurrent: 49|1@1+ (1,0) [0|0] "" X
 SG_ BCFRONT_w051_HLDMLeftError: 50|1@1+ (1,0) [0|0] "" X
 SG_ BCFRONT_w052_HLDMLeftCommError: 51|1@1+ (1,0) [0|0] "" X
 SG_ BCFRONT_w053_LowBeamLeftError: 52|1@1+ (1,0) [0|0] "" X
 SG_ BCFRONT_w054_LowHiBeamLeftTemp: 53|1@1+ (1,0) [0|0] "" X
 SG_ BCFRONT_w055_HighBeamLeftError: 54|1@1+ (1,0) [0|0] "" X
 SG_ BCFRONT_w056_AFSError: 55|1@1+ (1,0) [0|0] "" X
 SG_ BCFRONT_w057_DRLLeftError: 56|1@1+ (1,0) [0|0] "" X
 SG_ BCFRONT_w058_SignatureLightLeft: 57|1@1+ (1,0) [0|0] "" X
 SG_ BCFRONT_w060_FLDMLeftError: 59|1@1+ (1,0) [0|0] "" X
 SG_ BCFRONT_w061_FLDMLeftCommError: 60|1@1+ (1,0) [0|0] "" X
 SG_ BCFRONT_w062_ParkLightError: 61|1@1+ (1,0) [0|0] "" X
 SG_ BCFRONT_w063_ParkLightLeftTemp: 62|1@1+ (1,0) [0|0] "" X
 SG_ BCFRONT_w064_FogLeftError: 63|1@1+ (1,0) [0|0] "" X

BO_ 787 BCFRONT_warningMatrix2: 8 ETH
 SG_ BCFRONT_w065_FogLeftTemp: 0|1@1+ (1,0) [0|0] "" X
 SG_ BCFRONT_w066_TurnIndicatorLeft: 1|1@1+ (1,0) [0|0] "" X
 SG_ BCFRONT_w067_SideMarkerLeft: 2|1@1+ (1,0) [0|0] "" X
 SG_ BCFRONT_w068_HLDMRightError: 3|1@1+ (1,0) [0|0] "" X
 SG_ BCFRONT_w069_HLDMRightCommError: 4|1@1+ (1,0) [0|0] "" X
 SG_ BCFRONT_w070_LowBeamRightError: 5|1@1+ (1,0) [0|0] "" X
 SG_ BCFRONT_w071_LowHiBeamRightTemp: 6|1@1+ (1,0) [0|0] "" X
 SG_ BCFRONT_w072_HighBeamRightError: 7|1@1+ (1,0) [0|0] "" X
 SG_ BCFRONT_w074_DRLRightError: 9|1@1+ (1,0) [0|0] "" X
 SG_ BCFRONT_w075_SignatureLightRight: 10|1@1+ (1,0) [0|0] "" X
 SG_ BCFRONT_w077_FLDMRightError: 12|1@1+ (1,0) [0|0] "" X
 SG_ BCFRONT_w078_FLDMRightCommError: 13|1@1+ (1,0) [0|0] "" X
 SG_ BCFRONT_w079_DvrSideCfgMismatch: 14|1@1+ (1,0) [0|0] "" X
 SG_ BCFRONT_w080_ParkLightRightTemp: 15|1@1+ (1,0) [0|0] "" X
 SG_ BCFRONT_w081_FogRightError: 16|1@1+ (1,0) [0|0] "" X
 SG_ BCFRONT_w082_FogRightTemp: 17|1@1+ (1,0) [0|0] "" X
 SG_ BCFRONT_w083_TurnIndicatorRight: 18|1@1+ (1,0) [0|0] "" X
 SG_ BCFRONT_w084_SideMarkerRight: 19|1@1+ (1,0) [0|0] "" X
 SG_ BCFRONT_w085_SideRepeaterLeft: 20|1@1+ (1,0) [0|0] "" X
 SG_ BCFRONT_w086_SideRepeaterRight: 21|1@1+ (1,0) [0|0] "" X
 SG_ BCFRONT_w087_HornDevStateError: 22|1@1+ (1,0) [0|0] "" X
 SG_ BCFRONT_w090_CrashUnlockError: 25|1@1+ (1,0) [0|0] "" X
 SG_ BCFRONT_w091_CrashStateMismatch: 26|1@1+ (1,0) [0|0] "" X
 SG_ BCFRONT_w093_OTPError: 28|1@1+ (1,0) [0|0] "" X
 SG_ BCFRONT_w102_RideHeightPWMError: 37|1@1+ (1,0) [0|0] "" X
 SG_ BCFRONT_w103_RideHeightPWMOpen: 38|1@1+ (1,0) [0|0] "" X
 SG_ BCFRONT_w104_RideHeightPWMShort: 39|1@1+ (1,0) [0|0] "" X
 SG_ BCFRONT_w105_ECUDebugMode: 40|1@1+ (1,0) [0|0] "" X
 SG_ BCFRONT_w106_HighCPULoad: 41|1@1+ (1,0) [0|0] "" X
 SG_ BCFRONT_w107_HighStackUsage: 42|1@1+ (1,0) [0|0] "" X
 SG_ BCFRONT_w111_LeftHeadlampFault: 46|1@1+ (1,0) [0|0] "" X
 SG_ BCFRONT_w112_RightHeadlampFault: 47|1@1+ (1,0) [0|0] "" X
 SG_ BCFRONT_w113_LeftFasciaFault: 48|1@1+ (1,0) [0|0] "" X
 SG_ BCFRONT_w114_RightFasciaFault: 49|1@1+ (1,0) [0|0] "" X
 SG_ BCFRONT_w115_FreescaleHSDFault: 50|1@1+ (1,0) [0|0] "" X

BO_ 3 BCLamps: 8 ETH
 SG_ BC_approachLightingActive: 52|2@1+ (1,0) [0|0] "" X
 SG_ BC_brakeLightLStatus: 14|2@1+ (1,0) [0|0] "" X
 SG_ BC_brakeLightRStatus: 34|2@1+ (1,0) [0|0] "" X
 SG_ BC_chmslStatus: 38|2@1+ (1,0) [0|0] "" X
 SG_ BC_courtesyLightingActive: 60|2@1+ (1,0) [0|0] "" X
 SG_ BC_dtrlLeftStatus: 44|2@1+ (1,0) [0|0] "" X
 SG_ BC_dtrlRightStatus: 42|2@1+ (1,0) [0|0] "" X
 SG_ BC_fogLightFLStatus: 28|2@1+ (1,0) [0|0] "" X
 SG_ BC_fogLightFRStatus: 18|2@1+ (1,0) [0|0] "" X
 SG_ BC_fogLightRLStatus: 36|2@1+ (1,0) [0|0] "" X
 SG_ BC_fogLightRRStatus: 54|2@1+ (1,0) [0|0] "" X
 SG_ BC_headLightLStatus: 12|2@1+ (1,0) [0|0] "" X
 SG_ BC_headLightRStatus: 22|2@1+ (1,0) [0|0] "" X
 SG_ BC_indicatorLOn: 24|2@1+ (1,0) [0|0] "" X
 SG_ BC_indicatorLStatus: 30|2@1+ (1,0) [0|0] "" X
 SG_ BC_indicatorROn: 26|2@1+ (1,0) [0|0] "" X
 SG_ BC_indicatorRStatus: 20|2@1+ (1,0) [0|0] "" X
 SG_ BC_licencePlateIllumStatus: 40|2@1+ (1,0) [0|0] "" X
 SG_ BC_lowBeamsOnlyForDRL: 50|1@1+ (1,0) [0|0] "" X
 SG_ BC_masterLightStatus: 46|2@1+ (1,0) [0|0] "" X
 SG_ BC_parkingLightLStatus: 56|2@1+ (1,0) [0|0] "" X
 SG_ BC_parkingLightRStatus: 58|2@1+ (1,0) [0|0] "" X
 SG_ BC_repeaterLeftOn: 32|2@1+ (1,0) [0|0] "" X
 SG_ BC_repeaterRightOn: 8|2@1+ (1,0) [0|0] "" X
 SG_ BC_reverseLightStatus: 48|2@1+ (1,0) [0|0] "" X
 SG_ BC_seeYouHomeLighting: 62|2@1+ (1,0) [0|0] "" X
 SG_ BC_sideLightLStatus: 16|2@1+ (1,0) [0|0] "" X
 SG_ BC_sideLightRStatus: 10|2@1+ (1,0) [0|0] "" X
 SG_ BC_sidemarkerLightLStatus: 4|2@1+ (1,0) [0|0] "" X
 SG_ BC_sidemarkerLightRStatus: 6|2@1+ (1,0) [0|0] "" X
 SG_ BC_tailLightLStatus: 0|2@1+ (1,0) [0|0] "" X
 SG_ BC_tailLightRStatus: 2|2@1+ (1,0) [0|0] "" X

BO_ 532 BCOther: 7 ETH
 SG_ BC_bcStatus: 44|4@1+ (1,0) [0|0] "" X
 SG_ BC_brakeFluidLevel: 34|2@1+ (1,0) [0|0] "" X
 SG_ BC_brakePressed: 39|1@1+ (1,0) [0|0] "" X
 SG_ BC_curveLeft1Status: 17|2@1+ (1,0) [0|0] "" X
 SG_ BC_curveLeft2Status: 19|2@1+ (1,0) [0|0] "" X
 SG_ BC_curveLeft3Status: 21|2@1+ (1,0) [0|0] "" X
 SG_ BC_curveRight1Status: 24|2@1+ (1,0) [0|0] "" X
 SG_ BC_curveRight2Status: 26|2@1+ (1,0) [0|0] "" X
 SG_ BC_curveRight3Status: 28|2@1+ (1,0) [0|0] "" X
 SG_ BC_dtcPresent: 16|1@1+ (1,0) [0|0] "" X
 SG_ BC_flashMainSwitch: 2|3@1+ (1,0) [0|0] "" X
 SG_ BC_ftSecondaryLatchStatus: 6|2@1+ (1,0) [0|0] "" X
 SG_ BC_harnessType: 32|2@1+ (1,0) [0|0] "" X
 SG_ BC_headlightLevelerStatus: 12|3@1+ (1,0) [0|0] "" X
 SG_ BC_heaterStatus: 5|1@1+ (1,0) [0|0] "" X
 SG_ BC_highBeamLStatus: 8|2@1+ (1,0) [0|0] "" X
 SG_ BC_highBeamRStatus: 10|2@1+ (1,0) [0|0] "" X
 SG_ BC_seeYouHomeTimer: 36|3@1+ (1,0) [0|0] "seconds" X
 SG_ BC_signatureLeftStatus: 30|2@1+ (1,0) [0|0] "" X
 SG_ BC_signatureRightStatus: 42|2@1+ (1,0) [0|0] "" X
 SG_ BC_vBattery: 48|8@1+ (0.1,0) [0|0] "Volts" X
 SG_ BC_washerFluidLevel: 40|2@1+ (1,0) [0|0] "" X

BO_ 1303 BCRDM_info: 8 ETH
 SG_ BCRDM_infoIndex M: 0|8@1+ (1,0) [0|0] "" X
 SG_ BCRDM_infoBuildType m10: 8|8@1+ (1,0) [0|0] "" X
 SG_ BCRDM_infoBuildConfigID m10: 16|16@1+ (1,0) [0|0] "" X
 SG_ BCRDM_infoHardwareID m10: 32|16@1+ (1,0) [0|0] "" X
 SG_ BCRDM_infoComponentID m10: 48|16@1+ (1,0) [0|0] "" X
 SG_ BCRDM_infoPcbaID m11: 16|8@1+ (1,0) [0|0] "" X
 SG_ BCRDM_infoAssemblyID m11: 24|8@1+ (1,0) [0|0] "INTEGRAL" X
 SG_ BCRDM_infoUsageID m11: 32|16@1+ (1,0) [0|0] "" X
 SG_ BCRDM_infoSubUsageID m11: 48|16@1+ (1,0) [0|0] "" X
 SG_ BCRDM_infoApplicationCRC m13: 32|32@1+ (1,0) [0|0] "" X
 SG_ BCRDM_infoBootSvnRev m14: 8|24@1+ (1,0) [0|0] "" X
 SG_ BCRDM_infoAppGitHashBytes m17: 10|54@1+ (4,0) [0|0] "" X
 SG_ BCRDM_infoBootGitHashBytes m18: 10|54@1+ (4,0) [0|0] "" X
 SG_ BCRDM_infoPlatformType m19: 8|8@1+ (1,0) [0|0] "" X
 SG_ BCRDM_infoBootUdsProtoVersion m20: 8|8@1+ (1,0) [0|0] "" X
 SG_ BCRDM_infoBootloaderCRC m20: 32|32@1+ (1,0) [0|0] "" X

BO_ 518 BCRDM_status: 8 ETH
 SG_ BCRDM_SBCTemperature: 24|8@1- (1,0) [0|0] "C" X
 SG_ BCRDM_ambientLightingStatus: 5|2@1+ (1,0) [0|0] "" X
 SG_ BCRDM_backlightStatus: 8|2@1+ (1,0) [0|0] "" X
 SG_ BCRDM_crashStatus: 40|2@1+ (1,0) [0|0] "" X
 SG_ BCRDM_doorIsMoving: 7|1@1+ (1,0) [0|0] "" X
 SG_ BCRDM_doorRequest: 48|2@1+ (1,0) [0|0] "" X
 SG_ BCRDM_exteriorReleaseStatus: 3|2@1+ (1,0) [0|0] "" X
 SG_ BCRDM_latchLowerStatus: 42|4@1+ (1,0) [0|0] "" X
 SG_ BCRDM_lockStatusConfirmation: 46|2@1+ (1,0) [0|0] "" X
 SG_ BCRDM_puddleLampStatus: 10|2@1+ (1,0) [0|0] "" X
 SG_ BCRDM_shutFaceSwitchStatus: 50|2@1+ (1,0) [0|0] "" X
 SG_ BCRDM_vehicle12V: 32|8@1+ (0.1,0) [0|0] "V" X
 SG_ BCRDM_windowStatus: 0|3@1+ (1,0) [0|0] "" X

BO_ 1718 BCRDM_udsResponse: 8 ETH
 SG_ BCRDM_udsResponseData_H: 0|32@0+ (1,0) [0|0] "" X
 SG_ BCRDM_udsResponseData_L: 32|32@0+ (1,0) [0|0] "" X

BO_ 974 BCRDM_warningMatrix1: 8 ETH
 SG_ BCRDM_w001_WatchdogReset: 0|1@1+ (1,0) [0|0] "" X
 SG_ BCRDM_w002_PowerLossReset: 1|1@1+ (1,0) [0|0] "" X
 SG_ BCRDM_w003_SWAssertion: 2|1@1+ (1,0) [0|0] "" X
 SG_ BCRDM_w004_CANMIA: 3|1@1+ (1,0) [0|0] "" X
 SG_ BCRDM_w005_CANHighError: 4|1@1+ (1,0) [0|0] "" X
 SG_ BCRDM_w006_CANLowError: 5|1@1+ (1,0) [0|0] "" X
 SG_ BCRDM_w007_LINTimeout: 6|1@1+ (1,0) [0|0] "" X
 SG_ BCRDM_w008_LIN2Error: 7|1@1+ (1,0) [0|0] "" X
 SG_ BCRDM_w009_LIN3Error: 8|1@1+ (1,0) [0|0] "" X
 SG_ BCRDM_w010_ExtSupplyVoltError: 9|1@1+ (1,0) [0|0] "" X
 SG_ BCRDM_w011_ECUSupplyVoltError: 10|1@1+ (1,0) [0|0] "" X
 SG_ BCRDM_w012_CPUReset: 11|1@1+ (1,0) [0|0] "" X
 SG_ BCRDM_w013_Shared13: 12|1@1+ (1,0) [0|0] "" X
 SG_ BCRDM_w014_BridgeFault: 13|1@1+ (1,0) [0|0] "" X
 SG_ BCRDM_w015_NVMMAlert: 14|1@1+ (1,0) [0|0] "" X
 SG_ BCRDM_w016_MessageTimingError: 15|1@1+ (1,0) [0|0] "" X
 SG_ BCRDM_w017_AwakeForTooLong: 16|1@1+ (1,0) [0|0] "" X
 SG_ BCRDM_w018_ADCError: 17|1@1+ (1,0) [0|0] "" X
 SG_ BCRDM_w019_I2CError: 18|1@1+ (1,0) [0|0] "" X
 SG_ BCRDM_w020_PWMError: 19|1@1+ (1,0) [0|0] "" X
 SG_ BCRDM_w021_TaskSchedulerError: 20|1@1+ (1,0) [0|0] "" X
 SG_ BCRDM_w022_TaskInitError: 21|1@1+ (1,0) [0|0] "" X
 SG_ BCRDM_w023_SleepError: 22|1@1+ (1,0) [0|0] "" X
 SG_ BCRDM_w024_WakeError: 23|1@1+ (1,0) [0|0] "" X
 SG_ BCRDM_w025_CrashEvent: 24|1@1+ (1,0) [0|0] "" X
 SG_ BCRDM_w026_FlashMemoryError: 25|1@1+ (1,0) [0|0] "" X
 SG_ BCRDM_w027_NVRAMCorruption: 26|1@1+ (1,0) [0|0] "" X
 SG_ BCRDM_w028_NVRAMNotResponding: 27|1@1+ (1,0) [0|0] "" X
 SG_ BCRDM_w029_NVRAMUninitialized: 28|1@1+ (1,0) [0|0] "" X
 SG_ BCRDM_w030_WrongUpperLatchState: 29|1@1+ (1,0) [0|0] "" X
 SG_ BCRDM_w031_WindowRegulator: 30|1@1+ (1,0) [0|0] "" X
 SG_ BCRDM_w032_ObstacleDetected: 31|1@1+ (1,0) [0|0] "" X
 SG_ BCRDM_w033_PinchDetected: 32|1@1+ (1,0) [0|0] "" X
 SG_ BCRDM_w035_FalconExternalSwitch: 34|1@1+ (1,0) [0|0] "" X
 SG_ BCRDM_w036_ProactiveSensors: 35|1@1+ (1,0) [0|0] "" X
 SG_ BCRDM_w037_ReactiveSensors: 36|1@1+ (1,0) [0|0] "" X
 SG_ BCRDM_w038_LatchUpperFront: 37|1@1+ (1,0) [0|0] "" X
 SG_ BCRDM_w039_LatchUpperRear: 38|1@1+ (1,0) [0|0] "" X
 SG_ BCRDM_w040_FalconShutfaceSwitch: 39|1@1+ (1,0) [0|0] "" X
 SG_ BCRDM_w041_LockedDoorOpened: 40|1@1+ (1,0) [0|0] "" X
 SG_ BCRDM_w042_LockedWindowOpened: 41|1@1+ (1,0) [0|0] "" X
 SG_ BCRDM_w043_LatchReleaseFailure: 42|1@1+ (1,0) [0|0] "" X
 SG_ BCRDM_w044_WindowCommError: 43|1@1+ (1,0) [0|0] "" X
 SG_ BCRDM_w045_PuddleLamp: 44|1@1+ (1,0) [0|0] "" X
 SG_ BCRDM_w046_WindowSwitchLED: 45|1@1+ (1,0) [0|0] "" X
 SG_ BCRDM_w047_AmbientIllumination: 46|1@1+ (1,0) [0|0] "" X
 SG_ BCRDM_w048_ShutfaceSwitchLED: 47|1@1+ (1,0) [0|0] "" X
 SG_ BCRDM_w049_ReflectorLamp: 48|1@1+ (1,0) [0|0] "" X
 SG_ BCRDM_w050_DrvSideButtonStuck: 49|1@1+ (1,0) [0|0] "" X
 SG_ BCRDM_w051_PassSideButtonStuck: 50|1@1+ (1,0) [0|0] "" X
 SG_ BCRDM_w052_DoorConfigError: 51|1@1+ (1,0) [0|0] "" X

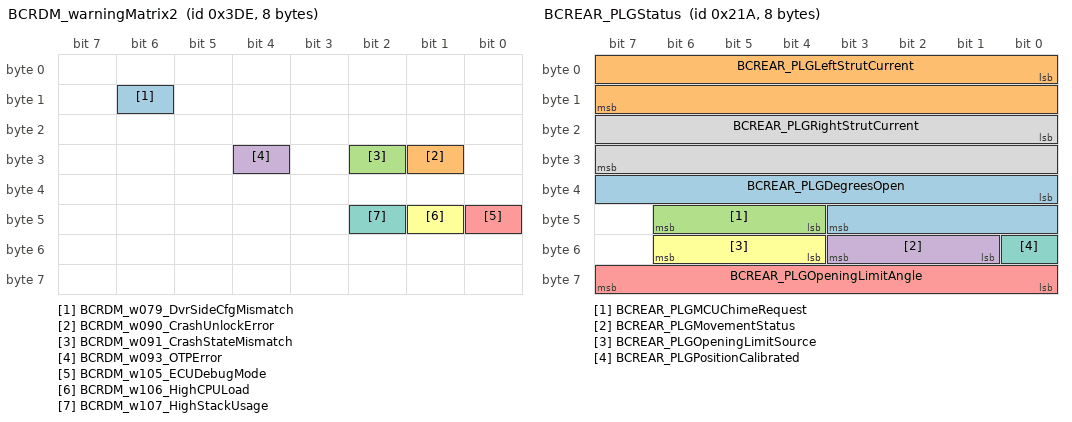
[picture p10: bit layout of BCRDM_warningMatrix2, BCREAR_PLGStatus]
BO_ 990 BCRDM_warningMatrix2: 8 ETH
 SG_ BCRDM_w079_DvrSideCfgMismatch: 14|1@1+ (1,0) [0|0] "" X
 SG_ BCRDM_w090_CrashUnlockError: 25|1@1+ (1,0) [0|0] "" X
 SG_ BCRDM_w091_CrashStateMismatch: 26|1@1+ (1,0) [0|0] "" X
 SG_ BCRDM_w093_OTPError: 28|1@1+ (1,0) [0|0] "" X
 SG_ BCRDM_w105_ECUDebugMode: 40|1@1+ (1,0) [0|0] "" X
 SG_ BCRDM_w106_HighCPULoad: 41|1@1+ (1,0) [0|0] "" X
 SG_ BCRDM_w107_HighStackUsage: 42|1@1+ (1,0) [0|0] "" X

BO_ 538 BCREAR_PLGStatus: 8 ETH
 SG_ BCREAR_PLGDegreesOpen: 32|12@1- (0.1,0) [0|0] "deg" X
 SG_ BCREAR_PLGLeftStrutCurrent: 0|16@1- (0.00381476,0) [0|0] "A" X
 SG_ BCREAR_PLGMCUChimeRequest: 44|3@1+ (1,0) [0|0] "" X
 SG_ BCREAR_PLGMovementStatus: 49|3@1+ (1,0) [0|0] "" X
 SG_ BCREAR_PLGOpeningLimitAngle: 56|8@1- (1.5,0) [0|0] "deg" X
 SG_ BCREAR_PLGOpeningLimitSource: 52|3@1+ (1,0) [0|0] "" X
 SG_ BCREAR_PLGPositionCalibrated: 48|1@1+ (1,0) [0|0] "" X
 SG_ BCREAR_PLGRightStrutCurrent: 16|16@1- (0.00381476,0) [0|0] "A" X

BO_ 1299 BCREAR_info: 8 ETH
 SG_ BCREAR_infoIndex M: 0|8@1+ (1,0) [0|0] "" X
 SG_ BCREAR_infoBuildType m10: 8|8@1+ (1,0) [0|0] "" X
 SG_ BCREAR_infoBuildConfigID m10: 16|16@1+ (1,0) [0|0] "" X
 SG_ BCREAR_infoHardwareID m10: 32|16@1+ (1,0) [0|0] "" X
 SG_ BCREAR_infoComponentID m10: 48|16@1+ (1,0) [0|0] "" X
 SG_ BCREAR_infoPcbaID m11: 16|8@1+ (1,0) [0|0] "" X
 SG_ BCREAR_infoAssemblyID m11: 24|8@1+ (1,0) [0|0] "INTEGRAL" X
 SG_ BCREAR_infoUsageID m11: 32|16@1+ (1,0) [0|0] "" X
 SG_ BCREAR_infoSubUsageID m11: 48|16@1+ (1,0) [0|0] "" X
 SG_ BCREAR_infoApplicationCRC m13: 32|32@1+ (1,0) [0|0] "" X
 SG_ BCREAR_infoBootSvnRev m14: 8|24@1+ (1,0) [0|0] "" X
 SG_ BCREAR_infoAppGitHashBytes m17: 10|54@1+ (4,0) [0|0] "" X
 SG_ BCREAR_infoBootGitHashBytes m18: 10|54@1+ (4,0) [0|0] "" X
 SG_ BCREAR_infoPlatformType m19: 8|8@1+ (1,0) [0|0] "" X
 SG_ BCREAR_infoBootUdsProtoVersion m20: 8|8@1+ (1,0) [0|0] "" X
 SG_ BCREAR_infoBootloaderCRC m20: 32|32@1+ (1,0) [0|0] "" X

BO_ 562 BCREAR_lightStatus: 8 ETH
 SG_ BCREAR_approachLightingActive: 60|2@1+ (1,0) [0|0] "" X
 SG_ BCREAR_chmslLightStatus: 12|2@1+ (1,0) [0|0] "" X
 SG_ BCREAR_fogLightLeftStatus: 14|2@1+ (1,0) [0|0] "" X
 SG_ BCREAR_fogLightRightStatus: 16|2@1+ (1,0) [0|0] "" X
 SG_ BCREAR_indicatorLeftStatus: 24|2@1+ (1,0) [0|0] "" X
 SG_ BCREAR_indicatorRightStatus: 26|2@1+ (1,0) [0|0] "" X
 SG_ BCREAR_licenseLightStatus: 22|2@1+ (1,0) [0|0] "" X
 SG_ BCREAR_mapLightRow1LeftStatus: 28|2@1+ (1,0) [0|0] "" X
 SG_ BCREAR_mapLightRow1RightStatus: 30|2@1+ (1,0) [0|0] "" X
 SG_ BCREAR_mapLightRow2CenterStatus: 34|2@1+ (1,0) [0|0] "" X
 SG_ BCREAR_mapLightRow2LeftStatus: 32|2@1+ (1,0) [0|0] "" X
 SG_ BCREAR_mapLightRow2RightStatus: 36|2@1+ (1,0) [0|0] "" X
 SG_ BCREAR_mapLightRow3LeftStatus: 38|2@1+ (1,0) [0|0] "" X
 SG_ BCREAR_mapLightRow3RightStatus: 40|2@1+ (1,0) [0|0] "" X
 SG_ BCREAR_reverseLightLeftStatus: 18|2@1+ (1,0) [0|0] "" X
 SG_ BCREAR_reverseLightRightStatus: 20|2@1+ (1,0) [0|0] "" X
 SG_ BCREAR_seeYouHomeLightingActive: 58|2@1+ (1,0) [0|0] "" X
 SG_ BCREAR_stopLightLeftStatus: 2|2@1+ (1,0) [0|0] "" X
 SG_ BCREAR_stopLightRightStatus: 0|2@1+ (1,0) [0|0] "" X
 SG_ BCREAR_tailLightLeftStatus: 6|2@1+ (1,0) [0|0] "" X
 SG_ BCREAR_tailLightRightStatus: 4|2@1+ (1,0) [0|0] "" X
 SG_ BCREAR_trailerLightFog: 52|2@1+ (1,0) [0|0] "" X
 SG_ BCREAR_trailerLightParkLeft: 54|2@1+ (1,0) [0|0] "" X
 SG_ BCREAR_trailerLightParkRight: 56|2@1+ (1,0) [0|0] "" X
 SG_ BCREAR_trailerLightReverse: 50|2@1+ (1,0) [0|0] "" X
 SG_ BCREAR_trailerLightStopLeft: 42|2@1+ (1,0) [0|0] "" X
 SG_ BCREAR_trailerLightStopRight: 44|2@1+ (1,0) [0|0] "" X
 SG_ BCREAR_trailerLightTurnLeft: 46|2@1+ (1,0) [0|0] "" X
 SG_ BCREAR_trailerLightTurnRight: 48|2@1+ (1,0) [0|0] "" X
 SG_ BCREAR_trunkLightStatus: 10|2@1+ (1,0) [0|0] "" X
 SG_ BCREAR_trunkShutFaceBackLight: 8|2@1+ (1,0) [0|0] "" X

BO_ 511 BCREAR_status: 8 ETH
 SG_ BCREAR_PLGSimpleStatus: 57|4@1+ (1,0) [0|0] "" X
 SG_ BCREAR_SBCTemperature: 41|8@1- (1,0) [0|0] "C" X
 SG_ BCREAR_crashStatus: 18|2@1+ (1,0) [0|0] "" X
 SG_ BCREAR_lastRequestSource: 30|3@1+ (1,0) [0|0] "" X
 SG_ BCREAR_lockStatusConfirmation: 24|2@1+ (1,0) [0|0] "" X
 SG_ BCREAR_mvmntNotAllowedCondition: 61|3@1+ (1,0) [0|0] "" X
 SG_ BCREAR_plgLeftAndMidPinchStatus: 16|2@1+ (1,0) [0|0] "" X
 SG_ BCREAR_plgRightPinchStatus: 13|2@1+ (1,0) [0|0] "" X
 SG_ BCREAR_powerLiftgateStatus: 4|4@1+ (1,0) [0|0] "" X
 SG_ BCREAR_rearLeftRideHeight: 49|8@1+ (1,-100) [0|0] "mm" X
 SG_ BCREAR_spoilerStatus: 8|3@1+ (1,0) [0|0] "" X
 SG_ BCREAR_stoppingCondition: 26|4@1+ (1,0) [0|0] "" X
 SG_ BCREAR_trailerLightDetection: 11|2@1+ (1,0) [0|0] "" X
 SG_ BCREAR_trunkExtReleaseStatus: 20|2@1+ (1,0) [0|0] "" X
 SG_ BCREAR_trunkLatchStatus: 0|4@1+ (1,0) [0|0] "" X
 SG_ BCREAR_trunkShutFaceSwitchStatus: 22|2@1+ (1,0) [0|0] "" X
 SG_ BCREAR_vehicle12V: 33|8@1+ (0.1,0) [0|0] "V" X

BO_ 1714 BCREAR_udsResponse: 8 ETH
 SG_ BCREAR_udsResponseData_H: 0|32@0+ (1,0) [0|0] "" X
 SG_ BCREAR_udsResponseData_L: 32|32@0+ (1,0) [0|0] "" X

BO_ 870 BCREAR_warningMatrix1: 8 ETH
 SG_ BCREAR_w001_WatchdogReset: 0|1@1+ (1,0) [0|0] "" X
 SG_ BCREAR_w002_PowerLossReset: 1|1@1+ (1,0) [0|0] "" X
 SG_ BCREAR_w003_SWAssertion: 2|1@1+ (1,0) [0|0] "" X
 SG_ BCREAR_w004_CANMIA: 3|1@1+ (1,0) [0|0] "" X
 SG_ BCREAR_w005_CANHighError: 4|1@1+ (1,0) [0|0] "" X
 SG_ BCREAR_w006_CANLowError: 5|1@1+ (1,0) [0|0] "" X
 SG_ BCREAR_w007_LINTimeout: 6|1@1+ (1,0) [0|0] "" X
 SG_ BCREAR_w008_LIN2Error: 7|1@1+ (1,0) [0|0] "" X
 SG_ BCREAR_w009_LIN3Error: 8|1@1+ (1,0) [0|0] "" X
 SG_ BCREAR_w010_ExtSupplyVoltError: 9|1@1+ (1,0) [0|0] "" X
 SG_ BCREAR_w011_ECUSupplyVoltError: 10|1@1+ (1,0) [0|0] "" X
 SG_ BCREAR_w012_CPUReset: 11|1@1+ (1,0) [0|0] "" X
 SG_ BCREAR_w013_Shared13: 12|1@1+ (1,0) [0|0] "" X
 SG_ BCREAR_w014_BridgeFault: 13|1@1+ (1,0) [0|0] "" X
 SG_ BCREAR_w015_NVMMAlert: 14|1@1+ (1,0) [0|0] "" X
 SG_ BCREAR_w016_MessageTimingError: 15|1@1+ (1,0) [0|0] "" X
 SG_ BCREAR_w017_AwakeForTooLong: 16|1@1+ (1,0) [0|0] "" X
 SG_ BCREAR_w018_ADCError: 17|1@1+ (1,0) [0|0] "" X
 SG_ BCREAR_w019_I2CError: 18|1@1+ (1,0) [0|0] "" X
 SG_ BCREAR_w020_PWMError: 19|1@1+ (1,0) [0|0] "" X
 SG_ BCREAR_w021_TaskSchedulerError: 20|1@1+ (1,0) [0|0] "" X
 SG_ BCREAR_w022_TaskInitError: 21|1@1+ (1,0) [0|0] "" X
 SG_ BCREAR_w023_SleepError: 22|1@1+ (1,0) [0|0] "" X
 SG_ BCREAR_w024_WakeError: 23|1@1+ (1,0) [0|0] "" X
 SG_ BCREAR_w025_CrashEvent: 24|1@1+ (1,0) [0|0] "" X
 SG_ BCREAR_w026_FlashMemoryError: 25|1@1+ (1,0) [0|0] "" X
 SG_ BCREAR_w027_NVRAMCorruption: 26|1@1+ (1,0) [0|0] "" X
 SG_ BCREAR_w028_NVRAMNotResponding: 27|1@1+ (1,0) [0|0] "" X
 SG_ BCREAR_w029_NVRAMUninitialized: 28|1@1+ (1,0) [0|0] "" X
 SG_ BCREAR_w030_PumpFailure: 29|1@1+ (1,0) [0|0] "" X
 SG_ BCREAR_w031_SpoilerCalibFailed: 30|1@1+ (1,0) [0|0] "" X
 SG_ BCREAR_w032_FalconStateError: 31|1@1+ (1,0) [0|0] "" X
 SG_ BCREAR_w033_FalconThermalLimit: 32|1@1+ (1,0) [0|0] "" X
 SG_ BCREAR_w034_FalconPositionSensor: 33|1@1+ (1,0) [0|0] "" X
 SG_ BCREAR_w035_ExcessiveFalconDrift: 34|1@1+ (1,0) [0|0] "" X
 SG_ BCREAR_w036_CannotReachTargetPos: 35|1@1+ (1,0) [0|0] "" X
 SG_ BCREAR_w037_CannotPresentStriker: 36|1@1+ (1,0) [0|0] "" X
 SG_ BCREAR_w038_DoorReqCRCMismatch: 37|1@1+ (1,0) [0|0] "" X
 SG_ BCREAR_w039_ManualCloseRequested: 38|1@1+ (1,0) [0|0] "" X
 SG_ BCREAR_w040_OpenTimeTarget: 39|1@1+ (1,0) [0|0] "" X
 SG_ BCREAR_w041_CloseTimeTarget: 40|1@1+ (1,0) [0|0] "" X
 SG_ BCREAR_w042_OperatingWithLow12V: 41|1@1+ (1,0) [0|0] "" X
 SG_ BCREAR_w043_FalconIntSwitch: 42|1@1+ (1,0) [0|0] "" X
 SG_ BCREAR_w044_FalconOpenAtSpeed: 43|1@1+ (1,0) [0|0] "" X
 SG_ BCREAR_w045_TailLightLeftGate: 44|1@1+ (1,0) [0|0] "" X
 SG_ BCREAR_w046_TailLightLeftBody: 45|1@1+ (1,0) [0|0] "" X
 SG_ BCREAR_w047_StopLightLeftGate: 46|1@1+ (1,0) [0|0] "" X
 SG_ BCREAR_w048_StopLightLeftBody: 47|1@1+ (1,0) [0|0] "" X
 SG_ BCREAR_w049_ReverseLightLeft: 48|1@1+ (1,0) [0|0] "" X
 SG_ BCREAR_w050_FogLightLeft: 49|1@1+ (1,0) [0|0] "" X
 SG_ BCREAR_w051_TurnIndicatorLeft: 50|1@1+ (1,0) [0|0] "" X
 SG_ BCREAR_w052_SideMarkerLeft: 51|1@1+ (1,0) [0|0] "" X
 SG_ BCREAR_w053_TailLightRightGate: 52|1@1+ (1,0) [0|0] "" X
 SG_ BCREAR_w054_TailLightRightBody: 53|1@1+ (1,0) [0|0] "" X
 SG_ BCREAR_w055_StopLightRightGate: 54|1@1+ (1,0) [0|0] "" X
 SG_ BCREAR_w056_StopLightRightBody: 55|1@1+ (1,0) [0|0] "" X
 SG_ BCREAR_w057_ReverseLightRight: 56|1@1+ (1,0) [0|0] "" X
 SG_ BCREAR_w058_FogLightRight: 57|1@1+ (1,0) [0|0] "" X
 SG_ BCREAR_w059_TurnIndicatorRight: 58|1@1+ (1,0) [0|0] "" X
 SG_ BCREAR_w060_SideMarkerRight: 59|1@1+ (1,0) [0|0] "" X
 SG_ BCREAR_w061_CHMSLLight: 60|1@1+ (1,0) [0|0] "" X
 SG_ BCREAR_w062_LicenseLight: 61|1@1+ (1,0) [0|0] "" X
 SG_ BCREAR_w063_PLGError: 62|1@1+ (1,0) [0|0] "" X
 SG_ BCREAR_w064_PLGCalibration: 63|1@1+ (1,0) [0|0] "" X

BO_ 886 BCREAR_warningMatrix2: 8 ETH
 SG_ BCREAR_w065_PLGProgramStop: 0|1@1+ (1,0) [0|0] "" X
 SG_ BCREAR_w066_PLGThermalLimit: 1|1@1+ (1,0) [0|0] "" X
 SG_ BCREAR_w067_PLGPinchDetected: 2|1@1+ (1,0) [0|0] "" X
 SG_ BCREAR_w068_PLGObstacle: 3|1@1+ (1,0) [0|0] "" X
 SG_ BCREAR_w069_PLGShutfaceSwitch: 4|1@1+ (1,0) [0|0] "" X
 SG_ BCREAR_w070_PLGSwitchIllum: 5|1@1+ (1,0) [0|0] "" X
 SG_ BCREAR_w071_PLGExcessiveDrift: 6|1@1+ (1,0) [0|0] "" X
 SG_ BCREAR_w072_PLGOpenReqAtSpeed: 7|1@1+ (1,0) [0|0] "" X
 SG_ BCREAR_w073_PLGSupply: 8|1@1+ (1,0) [0|0] "" X
 SG_ BCREAR_w074_LiftgateLatch: 9|1@1+ (1,0) [0|0] "" X
 SG_ BCREAR_w075_LiftgateExtSwitch: 10|1@1+ (1,0) [0|0] "" X
 SG_ BCREAR_w076_AmbientLighting: 11|1@1+ (1,0) [0|0] "" X
 SG_ BCREAR_w077_AmbLightingCommError: 12|1@1+ (1,0) [0|0] "" X
 SG_ BCREAR_w079_DvrSideCfgMismatch: 14|1@1+ (1,0) [0|0] "" X
 SG_ BCREAR_w080_Falcon5VRail: 15|1@1+ (1,0) [0|0] "" X
 SG_ BCREAR_w081_FalconPump12V: 16|1@1+ (1,0) [0|0] "" X
 SG_ BCREAR_w082_BPillarButtonStuck: 17|1@1+ (1,0) [0|0] "" X
 SG_ BCREAR_w083_FalconPinchActivity: 18|1@1+ (1,0) [0|0] "" X
 SG_ BCREAR_w085_RideHeightPWMError: 20|1@1+ (1,0) [0|0] "" X
 SG_ BCREAR_w086_RideHeightPWMOpen: 21|1@1+ (1,0) [0|0] "" X
 SG_ BCREAR_w087_RideHeightPWMShort: 22|1@1+ (1,0) [0|0] "" X
 SG_ BCREAR_w088_UnexpectedStop: 23|1@1+ (1,0) [0|0] "" X
 SG_ BCREAR_w089_PLGReactiveCurrent: 24|1@1+ (1,0) [0|0] "" X
 SG_ BCREAR_w090_CrashUnlockError: 25|1@1+ (1,0) [0|0] "" X
 SG_ BCREAR_w091_CrashStateMismatch: 26|1@1+ (1,0) [0|0] "" X
 SG_ BCREAR_w092_infoPLGDebug: 27|1@1+ (1,0) [0|0] "" X
 SG_ BCREAR_w093_OTPError: 28|1@1+ (1,0) [0|0] "" X
 SG_ BCREAR_w094_PLGReleaseOvertemp: 29|1@1+ (1,0) [0|0] "" X
 SG_ BCREAR_w095_SpoilerOvercurrent: 30|1@1+ (1,0) [0|0] "" X
 SG_ BCREAR_w096_SpoilerUndercurrent: 31|1@1+ (1,0) [0|0] "" X
 SG_ BCREAR_w097_SpoilerTimeout: 32|1@1+ (1,0) [0|0] "" X
 SG_ BCREAR_w098_TrailerParkFault: 33|1@1+ (1,0) [0|0] "" X
 SG_ BCREAR_w099_TrailerLeftFault: 34|1@1+ (1,0) [0|0] "" X
 SG_ BCREAR_w100_TrailerRightFault: 35|1@1+ (1,0) [0|0] "" X
 SG_ BCREAR_w101_TrailerReverseFault: 36|1@1+ (1,0) [0|0] "" X
 SG_ BCREAR_w102_TrailerFogFault: 37|1@1+ (1,0) [0|0] "" X
 SG_ BCREAR_w103_TrailerBrakeFault: 38|1@1+ (1,0) [0|0] "" X
 SG_ BCREAR_w104_spoilerUnxpctedStop: 39|1@1+ (1,0) [0|0] "" X
 SG_ BCREAR_w105_ECUDebugMode: 40|1@1+ (1,0) [0|0] "" X
 SG_ BCREAR_w106_HighCPULoad: 41|1@1+ (1,0) [0|0] "" X
 SG_ BCREAR_w107_HighStackUsage: 42|1@1+ (1,0) [0|0] "" X
 SG_ BCREAR_w108_spoilerAutoCalFail: 43|1@1+ (1,0) [0|0] "" X
 SG_ BCREAR_w115_FreescaleHSDFault: 50|1@1+ (1,0) [0|0] "" X

BO_ 1304 BCRPM_info: 8 ETH
 SG_ BCRPM_infoIndex M: 0|8@1+ (1,0) [0|0] "" X
 SG_ BCRPM_infoBuildType m10: 8|8@1+ (1,0) [0|0] "" X
 SG_ BCRPM_infoBuildConfigID m10: 16|16@1+ (1,0) [0|0] "" X
 SG_ BCRPM_infoHardwareID m10: 32|16@1+ (1,0) [0|0] "" X
 SG_ BCRPM_infoComponentID m10: 48|16@1+ (1,0) [0|0] "" X
 SG_ BCRPM_infoPcbaID m11: 16|8@1+ (1,0) [0|0] "" X
 SG_ BCRPM_infoAssemblyID m11: 24|8@1+ (1,0) [0|0] "INTEGRAL" X
 SG_ BCRPM_infoUsageID m11: 32|16@1+ (1,0) [0|0] "" X
 SG_ BCRPM_infoSubUsageID m11: 48|16@1+ (1,0) [0|0] "" X
 SG_ BCRPM_infoApplicationCRC m13: 32|32@1+ (1,0) [0|0] "" X
 SG_ BCRPM_infoBootSvnRev m14: 8|24@1+ (1,0) [0|0] "" X
 SG_ BCRPM_infoAppGitHashBytes m17: 10|54@1+ (4,0) [0|0] "" X
 SG_ BCRPM_infoBootGitHashBytes m18: 10|54@1+ (4,0) [0|0] "" X
 SG_ BCRPM_infoPlatformType m19: 8|8@1+ (1,0) [0|0] "" X
 SG_ BCRPM_infoBootUdsProtoVersion m20: 8|8@1+ (1,0) [0|0] "" X
 SG_ BCRPM_infoBootloaderCRC m20: 32|32@1+ (1,0) [0|0] "" X

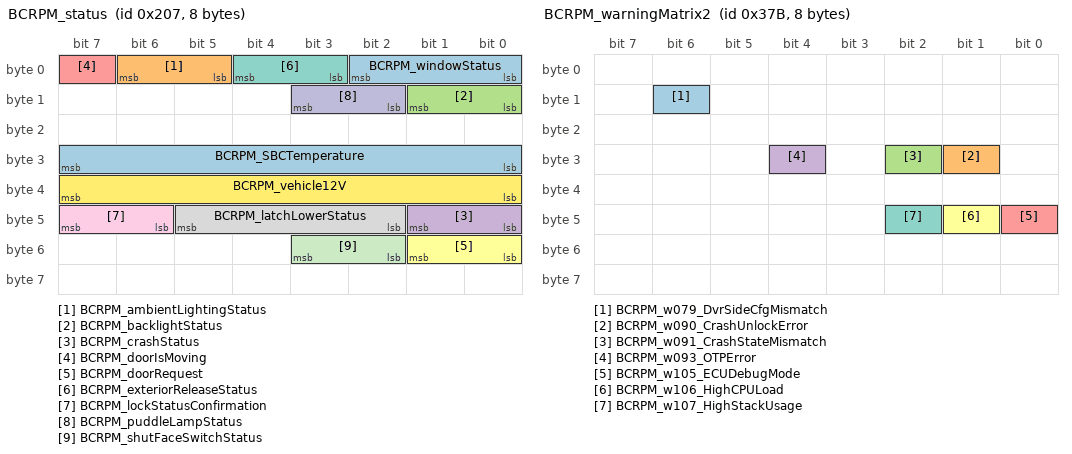
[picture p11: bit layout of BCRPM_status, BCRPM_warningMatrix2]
BO_ 519 BCRPM_status: 8 ETH
 SG_ BCRPM_SBCTemperature: 24|8@1- (1,0) [0|0] "C" X
 SG_ BCRPM_ambientLightingStatus: 5|2@1+ (1,0) [0|0] "" X
 SG_ BCRPM_backlightStatus: 8|2@1+ (1,0) [0|0] "" X
 SG_ BCRPM_crashStatus: 40|2@1+ (1,0) [0|0] "" X
 SG_ BCRPM_doorIsMoving: 7|1@1+ (1,0) [0|0] "" X
 SG_ BCRPM_doorRequest: 48|2@1+ (1,0) [0|0] "" X
 SG_ BCRPM_exteriorReleaseStatus: 3|2@1+ (1,0) [0|0] "" X
 SG_ BCRPM_latchLowerStatus: 42|4@1+ (1,0) [0|0] "" X
 SG_ BCRPM_lockStatusConfirmation: 46|2@1+ (1,0) [0|0] "" X
 SG_ BCRPM_puddleLampStatus: 10|2@1+ (1,0) [0|0] "" X
 SG_ BCRPM_shutFaceSwitchStatus: 50|2@1+ (1,0) [0|0] "" X
 SG_ BCRPM_vehicle12V: 32|8@1+ (0.1,0) [0|0] "V" X
 SG_ BCRPM_windowStatus: 0|3@1+ (1,0) [0|0] "" X

BO_ 1719 BCRPM_udsResponse: 8 ETH
 SG_ BCRPM_udsResponseData_H: 0|32@0+ (1,0) [0|0] "" X
 SG_ BCRPM_udsResponseData_L: 32|32@0+ (1,0) [0|0] "" X

BO_ 875 BCRPM_warningMatrix1: 8 ETH
 SG_ BCRPM_w001_WatchdogReset: 0|1@1+ (1,0) [0|0] "" X
 SG_ BCRPM_w002_PowerLossReset: 1|1@1+ (1,0) [0|0] "" X
 SG_ BCRPM_w003_SWAssertion: 2|1@1+ (1,0) [0|0] "" X
 SG_ BCRPM_w004_CANMIA: 3|1@1+ (1,0) [0|0] "" X
 SG_ BCRPM_w005_CANHighError: 4|1@1+ (1,0) [0|0] "" X
 SG_ BCRPM_w006_CANLowError: 5|1@1+ (1,0) [0|0] "" X
 SG_ BCRPM_w007_LINTimeout: 6|1@1+ (1,0) [0|0] "" X
 SG_ BCRPM_w008_LIN2Error: 7|1@1+ (1,0) [0|0] "" X
 SG_ BCRPM_w009_LIN3Error: 8|1@1+ (1,0) [0|0] "" X
 SG_ BCRPM_w010_ExtSupplyVoltError: 9|1@1+ (1,0) [0|0] "" X
 SG_ BCRPM_w011_ECUSupplyVoltError: 10|1@1+ (1,0) [0|0] "" X
 SG_ BCRPM_w012_CPUReset: 11|1@1+ (1,0) [0|0] "" X
 SG_ BCRPM_w013_Shared13: 12|1@1+ (1,0) [0|0] "" X
 SG_ BCRPM_w014_BridgeFault: 13|1@1+ (1,0) [0|0] "" X
 SG_ BCRPM_w015_NVMMAlert: 14|1@1+ (1,0) [0|0] "" X
 SG_ BCRPM_w016_MessageTimingError: 15|1@1+ (1,0) [0|0] "" X
 SG_ BCRPM_w017_AwakeForTooLong: 16|1@1+ (1,0) [0|0] "" X
 SG_ BCRPM_w018_ADCError: 17|1@1+ (1,0) [0|0] "" X
 SG_ BCRPM_w019_I2CError: 18|1@1+ (1,0) [0|0] "" X
 SG_ BCRPM_w020_PWMError: 19|1@1+ (1,0) [0|0] "" X
 SG_ BCRPM_w021_TaskSchedulerError: 20|1@1+ (1,0) [0|0] "" X
 SG_ BCRPM_w022_TaskInitError: 21|1@1+ (1,0) [0|0] "" X
 SG_ BCRPM_w023_SleepError: 22|1@1+ (1,0) [0|0] "" X
 SG_ BCRPM_w024_WakeError: 23|1@1+ (1,0) [0|0] "" X
 SG_ BCRPM_w025_CrashEvent: 24|1@1+ (1,0) [0|0] "" X
 SG_ BCRPM_w026_FlashMemoryError: 25|1@1+ (1,0) [0|0] "" X
 SG_ BCRPM_w027_NVRAMCorruption: 26|1@1+ (1,0) [0|0] "" X
 SG_ BCRPM_w028_NVRAMNotResponding: 27|1@1+ (1,0) [0|0] "" X
 SG_ BCRPM_w029_NVRAMUninitialized: 28|1@1+ (1,0) [0|0] "" X
 SG_ BCRPM_w030_WrongUpperLatchState: 29|1@1+ (1,0) [0|0] "" X
 SG_ BCRPM_w031_WindowRegulator: 30|1@1+ (1,0) [0|0] "" X
 SG_ BCRPM_w032_ObstacleDetected: 31|1@1+ (1,0) [0|0] "" X
 SG_ BCRPM_w033_PinchDetected: 32|1@1+ (1,0) [0|0] "" X
 SG_ BCRPM_w035_FalconExternalSwitch: 34|1@1+ (1,0) [0|0] "" X
 SG_ BCRPM_w036_ProactiveSensors: 35|1@1+ (1,0) [0|0] "" X
 SG_ BCRPM_w037_ReactiveSensors: 36|1@1+ (1,0) [0|0] "" X
 SG_ BCRPM_w038_LatchUpperFront: 37|1@1+ (1,0) [0|0] "" X
 SG_ BCRPM_w039_LatchUpperRear: 38|1@1+ (1,0) [0|0] "" X
 SG_ BCRPM_w040_FalconShutfaceSwitch: 39|1@1+ (1,0) [0|0] "" X
 SG_ BCRPM_w041_LockedDoorOpened: 40|1@1+ (1,0) [0|0] "" X
 SG_ BCRPM_w042_LockedWindowOpened: 41|1@1+ (1,0) [0|0] "" X
 SG_ BCRPM_w043_LatchReleaseFailure: 42|1@1+ (1,0) [0|0] "" X
 SG_ BCRPM_w044_WindowCommError: 43|1@1+ (1,0) [0|0] "" X
 SG_ BCRPM_w045_PuddleLamp: 44|1@1+ (1,0) [0|0] "" X
 SG_ BCRPM_w046_WindowSwitchLED: 45|1@1+ (1,0) [0|0] "" X
 SG_ BCRPM_w047_AmbientIllumination: 46|1@1+ (1,0) [0|0] "" X
 SG_ BCRPM_w048_ShutfaceSwitchLED: 47|1@1+ (1,0) [0|0] "" X
 SG_ BCRPM_w049_ReflectorLamp: 48|1@1+ (1,0) [0|0] "" X
 SG_ BCRPM_w050_DrvSideButtonStuck: 49|1@1+ (1,0) [0|0] "" X
 SG_ BCRPM_w051_PassSideButtonStuck: 50|1@1+ (1,0) [0|0] "" X
 SG_ BCRPM_w052_DoorConfigError: 51|1@1+ (1,0) [0|0] "" X

BO_ 891 BCRPM_warningMatrix2: 8 ETH
 SG_ BCRPM_w079_DvrSideCfgMismatch: 14|1@1+ (1,0) [0|0] "" X
 SG_ BCRPM_w090_CrashUnlockError: 25|1@1+ (1,0) [0|0] "" X
 SG_ BCRPM_w091_CrashStateMismatch: 26|1@1+ (1,0) [0|0] "" X
 SG_ BCRPM_w093_OTPError: 28|1@1+ (1,0) [0|0] "" X
 SG_ BCRPM_w105_ECUDebugMode: 40|1@1+ (1,0) [0|0] "" X
 SG_ BCRPM_w106_HighCPULoad: 41|1@1+ (1,0) [0|0] "" X
 SG_ BCRPM_w107_HighStackUsage: 42|1@1+ (1,0) [0|0] "" X

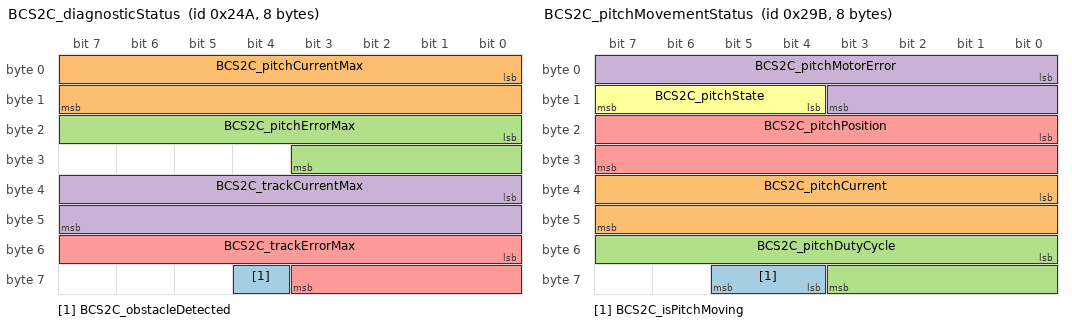
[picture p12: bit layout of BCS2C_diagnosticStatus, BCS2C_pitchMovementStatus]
BO_ 586 BCS2C_diagnosticStatus: 8 ETH
 SG_ BCS2C_obstacleDetected: 60|1@1+ (1,0) [0|0] "" X
 SG_ BCS2C_pitchCurrentMax: 0|16@1- (0.0030518,0) [0|0] "A" X
 SG_ BCS2C_pitchErrorMax: 16|12@1- (0.04884,0) [0|0] "%" X
 SG_ BCS2C_trackCurrentMax: 32|16@1- (0.0030518,0) [0|0] "A" X
 SG_ BCS2C_trackErrorMax: 48|12@1- (0.04884,0) [0|0] "%" X

BO_ 1312 BCS2C_info: 8 ETH
 SG_ BCS2C_infoIndex M: 0|8@1+ (1,0) [0|0] "" X
 SG_ BCS2C_infoBuildType m10: 8|8@1+ (1,0) [0|0] "" X
 SG_ BCS2C_infoBuildConfigID m10: 16|16@1+ (1,0) [0|0] "" X
 SG_ BCS2C_infoHardwareID m10: 32|16@1+ (1,0) [0|0] "" X
 SG_ BCS2C_infoComponentID m10: 48|16@1+ (1,0) [0|0] "" X
 SG_ BCS2C_infoPcbaID m11: 16|8@1+ (1,0) [0|0] "" X
 SG_ BCS2C_infoAssemblyID m11: 24|8@1+ (1,0) [0|0] "INTEGRAL" X
 SG_ BCS2C_infoUsageID m11: 32|16@1+ (1,0) [0|0] "" X
 SG_ BCS2C_infoSubUsageID m11: 48|16@1+ (1,0) [0|0] "" X
 SG_ BCS2C_infoApplicationCRC m13: 32|32@1+ (1,0) [0|0] "" X
 SG_ BCS2C_infoBootSvnRev m14: 8|24@1+ (1,0) [0|0] "" X
 SG_ BCS2C_infoAppGitHashBytes m17: 10|54@1+ (4,0) [0|0] "" X
 SG_ BCS2C_infoBootGitHashBytes m18: 10|54@1+ (4,0) [0|0] "" X
 SG_ BCS2C_infoPlatformType m19: 8|8@1+ (1,0) [0|0] "" X
 SG_ BCS2C_infoBootUdsProtoVersion m20: 8|8@1+ (1,0) [0|0] "" X
 SG_ BCS2C_infoBootloaderCRC m20: 32|32@1+ (1,0) [0|0] "" X

BO_ 667 BCS2C_pitchMovementStatus: 8 ETH
 SG_ BCS2C_isPitchMoving: 60|2@1+ (1,0) [0|0] "" X
 SG_ BCS2C_pitchCurrent: 32|16@1- (0.0030518,0) [0|0] "A" X
 SG_ BCS2C_pitchDutyCycle: 48|12@1- (0.04884,0) [0|0] "%" X
 SG_ BCS2C_pitchMotorError: 0|12@1- (0.04884,0) [0|0] "%" X
 SG_ BCS2C_pitchPosition: 16|16@1- (1,0) [0|0] "INTEGRAL" X
 SG_ BCS2C_pitchState: 12|4@1+ (1,0) [0|0] "" X

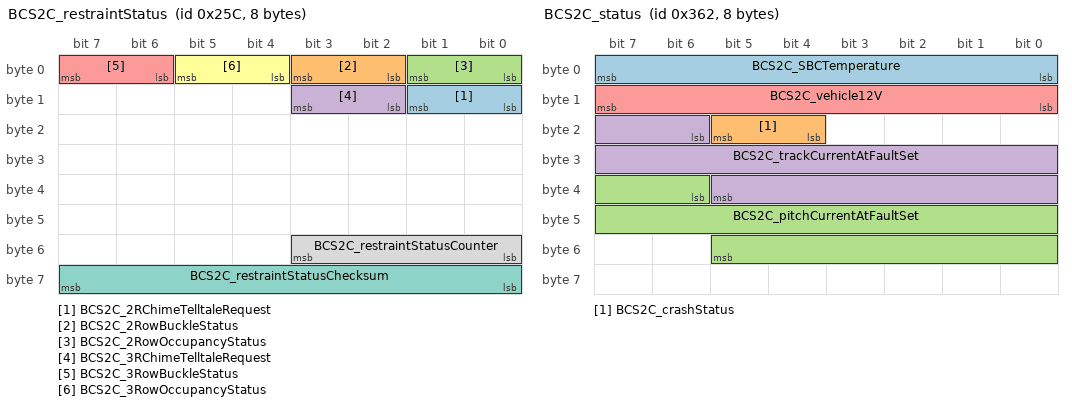
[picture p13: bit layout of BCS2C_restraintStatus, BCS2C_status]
BO_ 604 BCS2C_restraintStatus: 8 ETH
 SG_ BCS2C_2RChimeTelltaleRequest: 8|2@1+ (1,0) [0|0] "" X
 SG_ BCS2C_2RowBuckleStatus: 2|2@1+ (1,0) [0|0] "" X
 SG_ BCS2C_2RowOccupancyStatus: 0|2@1+ (1,0) [0|0] "" X
 SG_ BCS2C_3RChimeTelltaleRequest: 10|2@1+ (1,0) [0|0] "" X
 SG_ BCS2C_3RowBuckleStatus: 6|2@1+ (1,0) [0|0] "" X
 SG_ BCS2C_3RowOccupancyStatus: 4|2@1+ (1,0) [0|0] "" X
 SG_ BCS2C_restraintStatusChecksum: 56|8@1+ (1,0) [0|0] "" X
 SG_ BCS2C_restraintStatusCounter: 48|4@1+ (1,0) [0|0] "" X

BO_ 866 BCS2C_status: 8 ETH
 SG_ BCS2C_SBCTemperature: 0|8@1- (1,0) [0|0] "C" X
 SG_ BCS2C_crashStatus: 20|2@1+ (1,0) [0|0] "" X
 SG_ BCS2C_pitchCurrentAtFaultSet: 38|16@1- (0.0030518,0) [0|0] "A" X
 SG_ BCS2C_trackCurrentAtFaultSet: 22|16@1- (0.0030518,0) [0|0] "A" X
 SG_ BCS2C_vehicle12V: 8|8@1+ (0.1,0) [0|0] "V" X

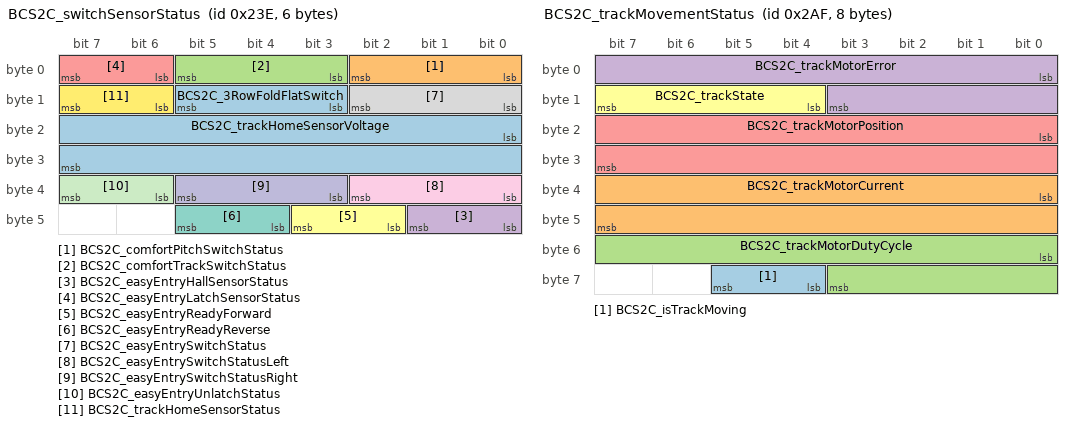
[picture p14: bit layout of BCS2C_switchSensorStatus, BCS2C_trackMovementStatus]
BO_ 574 BCS2C_switchSensorStatus: 6 ETH
 SG_ BCS2C_3RowFoldFlatSwitch: 11|3@1+ (1,0) [0|0] "" X
 SG_ BCS2C_comfortPitchSwitchStatus: 0|3@1+ (1,0) [0|0] "" X
 SG_ BCS2C_comfortTrackSwitchStatus: 3|3@1+ (1,0) [0|0] "" X
 SG_ BCS2C_easyEntryHallSensorStatus: 40|2@1+ (1,0) [0|0] "" X
 SG_ BCS2C_easyEntryLatchSensorStatus: 6|2@1+ (1,0) [0|0] "" X
 SG_ BCS2C_easyEntryReadyForward: 42|2@1+ (1,0) [0|0] "" X
 SG_ BCS2C_easyEntryReadyReverse: 44|2@1+ (1,0) [0|0] "" X
 SG_ BCS2C_easyEntrySwitchStatus: 8|3@1+ (1,0) [0|0] "" X
 SG_ BCS2C_easyEntrySwitchStatusLeft: 32|3@1+ (1,0) [0|0] "" X
 SG_ BCS2C_easyEntrySwitchStatusRight: 35|3@1+ (1,0) [0|0] "" X
 SG_ BCS2C_easyEntryUnlatchStatus: 38|2@1+ (1,0) [0|0] "" X
 SG_ BCS2C_trackHomeSensorStatus: 14|2@1+ (1,0) [0|0] "" X
 SG_ BCS2C_trackHomeSensorVoltage: 16|16@1- (0.00015259,0) [0|0] "V" X

BO_ 687 BCS2C_trackMovementStatus: 8 ETH
 SG_ BCS2C_isTrackMoving: 60|2@1+ (1,0) [0|0] "" X
 SG_ BCS2C_trackMotorCurrent: 32|16@1- (0.0030518,0) [0|0] "A" X
 SG_ BCS2C_trackMotorDutyCycle: 48|12@1- (0.04884,0) [0|0] "%" X
 SG_ BCS2C_trackMotorError: 0|12@1- (0.04884,0) [0|0] "%" X
 SG_ BCS2C_trackMotorPosition: 16|16@1- (1,0) [0|0] "INTEGRAL" X
 SG_ BCS2C_trackState: 12|4@1+ (1,0) [0|0] "" X

BO_ 1724 BCS2C_udsResponse: 8 ETH
 SG_ BCS2C_udsResponseData_H: 0|32@0+ (1,0) [0|0] "" X
 SG_ BCS2C_udsResponseData_L: 32|32@0+ (1,0) [0|0] "" X

BO_ 980 BCS2C_warningMatrix1: 8 ETH
 SG_ BCS2C_w001_WatchdogReset: 0|1@1+ (1,0) [0|0] "" X
 SG_ BCS2C_w002_PowerLossReset: 1|1@1+ (1,0) [0|0] "" X
 SG_ BCS2C_w003_SWAssertion: 2|1@1+ (1,0) [0|0] "" X
 SG_ BCS2C_w004_CANMIA: 3|1@1+ (1,0) [0|0] "" X
 SG_ BCS2C_w005_CANHighError: 4|1@1+ (1,0) [0|0] "" X
 SG_ BCS2C_w006_CANLowError: 5|1@1+ (1,0) [0|0] "" X
 SG_ BCS2C_w007_LINTimeout: 6|1@1+ (1,0) [0|0] "" X
 SG_ BCS2C_w008_LIN2Error: 7|1@1+ (1,0) [0|0] "" X
 SG_ BCS2C_w009_LIN3Error: 8|1@1+ (1,0) [0|0] "" X
 SG_ BCS2C_w010_ExtSupplyVoltError: 9|1@1+ (1,0) [0|0] "" X
 SG_ BCS2C_w011_ECUSupplyVoltError: 10|1@1+ (1,0) [0|0] "" X
 SG_ BCS2C_w012_CPUReset: 11|1@1+ (1,0) [0|0] "" X
 SG_ BCS2C_w013_Shared13: 12|1@1+ (1,0) [0|0] "" X
 SG_ BCS2C_w014_BridgeFault: 13|1@1+ (1,0) [0|0] "" X
 SG_ BCS2C_w015_NVMMAlert: 14|1@1+ (1,0) [0|0] "" X
 SG_ BCS2C_w016_MessageTimingError: 15|1@1+ (1,0) [0|0] "" X
 SG_ BCS2C_w017_AwakeForTooLong: 16|1@1+ (1,0) [0|0] "" X
 SG_ BCS2C_w018_ADCError: 17|1@1+ (1,0) [0|0] "" X
 SG_ BCS2C_w019_I2CError: 18|1@1+ (1,0) [0|0] "" X
 SG_ BCS2C_w020_PWMError: 19|1@1+ (1,0) [0|0] "" X
 SG_ BCS2C_w021_TaskSchedulerError: 20|1@1+ (1,0) [0|0] "" X
 SG_ BCS2C_w022_TaskInitError: 21|1@1+ (1,0) [0|0] "" X
 SG_ BCS2C_w023_SleepError: 22|1@1+ (1,0) [0|0] "" X
 SG_ BCS2C_w024_WakeError: 23|1@1+ (1,0) [0|0] "" X
 SG_ BCS2C_w025_CrashEvent: 24|1@1+ (1,0) [0|0] "" X
 SG_ BCS2C_w026_FlashMemoryError: 25|1@1+ (1,0) [0|0] "" X
 SG_ BCS2C_w027_NVRAMCorruption: 26|1@1+ (1,0) [0|0] "" X
 SG_ BCS2C_w028_NVRAMNotResponding: 27|1@1+ (1,0) [0|0] "" X
 SG_ BCS2C_w029_NVRAMUninitialized: 28|1@1+ (1,0) [0|0] "" X
 SG_ BCS2C_w030_SeatConfigError: 29|1@1+ (1,0) [0|0] "" X
 SG_ BCS2C_w040_trackMotorShort: 39|1@1+ (1,0) [0|0] "" X
 SG_ BCS2C_w041_trackMotorLowCurrent: 40|1@1+ (1,0) [0|0] "" X
 SG_ BCS2C_w042_trackMotorLogicTempUV: 41|1@1+ (1,0) [0|0] "" X
 SG_ BCS2C_w043_trackMotorOverCurr: 42|1@1+ (1,0) [0|0] "" X
 SG_ BCS2C_w044_trackMotorEncodeError: 43|1@1+ (1,0) [0|0] "" X
 SG_ BCS2C_w045_trackMotorUnderCurr: 44|1@1+ (1,0) [0|0] "" X
 SG_ BCS2C_w046_2RBuckleFaultSNA: 45|1@1+ (1,0) [0|0] "" X
 SG_ BCS2C_w047_2ROccupancyFaultSNA: 46|1@1+ (1,0) [0|0] "" X
 SG_ BCS2C_w048_3RBuckleFaultSNA: 47|1@1+ (1,0) [0|0] "" X
 SG_ BCS2C_w049_3ROccupancyFaultSNA: 48|1@1+ (1,0) [0|0] "" X
 SG_ BCS2C_w050_pitchMotorOverCurr: 49|1@1+ (1,0) [0|0] "" X
 SG_ BCS2C_w051_pitchMotorUnderCurr: 50|1@1+ (1,0) [0|0] "" X
 SG_ BCS2C_w052_pitchMotorEncodeError: 51|1@1+ (1,0) [0|0] "" X
 SG_ BCS2C_w053_2RCHeatrTmpSnsInvalid: 52|1@1+ (1,0) [0|0] "" X
 SG_ BCS2C_w054_2RCSeatHeatSlowRise: 53|1@1+ (1,0) [0|0] "" X
 SG_ BCS2C_w056_2RCHeatPadTempSensFLT: 55|1@1+ (1,0) [0|0] "" X
 SG_ BCS2C_w057_2RCBuckleFaultSNA: 56|1@1+ (1,0) [0|0] "" X
 SG_ BCS2C_w058_2RCOccupancyFaultSNA: 57|1@1+ (1,0) [0|0] "" X
 SG_ BCS2C_w060_3RFoldOverCurr: 59|1@1+ (1,0) [0|0] "" X
 SG_ BCS2C_w061_3RHeadrestUnderCurr: 60|1@1+ (1,0) [0|0] "" X
 SG_ BCS2C_w062_3RHeadrestOverCurr: 61|1@1+ (1,0) [0|0] "" X
 SG_ BCS2C_w063_sharedMotorLSD: 62|1@1+ (1,0) [0|0] "" X
 SG_ BCS2C_w064_3RFoldMotorLSD: 63|1@1+ (1,0) [0|0] "" X

BO_ 796 BCS2C_warningMatrix2: 8 ETH
 SG_ BCS2C_w065_latchMotorLSD: 0|1@1+ (1,0) [0|0] "" X
 SG_ BCS2C_w066_latchMotorOverCurr: 1|1@1+ (1,0) [0|0] "" X
 SG_ BCS2C_w067_latchMotorUnderCurr: 2|1@1+ (1,0) [0|0] "" X
 SG_ BCS2C_w068_latchMicroswitchError: 3|1@1+ (1,0) [0|0] "" X
 SG_ BCS2C_w070_2ROccupiedUnbuckled: 5|1@1+ (1,0) [0|0] "" X
 SG_ BCS2C_w071_3ROccupiedUnbuckled: 6|1@1+ (1,0) [0|0] "" X
 SG_ BCS2C_w072_2RObstacleDetected: 7|1@1+ (1,0) [0|0] "" X
 SG_ BCS2C_w073_occupiedUnsecured: 8|1@1+ (1,0) [0|0] "" X
 SG_ BCS2C_w074_2RowTrackObstacle: 9|1@1+ (1,0) [0|0] "" X
 SG_ BCS2C_w075_2RowPitchObstacle: 10|1@1+ (1,0) [0|0] "" X
 SG_ BCS2C_w076_unexpectedStop: 11|1@1+ (1,0) [0|0] "" X
 SG_ BCS2C_w077_jammedSeat: 12|1@1+ (1,0) [0|0] "" X
 SG_ BCS2C_w079_DvrSideCfgMismatch: 14|1@1+ (1,0) [0|0] "" X
 SG_ BCS2C_w081_trackUncalibrated: 16|1@1+ (1,0) [0|0] "" X
 SG_ BCS2C_w082_pitchUncalibrated: 17|1@1+ (1,0) [0|0] "" X
 SG_ BCS2C_w085_comfortSwitchMisuse: 20|1@1+ (1,0) [0|0] "" X
 SG_ BCS2C_w086_easyEntrySwitchMisuse: 21|1@1+ (1,0) [0|0] "" X
 SG_ BCS2C_w087_foldFlatSwitchMisuse: 22|1@1+ (1,0) [0|0] "" X
 SG_ BCS2C_w090_CrashUnlockError: 25|1@1+ (1,0) [0|0] "" X
 SG_ BCS2C_w091_CrashStateMismatch: 26|1@1+ (1,0) [0|0] "" X
 SG_ BCS2C_w093_OTPError: 28|1@1+ (1,0) [0|0] "" X
 SG_ BCS2C_w094_FreescaleHSDFault: 29|1@1+ (1,0) [0|0] "" X
 SG_ BCS2C_w095_SeatUncalibrated1Row: 30|1@1+ (1,0) [0|0] "" X
 SG_ BCS2C_w096_HeadUncalibrated1Row: 31|1@1+ (1,0) [0|0] "" X
 SG_ BCS2C_w097_6040SeatUnlatched: 32|1@1+ (1,0) [0|0] "" X
 SG_ BCS2C_w098_6040TrackUndercurrent: 33|1@1+ (1,0) [0|0] "" X
 SG_ BCS2C_w100_chargePumpFail: 35|1@1+ (1,0) [0|0] "" X
 SG_ BCS2C_w101_VBATOutOfRange: 36|1@1+ (1,0) [0|0] "" X
 SG_ BCS2C_w102_8vRegulatorOutOfRange: 37|1@1+ (1,0) [0|0] "" X
 SG_ BCS2C_w103_regulatorShortedToGND: 38|1@1+ (1,0) [0|0] "" X
 SG_ BCS2C_w104_ECUOverCurrent: 39|1@1+ (1,0) [0|0] "" X
 SG_ BCS2C_w105_ECUDebugMode: 40|1@1+ (1,0) [0|0] "" X
 SG_ BCS2C_w106_HighCPULoad: 41|1@1+ (1,0) [0|0] "" X
 SG_ BCS2C_w107_HighStackUsage: 42|1@1+ (1,0) [0|0] "" X
 SG_ BCS2C_w108_2RHeatrTmpSnsInvalid: 43|1@1+ (1,0) [0|0] "" X
 SG_ BCS2C_w109_3RHeatrTmpSnsInvalid: 44|1@1+ (1,0) [0|0] "" X
 SG_ BCS2C_w110_2RSeatHeatSlowRise: 45|1@1+ (1,0) [0|0] "" X
 SG_ BCS2C_w111_3RLSeatHeatFault: 46|1@1+ (1,0) [0|0] "" X
 SG_ BCS2C_w112_3RSeatHeatSlowRise: 47|1@1+ (1,0) [0|0] "" X
 SG_ BCS2C_w114_seatHeatFault: 49|1@1+ (1,0) [0|0] "" X
 SG_ BCS2C_w115_2RHeatPadTempSensFLT: 50|1@1+ (1,0) [0|0] "" X
 SG_ BCS2C_w116_3RHeatPadTempSensFLT: 51|1@1+ (1,0) [0|0] "" X
 SG_ BCS2C_w117_2RHeatPadOvercurrent: 52|1@1+ (1,0) [0|0] "" X
 SG_ BCS2C_w118_3RHeatPadOvercurrent: 53|1@1+ (1,0) [0|0] "" X
 SG_ BCS2C_w119_2RCHeatPadOvercurrent: 54|1@1+ (1,0) [0|0] "" X
 SG_ BCS2C_w120_trackMotorDisconnect: 55|1@1+ (1,0) [0|0] "" X
 SG_ BCS2C_w121_pitchMotorDisconnect: 56|1@1+ (1,0) [0|0] "" X
 SG_ BCS2C_w122_trackSensorDisconnect: 57|1@1+ (1,0) [0|0] "" X
 SG_ BCS2C_w123_pitchSensorDisconnect: 58|1@1+ (1,0) [0|0] "" X
 SG_ BCS2C_w124_3RFFMotorDisconnect: 59|1@1+ (1,0) [0|0] "" X
 SG_ BCS2C_w125_3RHeadMotorDisconnect: 60|1@1+ (1,0) [0|0] "" X
 SG_ BCS2C_w126_comfortHoldDown: 61|1@1+ (1,0) [0|0] "" X
 SG_ BCS2C_w127_easyEntryHoldDown: 62|1@1+ (1,0) [0|0] "" X
 SG_ BCS2C_w128_foldFlatHoldDown: 63|1@1+ (1,0) [0|0] "" X

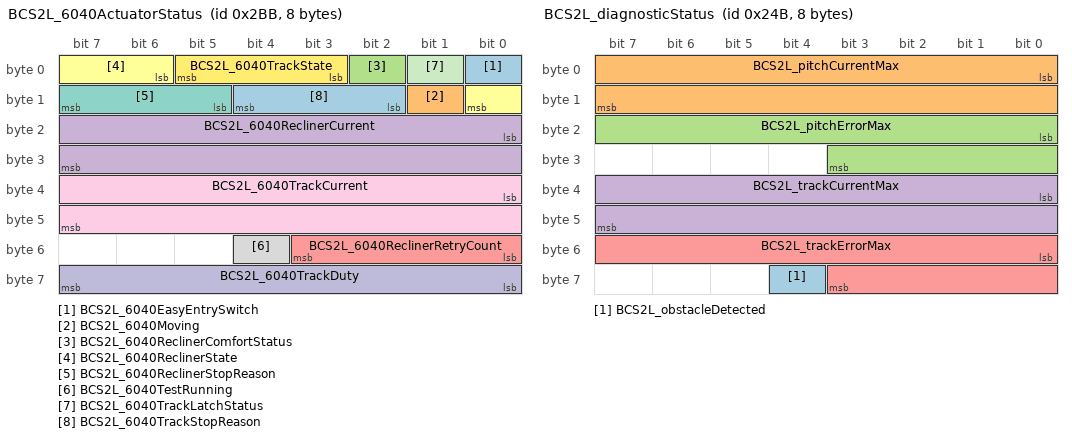
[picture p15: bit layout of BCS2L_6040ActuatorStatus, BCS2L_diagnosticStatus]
BO_ 699 BCS2L_6040ActuatorStatus: 8 ETH
 SG_ BCS2L_6040EasyEntrySwitch: 0|1@1+ (1,0) [0|0] "" X
 SG_ BCS2L_6040Moving: 9|1@1+ (1,0) [0|0] "" X
 SG_ BCS2L_6040ReclinerComfortStatus: 2|1@1+ (1,0) [0|0] "" X
 SG_ BCS2L_6040ReclinerCurrent: 16|16@1- (0.0030518,0) [0|0] "A" X
 SG_ BCS2L_6040ReclinerRetryCount: 48|4@1+ (1,0) [0|0] "" X
 SG_ BCS2L_6040ReclinerState: 6|3@1+ (1,0) [0|0] "" X
 SG_ BCS2L_6040ReclinerStopReason: 13|3@1+ (1,0) [0|0] "" X
 SG_ BCS2L_6040TestRunning: 52|1@1+ (1,0) [0|0] "" X
 SG_ BCS2L_6040TrackCurrent: 32|16@1- (0.0030518,0) [0|0] "A" X
 SG_ BCS2L_6040TrackDuty: 56|8@1- (1,0) [0|0] "%" X
 SG_ BCS2L_6040TrackLatchStatus: 1|1@1+ (1,0) [0|0] "" X
 SG_ BCS2L_6040TrackState: 3|3@1+ (1,0) [0|0] "" X
 SG_ BCS2L_6040TrackStopReason: 10|3@1+ (1,0) [0|0] "" X

BO_ 587 BCS2L_diagnosticStatus: 8 ETH
 SG_ BCS2L_obstacleDetected: 60|1@1+ (1,0) [0|0] "" X
 SG_ BCS2L_pitchCurrentMax: 0|16@1- (0.0030518,0) [0|0] "A" X
 SG_ BCS2L_pitchErrorMax: 16|12@1- (0.04884,0) [0|0] "%" X
 SG_ BCS2L_trackCurrentMax: 32|16@1- (0.0030518,0) [0|0] "A" X
 SG_ BCS2L_trackErrorMax: 48|12@1- (0.04884,0) [0|0] "%" X

BO_ 1311 BCS2L_info: 8 ETH
 SG_ BCS2L_infoIndex M: 0|8@1+ (1,0) [0|0] "" X
 SG_ BCS2L_infoBuildType m10: 8|8@1+ (1,0) [0|0] "" X
 SG_ BCS2L_infoBuildConfigID m10: 16|16@1+ (1,0) [0|0] "" X
 SG_ BCS2L_infoHardwareID m10: 32|16@1+ (1,0) [0|0] "" X
 SG_ BCS2L_infoComponentID m10: 48|16@1+ (1,0) [0|0] "" X
 SG_ BCS2L_infoPcbaID m11: 16|8@1+ (1,0) [0|0] "" X
 SG_ BCS2L_infoAssemblyID m11: 24|8@1+ (1,0) [0|0] "INTEGRAL" X
 SG_ BCS2L_infoUsageID m11: 32|16@1+ (1,0) [0|0] "" X
 SG_ BCS2L_infoSubUsageID m11: 48|16@1+ (1,0) [0|0] "" X
 SG_ BCS2L_infoApplicationCRC m13: 32|32@1+ (1,0) [0|0] "" X
 SG_ BCS2L_infoBootSvnRev m14: 8|24@1+ (1,0) [0|0] "" X
 SG_ BCS2L_infoAppGitHashBytes m17: 10|54@1+ (4,0) [0|0] "" X
 SG_ BCS2L_infoBootGitHashBytes m18: 10|54@1+ (4,0) [0|0] "" X
 SG_ BCS2L_infoPlatformType m19: 8|8@1+ (1,0) [0|0] "" X
 SG_ BCS2L_infoBootUdsProtoVersion m20: 8|8@1+ (1,0) [0|0] "" X
 SG_ BCS2L_infoBootloaderCRC m20: 32|32@1+ (1,0) [0|0] "" X

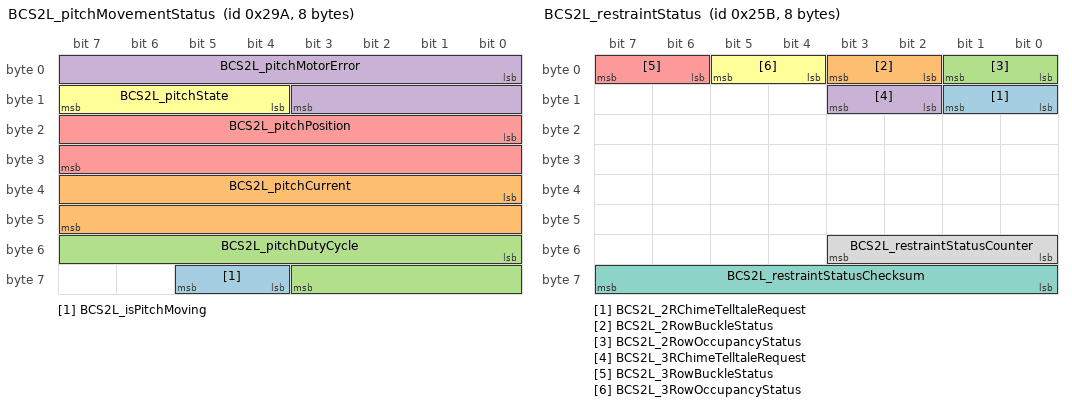
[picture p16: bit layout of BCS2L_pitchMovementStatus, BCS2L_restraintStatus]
BO_ 666 BCS2L_pitchMovementStatus: 8 ETH
 SG_ BCS2L_isPitchMoving: 60|2@1+ (1,0) [0|0] "" X
 SG_ BCS2L_pitchCurrent: 32|16@1- (0.0030518,0) [0|0] "A" X
 SG_ BCS2L_pitchDutyCycle: 48|12@1- (0.04884,0) [0|0] "%" X
 SG_ BCS2L_pitchMotorError: 0|12@1- (0.04884,0) [0|0] "%" X
 SG_ BCS2L_pitchPosition: 16|16@1- (1,0) [0|0] "INTEGRAL" X
 SG_ BCS2L_pitchState: 12|4@1+ (1,0) [0|0] "" X

BO_ 603 BCS2L_restraintStatus: 8 ETH
 SG_ BCS2L_2RChimeTelltaleRequest: 8|2@1+ (1,0) [0|0] "" X
 SG_ BCS2L_2RowBuckleStatus: 2|2@1+ (1,0) [0|0] "" X
 SG_ BCS2L_2RowOccupancyStatus: 0|2@1+ (1,0) [0|0] "" X
 SG_ BCS2L_3RChimeTelltaleRequest: 10|2@1+ (1,0) [0|0] "" X
 SG_ BCS2L_3RowBuckleStatus: 6|2@1+ (1,0) [0|0] "" X
 SG_ BCS2L_3RowOccupancyStatus: 4|2@1+ (1,0) [0|0] "" X
 SG_ BCS2L_restraintStatusChecksum: 56|8@1+ (1,0) [0|0] "" X
 SG_ BCS2L_restraintStatusCounter: 48|4@1+ (1,0) [0|0] "" X

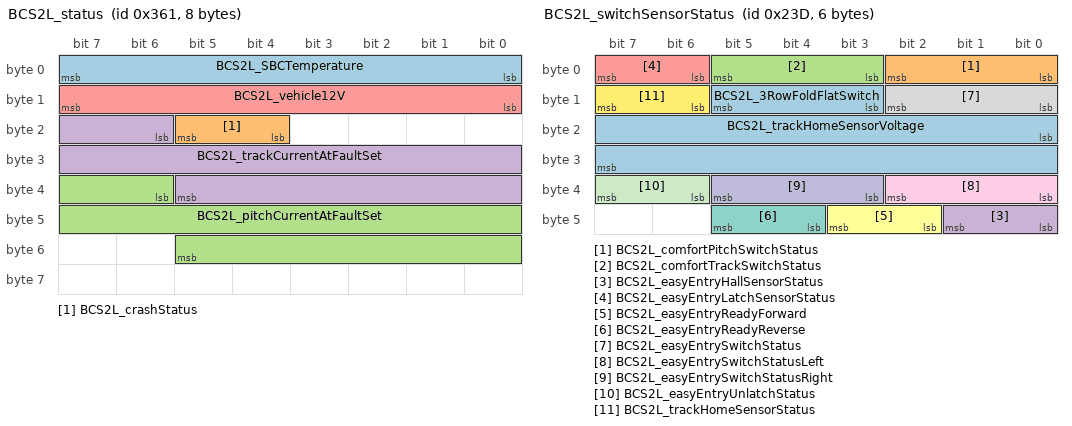
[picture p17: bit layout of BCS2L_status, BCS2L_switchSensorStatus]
BO_ 865 BCS2L_status: 8 ETH
 SG_ BCS2L_SBCTemperature: 0|8@1- (1,0) [0|0] "C" X
 SG_ BCS2L_crashStatus: 20|2@1+ (1,0) [0|0] "" X
 SG_ BCS2L_pitchCurrentAtFaultSet: 38|16@1- (0.0030518,0) [0|0] "A" X
 SG_ BCS2L_trackCurrentAtFaultSet: 22|16@1- (0.0030518,0) [0|0] "A" X
 SG_ BCS2L_vehicle12V: 8|8@1+ (0.1,0) [0|0] "V" X

BO_ 573 BCS2L_switchSensorStatus: 6 ETH
 SG_ BCS2L_3RowFoldFlatSwitch: 11|3@1+ (1,0) [0|0] "" X
 SG_ BCS2L_comfortPitchSwitchStatus: 0|3@1+ (1,0) [0|0] "" X
 SG_ BCS2L_comfortTrackSwitchStatus: 3|3@1+ (1,0) [0|0] "" X
 SG_ BCS2L_easyEntryHallSensorStatus: 40|2@1+ (1,0) [0|0] "" X
 SG_ BCS2L_easyEntryLatchSensorStatus: 6|2@1+ (1,0) [0|0] "" X
 SG_ BCS2L_easyEntryReadyForward: 42|2@1+ (1,0) [0|0] "" X
 SG_ BCS2L_easyEntryReadyReverse: 44|2@1+ (1,0) [0|0] "" X
 SG_ BCS2L_easyEntrySwitchStatus: 8|3@1+ (1,0) [0|0] "" X
 SG_ BCS2L_easyEntrySwitchStatusLeft: 32|3@1+ (1,0) [0|0] "" X
 SG_ BCS2L_easyEntrySwitchStatusRight: 35|3@1+ (1,0) [0|0] "" X
 SG_ BCS2L_easyEntryUnlatchStatus: 38|2@1+ (1,0) [0|0] "" X
 SG_ BCS2L_trackHomeSensorStatus: 14|2@1+ (1,0) [0|0] "" X
 SG_ BCS2L_trackHomeSensorVoltage: 16|16@1- (0.00015259,0) [0|0] "V" X

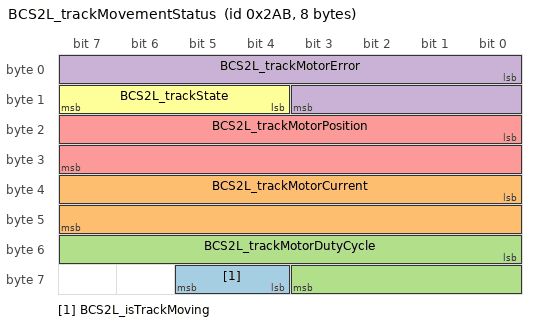
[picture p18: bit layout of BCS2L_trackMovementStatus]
BO_ 683 BCS2L_trackMovementStatus: 8 ETH
 SG_ BCS2L_isTrackMoving: 60|2@1+ (1,0) [0|0] "" X
 SG_ BCS2L_trackMotorCurrent: 32|16@1- (0.0030518,0) [0|0] "A" X
 SG_ BCS2L_trackMotorDutyCycle: 48|12@1- (0.04884,0) [0|0] "%" X
 SG_ BCS2L_trackMotorError: 0|12@1- (0.04884,0) [0|0] "%" X
 SG_ BCS2L_trackMotorPosition: 16|16@1- (1,0) [0|0] "INTEGRAL" X
 SG_ BCS2L_trackState: 12|4@1+ (1,0) [0|0] "" X

BO_ 1723 BCS2L_udsResponse: 8 ETH
 SG_ BCS2L_udsResponseData_H: 0|32@0+ (1,0) [0|0] "" X
 SG_ BCS2L_udsResponseData_L: 32|32@0+ (1,0) [0|0] "" X

BO_ 779 BCS2L_warningMatrix1: 8 ETH
 SG_ BCS2L_w001_WatchdogReset: 0|1@1+ (1,0) [0|0] "" X
 SG_ BCS2L_w002_PowerLossReset: 1|1@1+ (1,0) [0|0] "" X
 SG_ BCS2L_w003_SWAssertion: 2|1@1+ (1,0) [0|0] "" X
 SG_ BCS2L_w004_CANMIA: 3|1@1+ (1,0) [0|0] "" X
 SG_ BCS2L_w005_CANHighError: 4|1@1+ (1,0) [0|0] "" X
 SG_ BCS2L_w006_CANLowError: 5|1@1+ (1,0) [0|0] "" X
 SG_ BCS2L_w007_LINTimeout: 6|1@1+ (1,0) [0|0] "" X
 SG_ BCS2L_w008_LIN2Error: 7|1@1+ (1,0) [0|0] "" X
 SG_ BCS2L_w009_LIN3Error: 8|1@1+ (1,0) [0|0] "" X
 SG_ BCS2L_w010_ExtSupplyVoltError: 9|1@1+ (1,0) [0|0] "" X
 SG_ BCS2L_w011_ECUSupplyVoltError: 10|1@1+ (1,0) [0|0] "" X
 SG_ BCS2L_w012_CPUReset: 11|1@1+ (1,0) [0|0] "" X
 SG_ BCS2L_w013_Shared13: 12|1@1+ (1,0) [0|0] "" X
 SG_ BCS2L_w014_BridgeFault: 13|1@1+ (1,0) [0|0] "" X
 SG_ BCS2L_w015_NVMMAlert: 14|1@1+ (1,0) [0|0] "" X
 SG_ BCS2L_w016_MessageTimingError: 15|1@1+ (1,0) [0|0] "" X
 SG_ BCS2L_w017_AwakeForTooLong: 16|1@1+ (1,0) [0|0] "" X
 SG_ BCS2L_w018_ADCError: 17|1@1+ (1,0) [0|0] "" X
 SG_ BCS2L_w019_I2CError: 18|1@1+ (1,0) [0|0] "" X
 SG_ BCS2L_w020_PWMError: 19|1@1+ (1,0) [0|0] "" X
 SG_ BCS2L_w021_TaskSchedulerError: 20|1@1+ (1,0) [0|0] "" X
 SG_ BCS2L_w022_TaskInitError: 21|1@1+ (1,0) [0|0] "" X
 SG_ BCS2L_w023_SleepError: 22|1@1+ (1,0) [0|0] "" X
 SG_ BCS2L_w024_WakeError: 23|1@1+ (1,0) [0|0] "" X
 SG_ BCS2L_w025_CrashEvent: 24|1@1+ (1,0) [0|0] "" X
 SG_ BCS2L_w026_FlashMemoryError: 25|1@1+ (1,0) [0|0] "" X
 SG_ BCS2L_w027_NVRAMCorruption: 26|1@1+ (1,0) [0|0] "" X
 SG_ BCS2L_w028_NVRAMNotResponding: 27|1@1+ (1,0) [0|0] "" X
 SG_ BCS2L_w029_NVRAMUninitialized: 28|1@1+ (1,0) [0|0] "" X
 SG_ BCS2L_w030_SeatConfigError: 29|1@1+ (1,0) [0|0] "" X
 SG_ BCS2L_w040_trackMotorShort: 39|1@1+ (1,0) [0|0] "" X
 SG_ BCS2L_w041_trackMotorLowCurrent: 40|1@1+ (1,0) [0|0] "" X
 SG_ BCS2L_w042_trackMotorLogicTempUV: 41|1@1+ (1,0) [0|0] "" X
 SG_ BCS2L_w043_trackMotorOverCurr: 42|1@1+ (1,0) [0|0] "" X
 SG_ BCS2L_w044_trackMotorEncodeError: 43|1@1+ (1,0) [0|0] "" X
 SG_ BCS2L_w045_trackMotorUnderCurr: 44|1@1+ (1,0) [0|0] "" X
 SG_ BCS2L_w046_2RBuckleFaultSNA: 45|1@1+ (1,0) [0|0] "" X
 SG_ BCS2L_w047_2ROccupancyFaultSNA: 46|1@1+ (1,0) [0|0] "" X
 SG_ BCS2L_w048_3RBuckleFaultSNA: 47|1@1+ (1,0) [0|0] "" X
 SG_ BCS2L_w049_3ROccupancyFaultSNA: 48|1@1+ (1,0) [0|0] "" X
 SG_ BCS2L_w050_pitchMotorOverCurr: 49|1@1+ (1,0) [0|0] "" X
 SG_ BCS2L_w051_pitchMotorUnderCurr: 50|1@1+ (1,0) [0|0] "" X
 SG_ BCS2L_w052_pitchMotorEncodeError: 51|1@1+ (1,0) [0|0] "" X
 SG_ BCS2L_w053_2RCHeatrTmpSnsInvalid: 52|1@1+ (1,0) [0|0] "" X
 SG_ BCS2L_w054_2RCSeatHeatSlowRise: 53|1@1+ (1,0) [0|0] "" X
 SG_ BCS2L_w056_2RCHeatPadTempSensFLT: 55|1@1+ (1,0) [0|0] "" X
 SG_ BCS2L_w057_2RCBuckleFaultSNA: 56|1@1+ (1,0) [0|0] "" X
 SG_ BCS2L_w058_2RCOccupancyFaultSNA: 57|1@1+ (1,0) [0|0] "" X
 SG_ BCS2L_w060_3RFoldOverCurr: 59|1@1+ (1,0) [0|0] "" X
 SG_ BCS2L_w061_3RHeadrestUnderCurr: 60|1@1+ (1,0) [0|0] "" X
 SG_ BCS2L_w062_3RHeadrestOverCurr: 61|1@1+ (1,0) [0|0] "" X
 SG_ BCS2L_w063_sharedMotorLSD: 62|1@1+ (1,0) [0|0] "" X
 SG_ BCS2L_w064_3RFoldMotorLSD: 63|1@1+ (1,0) [0|0] "" X

CM_ "Generated by Tesla Firmware Decode @ version 923e442d6230241a259eeb3f415525373d40325c";

BA_DEF_ BO_ "GenMsgSendType" ENUM "Cyclic";
BA_DEF_ BO_ "GenMsgCycleTime" INT 0 60000;

BA_ "GenMsgSendType" BO_ 1020 0;
BA_ "GenMsgCycleTime" BO_ 1020 1000;

BA_ "GenMsgSendType" BO_ 1010 0;
BA_ "GenMsgCycleTime" BO_ 1010 1000;

BA_ "GenMsgSendType" BO_ 1017 0;
BA_ "GenMsgCycleTime" BO_ 1017 500;

BA_ "GenMsgSendType" BO_ 1040 0;
BA_ "GenMsgCycleTime" BO_ 1040 500;

BA_ "GenMsgSendType" BO_ 1097 0;
BA_ "GenMsgCycleTime" BO_ 1097 1000;

BA_ "GenMsgSendType" BO_ 1049 0;
BA_ "GenMsgCycleTime" BO_ 1049 1000;

BA_ "GenMsgSendType" BO_ 1065 0;
BA_ "GenMsgCycleTime" BO_ 1065 1000;

BA_ "GenMsgSendType" BO_ 1081 0;
BA_ "GenMsgCycleTime" BO_ 1081 1000;

BA_ "GenMsgSendType" BO_ 1129 0;
BA_ "GenMsgCycleTime" BO_ 1129 1000;

BA_ "GenMsgSendType" BO_ 811 0;
BA_ "GenMsgCycleTime" BO_ 811 1000;

BA_ "GenMsgSendType" BO_ 876 0;
BA_ "GenMsgCycleTime" BO_ 876 1000;

BA_ "GenMsgSendType" BO_ 1113 0;
BA_ "GenMsgCycleTime" BO_ 1113 1000;

BA_ "GenMsgSendType" BO_ 848 0;
BA_ "GenMsgCycleTime" BO_ 848 1000;

BA_ "GenMsgSendType" BO_ 283 0;
BA_ "GenMsgCycleTime" BO_ 283 100;

BA_ "GenMsgSendType" BO_ 1297 0;
BA_ "GenMsgCycleTime" BO_ 1297 1000;

BA_ "GenMsgSendType" BO_ 594 0;
BA_ "GenMsgCycleTime" BO_ 594 100;

BA_ "GenMsgSendType" BO_ 1533 0;
BA_ "GenMsgCycleTime" BO_ 1533 1000;

BA_ "GenMsgSendType" BO_ 1075 0;
BA_ "GenMsgCycleTime" BO_ 1075 100;

BA_ "GenMsgSendType" BO_ 577 0;
BA_ "GenMsgCycleTime" BO_ 577 100;

BA_ "GenMsgSendType" BO_ 517 0;
BA_ "GenMsgCycleTime" BO_ 517 100;

BA_ "GenMsgSendType" BO_ 938 0;
BA_ "GenMsgCycleTime" BO_ 938 100;

BA_ "GenMsgSendType" BO_ 625 0;
BA_ "GenMsgCycleTime" BO_ 625 100;

BA_ "GenMsgSendType" BO_ 769 0;
BA_ "GenMsgCycleTime" BO_ 769 1000;

BA_ "GenMsgSendType" BO_ 785 0;
BA_ "GenMsgCycleTime" BO_ 785 1000;

BA_ "GenMsgSendType" BO_ 1003 0;
BA_ "GenMsgCycleTime" BO_ 1003 100;

BA_ "GenMsgSendType" BO_ 991 0;
BA_ "GenMsgCycleTime" BO_ 991 100;

BA_ "GenMsgSendType" BO_ 1313 0;
BA_ "GenMsgCycleTime" BO_ 1313 1000;

BA_ "GenMsgSendType" BO_ 1001 0;
BA_ "GenMsgCycleTime" BO_ 1001 100;

BA_ "GenMsgSendType" BO_ 993 0;
BA_ "GenMsgCycleTime" BO_ 993 100;

BA_ "GenMsgSendType" BO_ 996 0;
BA_ "GenMsgCycleTime" BO_ 996 100;

BA_ "GenMsgSendType" BO_ 318 0;
BA_ "GenMsgCycleTime" BO_ 318 1000;

BA_ "GenMsgSendType" BO_ 334 0;
BA_ "GenMsgCycleTime" BO_ 334 1000;

BA_ "GenMsgSendType" BO_ 350 0;
BA_ "GenMsgCycleTime" BO_ 350 1000;

BA_ "GenMsgSendType" BO_ 1005 0;
BA_ "GenMsgCycleTime" BO_ 1005 100;

BA_ "GenMsgSendType" BO_ 992 0;
BA_ "GenMsgCycleTime" BO_ 992 100;

BA_ "GenMsgSendType" BO_ 1316 0;
BA_ "GenMsgCycleTime" BO_ 1316 1000;

BA_ "GenMsgSendType" BO_ 1004 0;
BA_ "GenMsgCycleTime" BO_ 1004 100;

BA_ "GenMsgSendType" BO_ 995 0;
BA_ "GenMsgCycleTime" BO_ 995 100;

BA_ "GenMsgSendType" BO_ 997 0;
BA_ "GenMsgCycleTime" BO_ 997 100;

BA_ "GenMsgSendType" BO_ 314 0;
BA_ "GenMsgCycleTime" BO_ 314 1000;

BA_ "GenMsgSendType" BO_ 330 0;
BA_ "GenMsgCycleTime" BO_ 330 1000;

BA_ "GenMsgSendType" BO_ 346 0;
BA_ "GenMsgCycleTime" BO_ 346 1000;

BA_ "GenMsgSendType" BO_ 1956 0;
BA_ "GenMsgCycleTime" BO_ 1956 1000;

BA_ "GenMsgSendType" BO_ 534 0;
BA_ "GenMsgCycleTime" BO_ 534 100;

BA_ "GenMsgSendType" BO_ 1295 0;
BA_ "GenMsgCycleTime" BO_ 1295 1000;

BA_ "GenMsgSendType" BO_ 514 0;
BA_ "GenMsgCycleTime" BO_ 514 100;

BA_ "GenMsgSendType" BO_ 872 0;
BA_ "GenMsgCycleTime" BO_ 872 1000;

BA_ "GenMsgSendType" BO_ 988 0;
BA_ "GenMsgCycleTime" BO_ 988 1000;

BA_ "GenMsgSendType" BO_ 1957 0;
BA_ "GenMsgCycleTime" BO_ 1957 1000;

BA_ "GenMsgSendType" BO_ 1296 0;
BA_ "GenMsgCycleTime" BO_ 1296 1000;

BA_ "GenMsgSendType" BO_ 512 0;
BA_ "GenMsgCycleTime" BO_ 512 100;

BA_ "GenMsgSendType" BO_ 773 0;
BA_ "GenMsgCycleTime" BO_ 773 1000;

BA_ "GenMsgSendType" BO_ 789 0;
BA_ "GenMsgCycleTime" BO_ 789 1000;

BA_ "GenMsgSendType" BO_ 1301 0;
BA_ "GenMsgCycleTime" BO_ 1301 1000;

BA_ "GenMsgSendType" BO_ 530 0;
BA_ "GenMsgCycleTime" BO_ 530 100;

BA_ "GenMsgSendType" BO_ 527 0;
BA_ "GenMsgCycleTime" BO_ 527 100;

BA_ "GenMsgSendType" BO_ 871 0;
BA_ "GenMsgCycleTime" BO_ 871 1000;

BA_ "GenMsgSendType" BO_ 787 0;
BA_ "GenMsgCycleTime" BO_ 787 1000;

BA_ "GenMsgSendType" BO_ 3 0;
BA_ "GenMsgCycleTime" BO_ 3 100;

BA_ "GenMsgSendType" BO_ 532 0;
BA_ "GenMsgCycleTime" BO_ 532 100;

BA_ "GenMsgSendType" BO_ 1303 0;
BA_ "GenMsgCycleTime" BO_ 1303 1000;

BA_ "GenMsgSendType" BO_ 518 0;
BA_ "GenMsgCycleTime" BO_ 518 100;

BA_ "GenMsgSendType" BO_ 974 0;
BA_ "GenMsgCycleTime" BO_ 974 1000;

BA_ "GenMsgSendType" BO_ 990 0;
BA_ "GenMsgCycleTime" BO_ 990 1000;

BA_ "GenMsgSendType" BO_ 538 0;
BA_ "GenMsgCycleTime" BO_ 538 100;

BA_ "GenMsgSendType" BO_ 1299 0;
BA_ "GenMsgCycleTime" BO_ 1299 1000;

BA_ "GenMsgSendType" BO_ 562 0;
BA_ "GenMsgCycleTime" BO_ 562 100;

BA_ "GenMsgSendType" BO_ 511 0;
BA_ "GenMsgCycleTime" BO_ 511 100;

BA_ "GenMsgSendType" BO_ 870 0;
BA_ "GenMsgCycleTime" BO_ 870 1000;

BA_ "GenMsgSendType" BO_ 886 0;
BA_ "GenMsgCycleTime" BO_ 886 1000;

BA_ "GenMsgSendType" BO_ 1304 0;
BA_ "GenMsgCycleTime" BO_ 1304 1000;

BA_ "GenMsgSendType" BO_ 519 0;
BA_ "GenMsgCycleTime" BO_ 519 100;

BA_ "GenMsgSendType" BO_ 875 0;
BA_ "GenMsgCycleTime" BO_ 875 1000;

BA_ "GenMsgSendType" BO_ 891 0;
BA_ "GenMsgCycleTime" BO_ 891 1000;

BA_ "GenMsgSendType" BO_ 586 0;
BA_ "GenMsgCycleTime" BO_ 586 100;

BA_ "GenMsgSendType" BO_ 667 0;
BA_ "GenMsgCycleTime" BO_ 667 100;

BA_ "GenMsgSendType" BO_ 604 0;
BA_ "GenMsgCycleTime" BO_ 604 100;

BA_ "GenMsgSendType" BO_ 866 0;
BA_ "GenMsgCycleTime" BO_ 866 1000;

BA_ "GenMsgSendType" BO_ 574 0;
BA_ "GenMsgCycleTime" BO_ 574 100;

BA_ "GenMsgSendType" BO_ 687 0;
BA_ "GenMsgCycleTime" BO_ 687 100;

BA_ "GenMsgSendType" BO_ 980 0;
BA_ "GenMsgCycleTime" BO_ 980 1000;

BA_ "GenMsgSendType" BO_ 796 0;
BA_ "GenMsgCycleTime" BO_ 796 1000;

BA_ "GenMsgSendType" BO_ 699 0;
BA_ "GenMsgCycleTime" BO_ 699 100;

BA_ "GenMsgSendType" BO_ 587 0;
BA_ "GenMsgCycleTime" BO_ 587 100;

BA_ "GenMsgSendType" BO_ 666 0;
BA_ "GenMsgCycleTime" BO_ 666 100;

BA_ "GenMsgSendType" BO_ 603 0;
BA_ "GenMsgCycleTime" BO_ 603 100;

BA_ "GenMsgSendType" BO_ 865 0;
BA_ "GenMsgCycleTime" BO_ 865 1000;

BA_ "GenMsgSendType" BO_ 573 0;
BA_ "GenMsgCycleTime" BO_ 573 100;

BA_ "GenMsgSendType" BO_ 683 0;
BA_ "GenMsgCycleTime" BO_ 683 100;

BA_ "GenMsgSendType" BO_ 779 0;
BA_ "GenMsgCycleTime" BO_ 779 1000;

VAL_ 1020 APP_decisionTemperature 0 "UNKNOWN";
VAL_ 1020 APP_parkerATemperature 0 "UNKNOWN";
VAL_ 1020 APP_parkerBTemperature 0 "UNKNOWN";
VAL_ 1020 APP_parkerExtTemperature 0 "UNKNOWN";
VAL_ 1020 APP_pascalExtTemperature 0 "UNKNOWN";
VAL_ 1020 APP_pascalTemperature 0 "UNKNOWN";

VAL_ 1010 APP_cameraPosition 0 "INVALID" 1 "MAIN" 2 "NARROW" 3 "FISHEYE" 4 "L_PILLAR" 5 "R_PILLAR" 6 "L_REPEATER" 7 "R_REPEATER" 8 "BACKUP";
VAL_ 1010 APP_mainCamExtPitchCal 511 "SNA";
VAL_ 1010 APP_mainCamExtYawCal 511 "SNA";
VAL_ 1010 APP_mainCalibTime 127 "SNA";
VAL_ 1010 APP_mainCalibProgress 127 "SNA";
VAL_ 1010 APP_narrowCamExtPitchCal 511 "SNA";
VAL_ 1010 APP_narrowCamExtYawCal 511 "SNA";
VAL_ 1010 APP_narrowCalibTime 127 "SNA";
VAL_ 1010 APP_narrowCalibProgress 127 "SNA";
VAL_ 1010 APP_fisheyeCamExtPitchCal 511 "SNA";
VAL_ 1010 APP_fisheyeCamExtYawCal 511 "SNA";
VAL_ 1010 APP_fisheyeCalibTime 127 "SNA";
VAL_ 1010 APP_fisheyeCalibProgress 127 "SNA";
VAL_ 1010 APP_lPillarCamExtPitchCal 511 "SNA";
VAL_ 1010 APP_lPillarCamExtYawCal 511 "SNA";
VAL_ 1010 APP_lPillarCalibTime 127 "SNA";
VAL_ 1010 APP_lPillarCalibProgress 127 "SNA";
VAL_ 1010 APP_rPillarCamExtPitchCal 511 "SNA";
VAL_ 1010 APP_rPillarCamExtYawCal 511 "SNA";
VAL_ 1010 APP_rPillarCalibTime 127 "SNA";
VAL_ 1010 APP_rPillarCalibProgress 127 "SNA";
VAL_ 1010 APP_lRepeatCamExtPitchCal 511 "SNA";
VAL_ 1010 APP_lRepeatCamExtYawCal 511 "SNA";
VAL_ 1010 APP_lRepeatCalibTime 127 "SNA";
VAL_ 1010 APP_lRepeatCalibProgress 127 "SNA";
VAL_ 1010 APP_rRepeatCamExtPitchCal 511 "SNA";
VAL_ 1010 APP_rRepeatCamExtYawCal 511 "SNA";
VAL_ 1010 APP_rRepeatCalibTime 127 "SNA";
VAL_ 1010 APP_rRepeatCalibProgress 127 "SNA";
VAL_ 1010 APP_backupCamExtPitchCal 511 "SNA";
VAL_ 1010 APP_backupCamExtYawCal 511 "SNA";
VAL_ 1010 APP_backupCalibTime 127 "SNA";
VAL_ 1010 APP_backupCalibProgress 127 "SNA";

VAL_ 1017 APP_backupCameraLUX 254 "SATURATED" 255 "SNA";
VAL_ 1017 APP_fisheyeCameraLUX 254 "SATURATED" 255 "SNA";
VAL_ 1017 APP_lPillarCameraLUX 254 "SATURATED" 255 "SNA";
VAL_ 1017 APP_lRepeatCameraLUX 254 "SATURATED" 255 "SNA";
VAL_ 1017 APP_mainCameraLUX 254 "SATURATED" 255 "SNA";
VAL_ 1017 APP_narrowCameraLUX 254 "SATURATED" 255 "SNA";
VAL_ 1017 APP_rPillarCameraLUX 254 "SATURATED" 255 "SNA";
VAL_ 1017 APP_rRepeatCameraLUX 254 "SATURATED" 255 "SNA";

VAL_ 283 CurrentLevel 3 "LOW_LEVEL" 4 "NORMAL_LEVEL" 5 "HIGH_LEVEL" 6 "VERY_HIGH_LEVEL";
VAL_ 283 LC_LimpHomeMode 0 "NO_LIMP_HOME_MODE" 1 "LIMP_HOME_MODE_10" 2 "LIMP_HOME_MODE_20" 3 "LIMP_HOME_MODE_30" 4 "LIMP_HOME_MODE_40" 5 "LIMP_HOME_MODE_50" 6 "LIMP_HOME_MODE_60" 7 "LIMP_HOME_MODE_70";
VAL_ 283 SysDisabled 0 "ENABLED" 1 "DISABLED";
VAL_ 283 TargetLevel 0 "NOT_DEFINED_0" 1 "NOT_DEFINED_1" 2 "NOT_DEFINED_2" 3 "LOW_LEVEL" 4 "NORMAL_LEVEL" 5 "HIGH_LEVEL" 6 "VERY_HIGH_LEVEL" 7 "VERY_LOW_LEVEL";
VAL_ 283 Wala_LC_red 0 "OFF" 1 "ON";
VAL_ 283 Wala_LC_yel 0 "OFF" 1 "ON";

VAL_ 1297 BCCEN_infoIndex 0 "DEPRECATED_0" 1 "DEPRECATED_1" 2 "DEPRECATED_2" 3 "DEPRECATED_3" 4 "DEPRECATED_4" 5 "DEPRECATED_5" 6 "DEPRECATED_6" 7 "DEPRECATED_7" 8 "DEPRECATED_8" 9 "DEPRECATED_9" 10 "BUILD_HWID_COMPONENTID" 11 "PCBAID_ASSYID_USAGEID" 13 "APP_CRC" 14 "BOOTLOADER_SVN" 15 "BOOTLOADER_CRC" 16 "SUBCOMPONENT1" 17 "APP_GITHASH" 18 "BOOTLOADER_GITHASH" 19 "VERSION_DEPRECATED" 20 "UDS_PROTOCOL_BOOTCRC" 23 "SUBCOMPONENT2" 24 "SUBCOMPONENT3" 31 "SUBCOMPONENT4" 255 "END";
VAL_ 1297 BCCEN_infoBuildType 0 "UNKNOWN_BUILD" 1 "PLATFORM_BUILD" 2 "LOCAL_BUILD" 3 "TRACEABLE_CI_BUILD" 4 "MFG_BUILD";
VAL_ 1297 BCCEN_infoAssemblyID 1 "ASSEMBLY1" 255 "ASSEMBLY_SNA";

VAL_ 594 BCCEN_activeKeyFob 0 "0" 1 "1" 2 "2" 3 "3" 4 "4" 5 "5" 6 "6" 7 "NONE";
VAL_ 594 BCCEN_deadKeyFobAccess 0 "NOT_ACTIVE" 1 "ACTIVE" 2 "NO_RESPONSE" 3 "AUTH_FAILURE" 4 "AUTH_SUCCESS";
VAL_ 594 BCCEN_keyFob1Battery 0 "BATTERY_OK" 1 "BATTERY_LOW" 2 "BATTERY_NEW" 3 "NO_INFO";
VAL_ 594 BCCEN_keyFob2Battery 0 "BATTERY_OK" 1 "BATTERY_LOW" 2 "BATTERY_NEW" 3 "NO_INFO";
VAL_ 594 BCCEN_keyFob3Battery 0 "BATTERY_OK" 1 "BATTERY_LOW" 2 "BATTERY_NEW" 3 "NO_INFO";
VAL_ 594 BCCEN_keyFob4Battery 0 "BATTERY_OK" 1 "BATTERY_LOW" 2 "BATTERY_NEW" 3 "NO_INFO";
VAL_ 594 BCCEN_keyFob5Battery 0 "BATTERY_OK" 1 "BATTERY_LOW" 2 "BATTERY_NEW" 3 "NO_INFO";
VAL_ 594 BCCEN_keyFob6Battery 0 "BATTERY_OK" 1 "BATTERY_LOW" 2 "BATTERY_NEW" 3 "NO_INFO";
VAL_ 594 BCCEN_keyFob7Battery 0 "BATTERY_OK" 1 "BATTERY_LOW" 2 "BATTERY_NEW" 3 "NO_INFO";
VAL_ 594 BCCEN_keyFob8Battery 0 "BATTERY_OK" 1 "BATTERY_LOW" 2 "BATTERY_NEW" 3 "NO_INFO";
VAL_ 594 BCCEN_keyFobAuthenticationStatus 0 "NONE" 1 "IN_PROGRESS" 2 "AUTHENTICATED" 3 "SNA";
VAL_ 594 BCCEN_keyLocation 0 "NOT_PRESENT" 1 "OUTSIDE" 2 "INSIDE" 3 "UNKNOWN" 15 "SNA";
VAL_ 594 BCCEN_keyPollingStatus 0 "INACTIVE" 1 "TYPE_LOCATION" 2 "TYPE_APPROACH" 3 "RESERVED" 4 "RESERVED2" 5 "RESERVED3" 6 "RESERVED4" 7 "SNA";
VAL_ 594 BCCEN_keyPresent 0 "NOT_PRESENT" 1 "PRESENT" 2 "UNKNOWN";

VAL_ 1533 BCCEN_keyVersionInfoIndex 0 "KEY_1_BLE_ID" 1 "KEY_1_LF_VERSION" 2 "KEY_1_BLE_APP_GIT_HASH" 3 "KEY_1_BLE_BOOTLOADER_GIT_HASH" 4 "KEY_1_BLE_CRC" 5 "KEY_2_BLE_ID" 6 "KEY_2_LF_VERSION" 7 "KEY_2_BLE_APP_GIT_HASH" 8 "KEY_2_BLE_BOOTLOADER_GIT_HASH" 9 "KEY_2_BLE_CRC" 10 "KEY_3_BLE_ID" 11 "KEY_3_LF_VERSION" 12 "KEY_3_BLE_APP_GIT_HASH" 13 "KEY_3_BLE_BOOTLOADER_GIT_HASH" 14 "KEY_3_BLE_CRC" 15 "KEY_4_BLE_ID" 16 "KEY_4_LF_VERSION" 17 "KEY_4_BLE_APP_GIT_HASH" 18 "KEY_4_BLE_BOOTLOADER_GIT_HASH" 19 "KEY_4_BLE_CRC" 20 "KEY_5_BLE_ID" 21 "KEY_5_LF_VERSION" 22 "KEY_5_BLE_APP_GIT_HASH" 23 "KEY_5_BLE_BOOTLOADER_GIT_HASH" 24 "KEY_5_BLE_CRC" 25 "KEY_6_BLE_ID" 26 "KEY_6_LF_VERSION" 27 "KEY_6_BLE_APP_GIT_HASH" 28 "KEY_6_BLE_BOOTLOADER_GIT_HASH" 29 "KEY_6_BLE_CRC" 30 "KEY_7_BLE_ID" 31 "KEY_7_LF_VERSION" 32 "KEY_7_BLE_APP_GIT_HASH" 33 "KEY_7_BLE_BOOTLOADER_GIT_HASH" 34 "KEY_7_BLE_CRC" 35 "KEY_8_BLE_ID" 36 "KEY_8_LF_VERSION" 37 "KEY_8_BLE_APP_GIT_HASH" 38 "KEY_8_BLE_BOOTLOADER_GIT_HASH" 39 "KEY_8_BLE_CRC" 40 "BLEKEY_TYPE_A_STAGED_GIT_HASH" 41 "BCKEYLFSE_STAGED_GIT_HASH" 42 "BCSE_STAGED_GIT_HASH" 43 "BLEKEY_TYPE_A_STAGED_HWID_COMPONENTID" 44 "BCKEYLF_STAGED_CRC_HWID_COMPONENTID" 45 "BCSE_STAGED_CRC_HWID" 255 "KEY_END";

VAL_ 1075 BCCEN_closureEasterEggCommand 0 "IDLE" 1 "PLAY";
VAL_ 1075 BCCEN_keyfobCloseAllRequest 0 "IDLE" 1 "CLOSE" 2 "STOP" 3 "SNA";
VAL_ 1075 BCCEN_keyfobSummonRequest 0 "IDLE" 1 "PRIME" 2 "FORWARD" 3 "REVERSE";

VAL_ 577 BCCEN_ambientLightingRequest 0 "NO_REQUEST" 1 "REQUEST";
VAL_ 577 BCCEN_ambientLightsStatus 0 "OFF" 1 "ON" 2 "FAULT" 3 "SNA";
VAL_ 577 BCCEN_approachLightingRequest 0 "NO_REQUEST" 1 "REQUEST";
VAL_ 577 BCCEN_courtesyLightingRequest 0 "NO_REQUEST" 1 "REQUEST";
VAL_ 577 BCCEN_footwellLightsStatus 0 "OFF" 1 "ON" 2 "FAULT" 3 "SNA";
VAL_ 577 BCCEN_hazardLightRequest 0 "NONE" 1 "BUTTON" 2 "LOCK" 3 "UNLOCK" 4 "MISLOCK" 5 "CRASH" 6 "CAR_ALARM" 7 "DAS";
VAL_ 577 BCCEN_seeYouHomeLightingReq 0 "NO_REQUEST" 1 "REQUEST";
VAL_ 577 BCCEN_switchLightingRequest 0 "NO_REQUEST" 1 "REQUEST";

VAL_ 517 BCCEN_accRailStatus 0 "OFF" 1 "ON";
VAL_ 517 BCCEN_alarmStatus 0 "DISARMED" 1 "ARMED" 2 "PARTIAL_ARMED" 3 "TRIGGERED_FLASH_ACTIVE" 4 "ERROR" 5 "TRIGGERED_FLASH_INACTIVE" 6 "IMMINENT" 7 "DEFAULT" 15 "SNA";
VAL_ 517 BCCEN_batteryBackedSirenStatus 0 "NOT_INSTALLED" 1 "NOMINAL" 2 "FAULT" 3 "MIA";
VAL_ 517 BCCEN_chargePortRequest 0 "NO_ACTION" 1 "OPEN_CHG_CABLE_RF" 2 "OPEN_KEYFOB" 3 "DEFAULT_SNA";
VAL_ 517 BCCEN_crashStatus 0 "INACTIVE" 1 "ACTIVE" 3 "SNA";
VAL_ 517 BCCEN_driveRailStatus 0 "OFF" 1 "ON";
VAL_ 517 BCCEN_driverFrontLockStatus 0 "UNLOCKED" 1 "LOCKED";
VAL_ 517 BCCEN_driverPresent 0 "NOT_PRESENT" 1 "PRESENT";
VAL_ 517 BCCEN_driverRearLockStatus 0 "UNLOCKED" 1 "LOCKED";
VAL_ 517 BCCEN_falconLeftRequest 0 "IDLE" 1 "STOP" 2 "MOVE" 3 "OVERRIDE";
VAL_ 517 BCCEN_falconRightRequest 0 "IDLE" 1 "STOP" 2 "MOVE" 3 "OVERRIDE";
VAL_ 517 BCCEN_frontHoodCommand 0 "NO_ACTION" 1 "GOTO_OPEN" 2 "SNA";
VAL_ 517 BCCEN_frunkLockStatus 0 "UNLOCKED" 1 "LOCKED";
VAL_ 517 BCCEN_gloveBoxStatus 0 "CLOSED" 1 "OPEN" 2 "FAULT";
VAL_ 517 BCCEN_gloveBoxSwitchStatus 0 "OFF" 1 "ON" 2 "FAULT" 3 "SNA";
VAL_ 517 BCCEN_hvacRailStatus 0 "OFF" 1 "ON";
VAL_ 517 BCCEN_indicatorLeftRequest 0 "OFF" 1 "ACTIVE_LOW" 2 "ACTIVE_HIGH";
VAL_ 517 BCCEN_indicatorRightRequest 0 "OFF" 1 "ACTIVE_LOW" 2 "ACTIVE_HIGH";
VAL_ 517 BCCEN_intrusionTiltSensorStatus 0 "NOT_INSTALLED" 1 "NOMINAL" 2 "FAULT" 3 "MIA";
VAL_ 517 BCCEN_lastRKEKeyChannel 0 "0" 1 "1" 2 "2" 3 "3" 4 "4" 5 "5" 6 "6" 7 "NONE";
VAL_ 517 BCCEN_lockRejected 0 "NOT_REJECTED" 1 "REJECTED";
VAL_ 517 BCCEN_lockRequestType 0 "NONE" 1 "RKE_LOCK" 2 "PE_LOCK" 3 "REMOTE_LOCK" 4 "MCU_LOCK" 5 "RKE_UNLOCK" 6 "PE_UNLOCK" 7 "REMOTE_UNLOCK" 8 "TRANSPONDER_UNLOCK" 9 "MCU_UNLOCK" 10 "SELECTIVE_UNLOCK" 11 "TYPE_FALCON_LEFT_UNLOCKED" 12 "TYPE_FALCON_RIGHT_UNLOCKED" 13 "TYPE_TRUNK_UNLOCKED" 14 "TYPE_INTERIOR_DOOR_RELEASE" 15 "SNA";
VAL_ 517 BCCEN_numberOfKeysPaired 15 "NUMBER_OF_KEYS_PAIRED_SNA";
VAL_ 517 BCCEN_passengerFrontLockStatus 0 "UNLOCKED" 1 "LOCKED";
VAL_ 517 BCCEN_passengerRearLockStatus 0 "UNLOCKED" 1 "LOCKED";
VAL_ 517 BCCEN_rearTrunkRequest 0 "IDLE" 1 "STOP" 2 "MOVE" 3 "SNA";
VAL_ 517 BCCEN_remoteAccessState 0 "NO_KEY" 1 "NORMAL" 2 "RESET" 3 "LOCKED";
VAL_ 517 BCCEN_trunkLockStatus 0 "UNLOCKED" 1 "LOCKED";
VAL_ 517 BCCEN_vehicleLockStatus 0 "RKE_UNLOCKED" 1 "PE_UNLOCKED" 2 "INTERNAL_LOCKED" 3 "RKE_SELECTIVE_UNLOCKED" 4 "PE_SELECTIVE_UNLOCKED" 5 "RKE_LOCKED" 6 "PE_LOCKED" 7 "LOCKSTATUSDEFAULT";
VAL_ 517 BCCEN_windowControlAvailable 0 "NOTHING" 1 "NOT_AVAILABLE" 2 "AVAILABLE" 3 "SNA";
VAL_ 517 BCCEN_windowRequest 0 "NONE" 1 "AUTO_DOWN" 2 "AUTO_UP" 3 "DOWN" 4 "UP" 5 "FAULT" 6 "SNA";

VAL_ 938 BCCEN_autoPairingStatus 0 "IDLE" 1 "ARMED" 2 "CHECKING_KEYFOB_SE_VERSION" 3 "PAIRING" 4 "SUCCESS" 5 "FAILURE";
VAL_ 938 BCCEN_autoUpdateFault 0 "NONE" 1 "NO_STAGED_IMAGE" 2 "COULD_NOT_CHECK_VERSIONS" 3 "CONNECTION_FAILED" 4 "SERVICE_DISCOVERY_FAILED" 5 "COULD_NOT_SIGN_UP_FOR_UPDATES" 6 "COULD_NOT_IDENTIFY_RUNNING_IMAGE" 7 "FAILED_WRITING_NEW_HEADER" 8 "NO_RESPONSE_TO_BLOCK_WRITE" 9 "NO_NOTIFICATION_RESPONSE" 10 "KEYFOB_DISCONNECTED" 11 "KEYFOB_REFUSED_UPDATE";
VAL_ 938 BCCEN_autoUpdateStatus 0 "IDLE" 1 "LISTENING_FOR_KEYS" 2 "WAITING_TO_UPDATE" 3 "CONNECTING_TO_KEY" 4 "UPDATING" 5 "PAUSED" 6 "SUCCESS";
VAL_ 938 BCCEN_autoUpdaterFile 0 "BLE_APP" 1 "LF_APP";
VAL_ 938 BCCEN_closeAllStatus 0 "NOT_AVAILABLE" 1 "AVAILABLE" 2 "CANCELABLE";
VAL_ 938 BCCEN_connection1Status 0 "NOT_CONNECTED" 1 "CONNECTED" 2 "WRITE" 3 "NOTIFICATION" 4 "READ" 5 "UPDATE_SPEED";
VAL_ 938 BCCEN_connection2Status 0 "NOT_CONNECTED" 1 "CONNECTED" 2 "WRITE" 3 "NOTIFICATION" 4 "READ" 5 "UPDATE_SPEED";
VAL_ 938 BCCEN_connection3Status 0 "NOT_CONNECTED" 1 "CONNECTED" 2 "WRITE" 3 "NOTIFICATION" 4 "READ" 5 "UPDATE_SPEED";
VAL_ 938 BCCEN_immobilizerState 0 "IDLE" 1 "PREPARE" 2 "ENCRYPT_BEGIN" 3 "ENCRYPT" 4 "SEND_AUTH_RESPONSE" 5 "SEND_NO_GO_AUTH_RESPONSE";
VAL_ 938 BCCEN_pairingStep 0 "IDLE" 1 "PREPPING" 2 "GET_PAIRING_CHALLENGE" 3 "GET_PAIRING_TOKEN" 4 "PARSE_CERTIFICATE" 5 "REQUEST_TO_PAIR" 6 "LOADING_AES_KEYS" 7 "AUTHENTICATE";
VAL_ 938 BCCEN_parkECUPowerStatus 0 "OFF" 1 "ON" 2 "NOT_CONNECTED";

VAL_ 625 BCCEN_inOutDriveDirection 0 "SNA" 1 "INTO_DASH" 2 "OUT_OF_DASH" 3 "NONE";
VAL_ 625 BCCEN_steeringColumnInOutPos -1024 "STEERINGCOLUMN_POSITION_INVALID";
VAL_ 625 BCCEN_steeringColumnMoving 0 "NOT_MOVING" 1 "MOVING" 2 "FAULT" 3 "SNA";
VAL_ 625 BCCEN_steeringColumnUpDownPos -1024 "STEERINGCOLUMN_POSITION_INVALID";
VAL_ 625 BCCEN_upDownDriveDirection 0 "SNA" 1 "UP" 2 "DOWN" 3 "NONE";

VAL_ 991 BCFALCD_MCUChimeRequest 0 "NONE" 1 "SOFT" 2 "LOUD";
VAL_ 991 BCFALCD_appLogCondition 0 "NONE" 1 "FALCON_USS_OPEN_TO_FIT" 2 "PARK_OPEN_TO_FIT";
VAL_ 991 BCFALCD_devActuatorLogCondition 0 "NONE" 1 "NO_RESPONSE";
VAL_ 991 BCFALCD_devSectionLogCondition 0 "NONE" 1 "CURR_UPPER_FRONT_UNRESPONSIVE" 2 "CURR_UPPER_REAR_UNRESPONSIVE" 3 "CURR_LOWER_FRONT_UNRESPONSIVE" 4 "CURR_LOWER_REAR_UNRESPONSIVE";
VAL_ 991 BCFALCD_doorCtrlStatus 0 "IDLE" 1 "BACKOFF" 2 "OPENED" 3 "OPENING" 4 "OPENING_OVERRIDE" 5 "CLOSED" 6 "CLOSING" 7 "CLOSING_OVERRIDE" 8 "STOPPED" 9 "FAULT";
VAL_ 991 BCFALCD_obstacleDetected 0 "SNA" 1 "NONE" 2 "IMU" 3 "PINCH_STRIP" 4 "UPPER_INDUCTIVE" 5 "LOWER_CLADDING" 6 "REACTIVE" 7 "REACTIVE_MODEL" 8 "ULTRASONIC_DOOR" 9 "ULTRASONIC_ROOF" 10 "INWARD_USS";
VAL_ 991 BCFALCD_stoppingCondition 0 "NONE" 1 "NON_ZERO_DUTY_WHEN_LATCH_CLOSED" 2 "VEHICLE_AT_SPEED" 3 "RESET_REQUESTED" 4 "ACTUATOR_NO_RESPONSE" 5 "SECTION_POSITION_FAULT" 6 "DOOR_CYCLES_EXCEEDED" 7 "EXCEEDED_OPENLOOP_TRAVEL" 8 "ULTRASONIC_DOOR" 9 "ULTRASONIC_ROOF" 10 "PINCH" 11 "IMU" 12 "INDUCTIVE" 13 "CAPACITIVE" 14 "STATE_TIMEOUT" 15 "NOT_CALIBRATED" 16 "REACTIVE_SPEED" 17 "REACTIVE_CURRENT" 18 "REACTIVE_POSITION" 19 "REACTIVE_LATCH_ENTRY" 20 "ACTUATOR_OVER_TEMPERATURE" 21 "LATCH_SNA" 22 "SECTION_CURRENT_FAULT" 23 "SHOWROOM_MODE" 24 "KEY_REQUEST_WHILE_NOT_IN_PARK" 25 "REACTIVE_MODEL" 26 "STALL_NEAR_LATCH" 27 "ULTRASONIC_DOOR_PROACTIVE" 28 "ULTRASONIC_PARK_SENSOR" 29 "INWARD_USS";

VAL_ 1313 BCFALCD_infoIndex 0 "DEPRECATED_0" 1 "DEPRECATED_1" 2 "DEPRECATED_2" 3 "DEPRECATED_3" 4 "DEPRECATED_4" 5 "DEPRECATED_5" 6 "DEPRECATED_6" 7 "DEPRECATED_7" 8 "DEPRECATED_8" 9 "DEPRECATED_9" 10 "BUILD_HWID_COMPONENTID" 11 "PCBAID_ASSYID_USAGEID" 13 "APP_CRC" 14 "BOOTLOADER_SVN" 15 "BOOTLOADER_CRC" 16 "SUBCOMPONENT1" 17 "APP_GITHASH" 18 "BOOTLOADER_GITHASH" 19 "VERSION_DEPRECATED" 20 "UDS_PROTOCOL_BOOTCRC" 23 "SUBCOMPONENT2" 24 "SUBCOMPONENT3" 31 "SUBCOMPONENT4" 255 "END";
VAL_ 1313 BCFALCD_infoBuildType 0 "UNKNOWN_BUILD" 1 "PLATFORM_BUILD" 2 "LOCAL_BUILD" 3 "TRACEABLE_CI_BUILD" 4 "MFG_BUILD";
VAL_ 1313 BCFALCD_infoAssemblyID 1 "ASSEMBLY1" 255 "ASSEMBLY_SNA";

VAL_ 1001 BCFALCD_USSXLimit_status 0 "SNA" 1 "OPEN_DISALLOWED" 2 "OPEN_CONSTRAINED" 3 "OPEN_UNCONSTRAINED";
VAL_ 1001 BCFALCD_USSYLimit_status 0 "SNA" 1 "OPEN_DISALLOWED" 2 "OPEN_CONSTRAINED" 3 "OPEN_UNCONSTRAINED";
VAL_ 1001 BCFALCD_doorMaxHeight_cm 255 "MAX_DOOR_HEIGHT_SNA";
VAL_ 1001 BCFALCD_doorOpenToFitLimitSource 0 "FALCON_USS" 1 "PARKSENSOR" 2 "USS_MAPPING";
VAL_ 1001 BCFALCD_roofOpenToFitLimitSource 0 "FALCON_USS" 1 "PARKSENSOR" 2 "USS_MAPPING";

VAL_ 992 BCFALCP_MCUChimeRequest 0 "NONE" 1 "SOFT" 2 "LOUD";
VAL_ 992 BCFALCP_appLogCondition 0 "NONE" 1 "FALCON_USS_OPEN_TO_FIT" 2 "PARK_OPEN_TO_FIT";
VAL_ 992 BCFALCP_devActuatorLogCondition 0 "NONE" 1 "NO_RESPONSE";
VAL_ 992 BCFALCP_devSectionLogCondition 0 "NONE" 1 "CURR_UPPER_FRONT_UNRESPONSIVE" 2 "CURR_UPPER_REAR_UNRESPONSIVE" 3 "CURR_LOWER_FRONT_UNRESPONSIVE" 4 "CURR_LOWER_REAR_UNRESPONSIVE";
VAL_ 992 BCFALCP_doorCtrlStatus 0 "IDLE" 1 "BACKOFF" 2 "OPENED" 3 "OPENING" 4 "OPENING_OVERRIDE" 5 "CLOSED" 6 "CLOSING" 7 "CLOSING_OVERRIDE" 8 "STOPPED" 9 "FAULT";
VAL_ 992 BCFALCP_obstacleDetected 0 "SNA" 1 "NONE" 2 "IMU" 3 "PINCH_STRIP" 4 "UPPER_INDUCTIVE" 5 "LOWER_CLADDING" 6 "REACTIVE" 7 "REACTIVE_MODEL" 8 "ULTRASONIC_DOOR" 9 "ULTRASONIC_ROOF" 10 "INWARD_USS";
VAL_ 992 BCFALCP_stoppingCondition 0 "NONE" 1 "NON_ZERO_DUTY_WHEN_LATCH_CLOSED" 2 "VEHICLE_AT_SPEED" 3 "RESET_REQUESTED" 4 "ACTUATOR_NO_RESPONSE" 5 "SECTION_POSITION_FAULT" 6 "DOOR_CYCLES_EXCEEDED" 7 "EXCEEDED_OPENLOOP_TRAVEL" 8 "ULTRASONIC_DOOR" 9 "ULTRASONIC_ROOF" 10 "PINCH" 11 "IMU" 12 "INDUCTIVE" 13 "CAPACITIVE" 14 "STATE_TIMEOUT" 15 "NOT_CALIBRATED" 16 "REACTIVE_SPEED" 17 "REACTIVE_CURRENT" 18 "REACTIVE_POSITION" 19 "REACTIVE_LATCH_ENTRY" 20 "ACTUATOR_OVER_TEMPERATURE" 21 "LATCH_SNA" 22 "SECTION_CURRENT_FAULT" 23 "SHOWROOM_MODE" 24 "KEY_REQUEST_WHILE_NOT_IN_PARK" 25 "REACTIVE_MODEL" 26 "STALL_NEAR_LATCH" 27 "ULTRASONIC_DOOR_PROACTIVE" 28 "ULTRASONIC_PARK_SENSOR" 29 "INWARD_USS";

VAL_ 1316 BCFALCP_infoIndex 0 "DEPRECATED_0" 1 "DEPRECATED_1" 2 "DEPRECATED_2" 3 "DEPRECATED_3" 4 "DEPRECATED_4" 5 "DEPRECATED_5" 6 "DEPRECATED_6" 7 "DEPRECATED_7" 8 "DEPRECATED_8" 9 "DEPRECATED_9" 10 "BUILD_HWID_COMPONENTID" 11 "PCBAID_ASSYID_USAGEID" 13 "APP_CRC" 14 "BOOTLOADER_SVN" 15 "BOOTLOADER_CRC" 16 "SUBCOMPONENT1" 17 "APP_GITHASH" 18 "BOOTLOADER_GITHASH" 19 "VERSION_DEPRECATED" 20 "UDS_PROTOCOL_BOOTCRC" 23 "SUBCOMPONENT2" 24 "SUBCOMPONENT3" 31 "SUBCOMPONENT4" 255 "END";
VAL_ 1316 BCFALCP_infoBuildType 0 "UNKNOWN_BUILD" 1 "PLATFORM_BUILD" 2 "LOCAL_BUILD" 3 "TRACEABLE_CI_BUILD" 4 "MFG_BUILD";
VAL_ 1316 BCFALCP_infoAssemblyID 1 "ASSEMBLY1" 255 "ASSEMBLY_SNA";

VAL_ 1004 BCFALCP_USSXLimit_status 0 "SNA" 1 "OPEN_DISALLOWED" 2 "OPEN_CONSTRAINED" 3 "OPEN_UNCONSTRAINED";
VAL_ 1004 BCFALCP_USSYLimit_status 0 "SNA" 1 "OPEN_DISALLOWED" 2 "OPEN_CONSTRAINED" 3 "OPEN_UNCONSTRAINED";
VAL_ 1004 BCFALCP_doorMaxHeight_cm 255 "MAX_DOOR_HEIGHT_SNA";
VAL_ 1004 BCFALCP_doorOpenToFitLimitSource 0 "FALCON_USS" 1 "PARKSENSOR" 2 "USS_MAPPING";
VAL_ 1004 BCFALCP_roofOpenToFitLimitSource 0 "FALCON_USS" 1 "PARKSENSOR" 2 "USS_MAPPING";

VAL_ 1956 BCFDM_LINFailure 0 "NO_FAILURE" 1 "ACTUATOR_FAILURE" 4 "CLAW_SENSOR_FAILURE" 5 "NO_ENCODER_FEEDBACK" 6 "H_BRIDGE_FAILURE" 7 "OVER_TEMPERATURE" 8 "UNDER_VOLTAGE" 9 "OVER_VOLTAGE" 10 "OPERATION_DENIED" 11 "DOOR_ICED" 12 "CLINCH_OBSTRUCTED" 13 "MOTOR_STALLED" 14 "DEFAULT" 15 "SNA";
VAL_ 1956 BCFDM_LINStatus 0 "OPEN" 1 "AJAR" 2 "CLOSED" 3 "DEFAULT" 4 "SNA";

VAL_ 534 BCFDM_frontPassengerWindowReq 0 "NONE" 1 "AUTO_DOWN" 2 "AUTO_UP" 3 "DOWN" 4 "UP" 5 "FAULT" 6 "SNA";
VAL_ 534 BCFDM_passengerMirrorFoldRequest 0 "NO_REQUEST" 1 "RETRACT" 2 "PRESENT" 3 "SNA";
VAL_ 534 BCFDM_passengerMirrorRequest 0 "NONE" 1 "RIGHT" 2 "LEFT" 3 "DOWN" 4 "UP" 5 "FAULT" 6 "SNA";
VAL_ 534 BCFDM_rearDoorWindowLockStatus 0 "OFF" 1 "ON" 2 "FAULT" 3 "SNA";
VAL_ 534 BCFDM_rearDriverWindowReq 0 "NONE" 1 "AUTO_DOWN" 2 "AUTO_UP" 3 "DOWN" 4 "UP" 5 "FAULT" 6 "SNA";
VAL_ 534 BCFDM_rearPassengerWindowReq 0 "NONE" 1 "AUTO_DOWN" 2 "AUTO_UP" 3 "DOWN" 4 "UP" 5 "FAULT" 6 "SNA";

VAL_ 1295 BCFDM_infoIndex 0 "DEPRECATED_0" 1 "DEPRECATED_1" 2 "DEPRECATED_2" 3 "DEPRECATED_3" 4 "DEPRECATED_4" 5 "DEPRECATED_5" 6 "DEPRECATED_6" 7 "DEPRECATED_7" 8 "DEPRECATED_8" 9 "DEPRECATED_9" 10 "BUILD_HWID_COMPONENTID" 11 "PCBAID_ASSYID_USAGEID" 13 "APP_CRC" 14 "BOOTLOADER_SVN" 15 "BOOTLOADER_CRC" 16 "SUBCOMPONENT1" 17 "APP_GITHASH" 18 "BOOTLOADER_GITHASH" 19 "VERSION_DEPRECATED" 20 "UDS_PROTOCOL_BOOTCRC" 23 "SUBCOMPONENT2" 24 "SUBCOMPONENT3" 31 "SUBCOMPONENT4" 255 "END";
VAL_ 1295 BCFDM_infoBuildType 0 "UNKNOWN_BUILD" 1 "PLATFORM_BUILD" 2 "LOCAL_BUILD" 3 "TRACEABLE_CI_BUILD" 4 "MFG_BUILD";
VAL_ 1295 BCFDM_infoAssemblyID 1 "ASSEMBLY1" 255 "ASSEMBLY_SNA";

VAL_ 514 BCFDM_PFDSimpleState 0 "SNA" 1 "INIT" 2 "OPENING" 3 "CLOSING" 4 "CLOSED" 5 "OPENED";
VAL_ 514 BCFDM_ambientLightingStatus 0 "OFF" 1 "ON" 2 "FAULT" 3 "SNA";
VAL_ 514 BCFDM_backlightStatus 0 "OFF" 1 "ON" 2 "FAULT" 3 "SNA";
VAL_ 514 BCFDM_crashStatus 0 "INACTIVE" 1 "ACTIVE" 3 "SNA";
VAL_ 514 BCFDM_doorHandleLampStatus 0 "OFF" 1 "ON" 2 "FAULT" 3 "SNA";
VAL_ 514 BCFDM_doorNextAction 0 "CLOSE" 1 "OPEN";
VAL_ 514 BCFDM_exteriorReleaseStatus 0 "NOT_PRESSED" 1 "PRESSED" 2 "FAULT" 3 "SNA";
VAL_ 514 BCFDM_interiorReleaseStatus 0 "NOT_ACTIVE" 1 "ACTIVE" 2 "FAULT" 3 "SNA";
VAL_ 514 BCFDM_latchStatus 0 "SNA" 1 "OPENED" 2 "CLOSED" 3 "CLOSING" 4 "OPENING" 5 "AJAR" 6 "TIMEOUT" 7 "DEFAULT" 8 "FAULT";
VAL_ 514 BCFDM_lockStatusConfirmation 0 "UNLOCKED" 1 "LOCKED" 2 "FAULT" 3 "SNA";
VAL_ 514 BCFDM_masterKeyChannel 0 "0" 1 "1" 2 "2" 3 "3" 4 "4" 5 "5" 6 "6" 7 "NONE";
VAL_ 514 BCFDM_partyStatus 0 "STOP" 1 "USS_BLOCKED" 2 "READY" 3 "RUNNING";
VAL_ 514 BCFDM_puddleLampStatus 0 "OFF" 1 "ON" 2 "FAULT" 3 "SNA";
VAL_ 514 BCFDM_windowStatus 0 "UNKNOWN" 1 "CLOSED" 2 "PARTIALLY_OPEN" 3 "FULLY_OPEN" 4 "FAULT" 5 "SNA";

VAL_ 1957 BCFPM_LINFailure 0 "NO_FAILURE" 1 "ACTUATOR_FAILURE" 4 "CLAW_SENSOR_FAILURE" 5 "NO_ENCODER_FEEDBACK" 6 "H_BRIDGE_FAILURE" 7 "OVER_TEMPERATURE" 8 "UNDER_VOLTAGE" 9 "OVER_VOLTAGE" 10 "OPERATION_DENIED" 11 "DOOR_ICED" 12 "CLINCH_OBSTRUCTED" 13 "MOTOR_STALLED" 14 "DEFAULT" 15 "SNA";
VAL_ 1957 BCFPM_LINStatus 0 "OPEN" 1 "AJAR" 2 "CLOSED" 3 "DEFAULT" 4 "SNA";

VAL_ 1296 BCFPM_infoIndex 0 "DEPRECATED_0" 1 "DEPRECATED_1" 2 "DEPRECATED_2" 3 "DEPRECATED_3" 4 "DEPRECATED_4" 5 "DEPRECATED_5" 6 "DEPRECATED_6" 7 "DEPRECATED_7" 8 "DEPRECATED_8" 9 "DEPRECATED_9" 10 "BUILD_HWID_COMPONENTID" 11 "PCBAID_ASSYID_USAGEID" 13 "APP_CRC" 14 "BOOTLOADER_SVN" 15 "BOOTLOADER_CRC" 16 "SUBCOMPONENT1" 17 "APP_GITHASH" 18 "BOOTLOADER_GITHASH" 19 "VERSION_DEPRECATED" 20 "UDS_PROTOCOL_BOOTCRC" 23 "SUBCOMPONENT2" 24 "SUBCOMPONENT3" 31 "SUBCOMPONENT4" 255 "END";
VAL_ 1296 BCFPM_infoBuildType 0 "UNKNOWN_BUILD" 1 "PLATFORM_BUILD" 2 "LOCAL_BUILD" 3 "TRACEABLE_CI_BUILD" 4 "MFG_BUILD";
VAL_ 1296 BCFPM_infoAssemblyID 1 "ASSEMBLY1" 255 "ASSEMBLY_SNA";

VAL_ 512 BCFPM_PFDSimpleState 0 "SNA" 1 "INIT" 2 "OPENING" 3 "CLOSING" 4 "CLOSED" 5 "OPENED";
VAL_ 512 BCFPM_ambientLightingStatus 0 "OFF" 1 "ON" 2 "FAULT" 3 "SNA";
VAL_ 512 BCFPM_backlightStatus 0 "OFF" 1 "ON" 2 "FAULT" 3 "SNA";
VAL_ 512 BCFPM_crashStatus 0 "INACTIVE" 1 "ACTIVE" 3 "SNA";
VAL_ 512 BCFPM_doorHandleLampStatus 0 "OFF" 1 "ON" 2 "FAULT" 3 "SNA";
VAL_ 512 BCFPM_doorNextAction 0 "CLOSE" 1 "OPEN";
VAL_ 512 BCFPM_exteriorReleaseStatus 0 "NOT_PRESSED" 1 "PRESSED" 2 "FAULT" 3 "SNA";
VAL_ 512 BCFPM_interiorReleaseStatus 0 "NOT_ACTIVE" 1 "ACTIVE" 2 "FAULT" 3 "SNA";
VAL_ 512 BCFPM_latchStatus 0 "SNA" 1 "OPENED" 2 "CLOSED" 3 "CLOSING" 4 "OPENING" 5 "AJAR" 6 "TIMEOUT" 7 "DEFAULT" 8 "FAULT";
VAL_ 512 BCFPM_lockStatusConfirmation 0 "UNLOCKED" 1 "LOCKED" 2 "FAULT" 3 "SNA";
VAL_ 512 BCFPM_masterKeyChannel 0 "0" 1 "1" 2 "2" 3 "3" 4 "4" 5 "5" 6 "6" 7 "NONE";
VAL_ 512 BCFPM_partyStatus 0 "STOP" 1 "USS_BLOCKED" 2 "READY" 3 "RUNNING";
VAL_ 512 BCFPM_puddleLampStatus 0 "OFF" 1 "ON" 2 "FAULT" 3 "SNA";
VAL_ 512 BCFPM_windowStatus 0 "UNKNOWN" 1 "CLOSED" 2 "PARTIALLY_OPEN" 3 "FULLY_OPEN" 4 "FAULT" 5 "SNA";

VAL_ 1301 BCFRONT_infoIndex 0 "DEPRECATED_0" 1 "DEPRECATED_1" 2 "DEPRECATED_2" 3 "DEPRECATED_3" 4 "DEPRECATED_4" 5 "DEPRECATED_5" 6 "DEPRECATED_6" 7 "DEPRECATED_7" 8 "DEPRECATED_8" 9 "DEPRECATED_9" 10 "BUILD_HWID_COMPONENTID" 11 "PCBAID_ASSYID_USAGEID" 13 "APP_CRC" 14 "BOOTLOADER_SVN" 15 "BOOTLOADER_CRC" 16 "SUBCOMPONENT1" 17 "APP_GITHASH" 18 "BOOTLOADER_GITHASH" 19 "VERSION_DEPRECATED" 20 "UDS_PROTOCOL_BOOTCRC" 23 "SUBCOMPONENT2" 24 "SUBCOMPONENT3" 31 "SUBCOMPONENT4" 255 "END";
VAL_ 1301 BCFRONT_infoBuildType 0 "UNKNOWN_BUILD" 1 "PLATFORM_BUILD" 2 "LOCAL_BUILD" 3 "TRACEABLE_CI_BUILD" 4 "MFG_BUILD";
VAL_ 1301 BCFRONT_infoAssemblyID 1 "ASSEMBLY1" 255 "ASSEMBLY_SNA";

VAL_ 530 BCFRONT_approachLightingActive 0 "INACTIVE" 1 "ACTIVE" 2 "FAULT" 3 "SNA";
VAL_ 530 BCFRONT_corneringLeft1Status 0 "OFF" 1 "ON" 2 "FAULT" 3 "SNA";
VAL_ 530 BCFRONT_corneringLeft2Status 0 "OFF" 1 "ON" 2 "FAULT" 3 "SNA";
VAL_ 530 BCFRONT_corneringLeft3Status 0 "OFF" 1 "ON" 2 "FAULT" 3 "SNA";
VAL_ 530 BCFRONT_corneringRight1Status 0 "OFF" 1 "ON" 2 "FAULT" 3 "SNA";
VAL_ 530 BCFRONT_corneringRight2Status 0 "OFF" 1 "ON" 2 "FAULT" 3 "SNA";
VAL_ 530 BCFRONT_corneringRight3Status 0 "OFF" 1 "ON" 2 "FAULT" 3 "SNA";
VAL_ 530 BCFRONT_drlLeftStatus 0 "OFF" 1 "ON" 2 "FAULT" 3 "SNA";
VAL_ 530 BCFRONT_drlRightStatus 0 "OFF" 1 "ON" 2 "FAULT" 3 "SNA";
VAL_ 530 BCFRONT_fasciaLeftECUPower 0 "OFF" 1 "ON" 2 "FAULT" 3 "SNA";
VAL_ 530 BCFRONT_fasciaRightECUPower 0 "OFF" 1 "ON" 2 "FAULT" 3 "SNA";
VAL_ 530 BCFRONT_fogLightLeftStatus 0 "OFF" 1 "ON" 2 "FAULT" 3 "SNA";
VAL_ 530 BCFRONT_fogLightRightStatus 0 "OFF" 1 "ON" 2 "FAULT" 3 "SNA";
VAL_ 530 BCFRONT_frunkLightStatus 0 "OFF" 1 "ON" 2 "FAULT" 3 "SNA";
VAL_ 530 BCFRONT_headlightLeftECUPower 0 "OFF" 1 "ON" 2 "FAULT" 3 "SNA";
VAL_ 530 BCFRONT_headlightRightECUPower 0 "OFF" 1 "ON" 2 "FAULT" 3 "SNA";
VAL_ 530 BCFRONT_highBeamLeftStatus 0 "OFF" 1 "ON" 2 "FAULT" 3 "SNA";
VAL_ 530 BCFRONT_highBeamRightStatus 0 "OFF" 1 "ON" 2 "FAULT" 3 "SNA";
VAL_ 530 BCFRONT_indicatorLeftStatus 0 "OFF" 1 "ON" 2 "FAULT" 3 "SNA";
VAL_ 530 BCFRONT_indicatorRightStatus 0 "OFF" 1 "ON" 2 "FAULT" 3 "SNA";
VAL_ 530 BCFRONT_lowBeamLeftStatus 0 "OFF" 1 "ON" 2 "FAULT" 3 "SNA";
VAL_ 530 BCFRONT_lowBeamRightStatus 0 "OFF" 1 "ON" 2 "FAULT" 3 "SNA";
VAL_ 530 BCFRONT_parkLeftStatus 0 "OFF" 1 "ON" 2 "FAULT" 3 "SNA";
VAL_ 530 BCFRONT_parkRightStatus 0 "OFF" 1 "ON" 2 "FAULT" 3 "SNA";
VAL_ 530 BCFRONT_repeaterLeftStatus 0 "OFF" 1 "ON" 2 "FAULT" 3 "SNA";
VAL_ 530 BCFRONT_repeaterRightStatus 0 "OFF" 1 "ON" 2 "FAULT" 3 "SNA";
VAL_ 530 BCFRONT_seeYouHomeLightingActive 0 "INACTIVE" 1 "ACTIVE" 2 "FAULT" 3 "SNA";
VAL_ 530 BCFRONT_sideMarkerLeftStatus 0 "OFF" 1 "ON" 2 "FAULT" 3 "SNA";
VAL_ 530 BCFRONT_sideMarkerRightStatus 0 "OFF" 1 "ON" 2 "FAULT" 3 "SNA";
VAL_ 530 BCFRONT_signatureLeftStatus 0 "OFF" 1 "ON" 2 "FAULT" 3 "SNA";
VAL_ 530 BCFRONT_signatureRightStatus 0 "OFF" 1 "ON" 2 "FAULT" 3 "SNA";

VAL_ 527 BCFRONT_brakeFluidLevel 0 "LOW" 1 "NORMAL" 2 "SNA";
VAL_ 527 BCFRONT_crashStatus 0 "INACTIVE" 1 "ACTIVE" 3 "SNA";
VAL_ 527 BCFRONT_frunkIntSwStatus 0 "OFF" 1 "ON" 2 "FAULT" 3 "SNA";
VAL_ 527 BCFRONT_frunkLatchStatus 0 "SNA" 1 "OPENED" 2 "CLOSED" 3 "CLOSING" 4 "OPENING" 5 "AJAR" 6 "TIMEOUT" 7 "DEFAULT" 8 "FAULT";
VAL_ 527 BCFRONT_headlampLevelSetting 0 "1V" 1 "0_13V" 2 "0_15V" 3 "0_29V" 4 "0_38V" 7 "SNA";
VAL_ 527 BCFRONT_homelinkPowerStatus 0 "OFF" 1 "ON" 2 "FAULT" 3 "SNA";
VAL_ 527 BCFRONT_hornStatus 0 "OFF" 1 "ON" 2 "FAULT" 3 "SNA";
VAL_ 527 BCFRONT_lowBeamReason 0 "NONE" 1 "WIPERS" 2 "MASTER_SWITCH_ON" 3 "RLS_REQUEST" 4 "RLS_SNA" 5 "SYHL" 6 "CANADA";
VAL_ 527 BCFRONT_rearDefrostStatus 0 "OFF" 1 "ON" 2 "FAULT" 3 "SNA";
VAL_ 527 BCFRONT_washPumpStatus 0 "OFF" 1 "ON" 2 "SNA";
VAL_ 527 BCFRONT_washerFluidLevel 0 "LOW" 1 "NORMAL" 2 "SNA";
VAL_ 527 BCFRONT_wiperDefrostStatus 0 "OFF" 1 "ON" 2 "FAULT" 3 "SNA";
VAL_ 527 BCFRONT_wiperNozzleDefrostStatus 0 "OFF" 1 "ON" 2 "FAULT" 3 "SNA";

VAL_ 3 BC_approachLightingActive 0 "Not_Active" 1 "Active" 2 "Not_defined" 3 "Default";
VAL_ 3 BC_brakeLightLStatus 0 "Off" 1 "On" 2 "Failed" 3 "default";
VAL_ 3 BC_brakeLightRStatus 0 "Off" 1 "On" 2 "Failed" 3 "default";
VAL_ 3 BC_chmslStatus 0 "Off" 1 "On" 2 "Failed" 3 "default";
VAL_ 3 BC_courtesyLightingActive 0 "Not_Active" 1 "Active" 2 "Not_defined" 3 "Default";
VAL_ 3 BC_dtrlLeftStatus 0 "Off" 1 "On" 2 "Failed" 3 "default";
VAL_ 3 BC_dtrlRightStatus 0 "Off" 1 "On" 2 "Failed" 3 "default";
VAL_ 3 BC_fogLightFLStatus 0 "Off" 1 "On" 2 "Failed" 3 "default";
VAL_ 3 BC_fogLightFRStatus 0 "Off" 1 "On" 2 "Failed" 3 "default";
VAL_ 3 BC_fogLightRLStatus 0 "Off" 1 "On" 2 "Failed" 3 "default";
VAL_ 3 BC_fogLightRRStatus 0 "Off" 1 "On" 2 "Failed" 3 "default";
VAL_ 3 BC_headLightLStatus 0 "Off" 1 "On" 2 "Failed" 3 "default_headlight";
VAL_ 3 BC_headLightRStatus 0 "Off" 1 "On" 2 "Failed" 3 "default_headlight";
VAL_ 3 BC_indicatorLOn 0 "Not_Active" 1 "Active" 2 "Not_defined" 3 "Default";
VAL_ 3 BC_indicatorLStatus 0 "Off" 1 "On" 2 "Failed" 3 "default";
VAL_ 3 BC_indicatorROn 0 "Not_Active" 1 "Active" 2 "Not_defined" 3 "Default";
VAL_ 3 BC_indicatorRStatus 0 "Off" 1 "On" 2 "Failed" 3 "default";
VAL_ 3 BC_licencePlateIllumStatus 0 "Off" 1 "On" 2 "Failed" 3 "default";
VAL_ 3 BC_masterLightStatus 0 "Off" 1 "SideLamps" 2 "DippedBeam" 3 "Default";
VAL_ 3 BC_parkingLightLStatus 0 "OFF" 1 "ON" 2 "FAULT" 3 "SNA";
VAL_ 3 BC_parkingLightRStatus 0 "OFF" 1 "ON" 2 "FAULT" 3 "SNA";
VAL_ 3 BC_repeaterLeftOn 0 "Not_Active" 1 "Active" 2 "Not_defined" 3 "Default";
VAL_ 3 BC_repeaterRightOn 0 "Not_Active" 1 "Active" 2 "Not_defined" 3 "Default";
VAL_ 3 BC_reverseLightStatus 0 "Off" 1 "On" 2 "Failed" 3 "default";
VAL_ 3 BC_seeYouHomeLighting 0 "Not_Active" 1 "Active" 2 "Not_defined" 3 "Default";
VAL_ 3 BC_sideLightLStatus 0 "Off" 1 "On" 2 "Failed" 3 "default";
VAL_ 3 BC_sideLightRStatus 0 "Off" 1 "On" 2 "Failed" 3 "default";
VAL_ 3 BC_sidemarkerLightLStatus 0 "Off" 1 "On" 2 "Failed" 3 "default";
VAL_ 3 BC_sidemarkerLightRStatus 0 "Off" 1 "On" 2 "Failed" 3 "default";
VAL_ 3 BC_tailLightLStatus 0 "OFF" 1 "ON" 2 "FAULT" 3 "SNA";
VAL_ 3 BC_tailLightRStatus 0 "OFF" 1 "ON" 2 "FAULT" 3 "SNA";

VAL_ 532 BC_bcStatus 15 "SNA";
VAL_ 532 BC_brakeFluidLevel 0 "OK" 1 "Not_OK" 2 "Not_used" 3 "Default";
VAL_ 532 BC_curveLeft1Status 0 "OFF" 1 "ON" 2 "FAULT" 3 "SNA";
VAL_ 532 BC_curveLeft2Status 0 "OFF" 1 "ON" 2 "FAULT" 3 "SNA";
VAL_ 532 BC_curveLeft3Status 0 "OFF" 1 "ON" 2 "FAULT" 3 "SNA";
VAL_ 532 BC_curveRight1Status 0 "OFF" 1 "ON" 2 "FAULT" 3 "SNA";
VAL_ 532 BC_curveRight2Status 0 "OFF" 1 "ON" 2 "FAULT" 3 "SNA";
VAL_ 532 BC_curveRight3Status 0 "OFF" 1 "ON" 2 "FAULT" 3 "SNA";
VAL_ 532 BC_flashMainSwitch 0 "Flash_off" 1 "Momentary_flash" 2 "Main_beam_toggle" 7 "default_main_switch";
VAL_ 532 BC_ftSecondaryLatchStatus 0 "closed" 1 "open" 2 "fault" 3 "default";
VAL_ 532 BC_harnessType 0 "beta" 1 "rc" 2 "unused" 3 "SNA";
VAL_ 532 BC_headlightLevelerStatus 0 "SNA" 1 "LEVEL_1" 2 "LEVEL_2" 3 "LEVEL_0" 4 "FAULT";
VAL_ 532 BC_heaterStatus 0 "off" 1 "on";
VAL_ 532 BC_highBeamLStatus 0 "OFF" 1 "ON" 2 "FAULT" 3 "SNA";
VAL_ 532 BC_highBeamRStatus 0 "OFF" 1 "ON" 2 "FAULT" 3 "SNA";
VAL_ 532 BC_seeYouHomeTimer 0 "off" 1 "15" 2 "30" 3 "45" 4 "60" 7 "default";
VAL_ 532 BC_signatureLeftStatus 0 "OFF" 1 "ON" 2 "FAULT" 3 "SNA";
VAL_ 532 BC_signatureRightStatus 0 "OFF" 1 "ON" 2 "FAULT" 3 "SNA";
VAL_ 532 BC_vBattery 255 "SNA";
VAL_ 532 BC_washerFluidLevel 0 "ok" 1 "not_ok" 3 "default";

VAL_ 1303 BCRDM_infoIndex 0 "DEPRECATED_0" 1 "DEPRECATED_1" 2 "DEPRECATED_2" 3 "DEPRECATED_3" 4 "DEPRECATED_4" 5 "DEPRECATED_5" 6 "DEPRECATED_6" 7 "DEPRECATED_7" 8 "DEPRECATED_8" 9 "DEPRECATED_9" 10 "BUILD_HWID_COMPONENTID" 11 "PCBAID_ASSYID_USAGEID" 13 "APP_CRC" 14 "BOOTLOADER_SVN" 15 "BOOTLOADER_CRC" 16 "SUBCOMPONENT1" 17 "APP_GITHASH" 18 "BOOTLOADER_GITHASH" 19 "VERSION_DEPRECATED" 20 "UDS_PROTOCOL_BOOTCRC" 23 "SUBCOMPONENT2" 24 "SUBCOMPONENT3" 31 "SUBCOMPONENT4" 255 "END";
VAL_ 1303 BCRDM_infoBuildType 0 "UNKNOWN_BUILD" 1 "PLATFORM_BUILD" 2 "LOCAL_BUILD" 3 "TRACEABLE_CI_BUILD" 4 "MFG_BUILD";
VAL_ 1303 BCRDM_infoAssemblyID 1 "ASSEMBLY1" 255 "ASSEMBLY_SNA";

VAL_ 518 BCRDM_ambientLightingStatus 0 "OFF" 1 "ON" 2 "FAULT" 3 "SNA";
VAL_ 518 BCRDM_backlightStatus 0 "OFF" 1 "ON" 2 "FAULT" 3 "SNA";
VAL_ 518 BCRDM_crashStatus 0 "INACTIVE" 1 "ACTIVE" 3 "SNA";
VAL_ 518 BCRDM_doorRequest 0 "IDLE" 1 "STOP" 2 "CLOSE" 3 "OPEN";
VAL_ 518 BCRDM_exteriorReleaseStatus 0 "NOT_PRESSED" 1 "PRESSED" 2 "FAULT" 3 "SNA";
VAL_ 518 BCRDM_latchLowerStatus 0 "SNA" 1 "OPENED" 2 "CLOSED" 3 "CLOSING" 4 "OPENING" 5 "AJAR" 6 "TIMEOUT" 7 "DEFAULT" 8 "FAULT";
VAL_ 518 BCRDM_lockStatusConfirmation 0 "UNLOCKED" 1 "LOCKED" 2 "FAULT" 3 "SNA";
VAL_ 518 BCRDM_puddleLampStatus 0 "OFF" 1 "ON" 2 "FAULT" 3 "SNA";
VAL_ 518 BCRDM_shutFaceSwitchStatus 0 "OFF" 1 "ON" 2 "FAULT" 3 "SNA";
VAL_ 518 BCRDM_windowStatus 0 "UNKNOWN" 1 "CLOSED" 2 "PARTIALLY_OPEN" 3 "FULLY_OPEN" 4 "FAULT" 5 "SNA";

VAL_ 538 BCREAR_PLGMCUChimeRequest 0 "NONE" 1 "SINGLE" 2 "TRIPLE";
VAL_ 538 BCREAR_PLGMovementStatus 0 "SNA" 1 "CLOSED" 2 "STOPPED" 3 "MOVING";
VAL_ 538 BCREAR_PLGOpeningLimitSource 0 "NONE" 1 "USS" 2 "USER_SAVE" 3 "INDOOR_MODE";

VAL_ 1299 BCREAR_infoIndex 0 "DEPRECATED_0" 1 "DEPRECATED_1" 2 "DEPRECATED_2" 3 "DEPRECATED_3" 4 "DEPRECATED_4" 5 "DEPRECATED_5" 6 "DEPRECATED_6" 7 "DEPRECATED_7" 8 "DEPRECATED_8" 9 "DEPRECATED_9" 10 "BUILD_HWID_COMPONENTID" 11 "PCBAID_ASSYID_USAGEID" 13 "APP_CRC" 14 "BOOTLOADER_SVN" 15 "BOOTLOADER_CRC" 16 "SUBCOMPONENT1" 17 "APP_GITHASH" 18 "BOOTLOADER_GITHASH" 19 "VERSION_DEPRECATED" 20 "UDS_PROTOCOL_BOOTCRC" 23 "SUBCOMPONENT2" 24 "SUBCOMPONENT3" 31 "SUBCOMPONENT4" 255 "END";
VAL_ 1299 BCREAR_infoBuildType 0 "UNKNOWN_BUILD" 1 "PLATFORM_BUILD" 2 "LOCAL_BUILD" 3 "TRACEABLE_CI_BUILD" 4 "MFG_BUILD";
VAL_ 1299 BCREAR_infoAssemblyID 1 "ASSEMBLY1" 255 "ASSEMBLY_SNA";

VAL_ 562 BCREAR_approachLightingActive 0 "INACTIVE" 1 "ACTIVE" 2 "FAULT" 3 "SNA";
VAL_ 562 BCREAR_chmslLightStatus 0 "OFF" 1 "ON" 2 "FAULT" 3 "SNA";
VAL_ 562 BCREAR_fogLightLeftStatus 0 "OFF" 1 "ON" 2 "FAULT" 3 "SNA";
VAL_ 562 BCREAR_fogLightRightStatus 0 "OFF" 1 "ON" 2 "FAULT" 3 "SNA";
VAL_ 562 BCREAR_indicatorLeftStatus 0 "OFF" 1 "ON" 2 "FAULT" 3 "SNA";
VAL_ 562 BCREAR_indicatorRightStatus 0 "OFF" 1 "ON" 2 "FAULT" 3 "SNA";
VAL_ 562 BCREAR_licenseLightStatus 0 "OFF" 1 "ON" 2 "FAULT" 3 "SNA";
VAL_ 562 BCREAR_mapLightRow1LeftStatus 0 "OFF" 1 "ON" 2 "FAULT" 3 "SNA";
VAL_ 562 BCREAR_mapLightRow1RightStatus 0 "OFF" 1 "ON" 2 "FAULT" 3 "SNA";
VAL_ 562 BCREAR_mapLightRow2CenterStatus 0 "OFF" 1 "ON" 2 "FAULT" 3 "SNA";
VAL_ 562 BCREAR_mapLightRow2LeftStatus 0 "OFF" 1 "ON" 2 "FAULT" 3 "SNA";
VAL_ 562 BCREAR_mapLightRow2RightStatus 0 "OFF" 1 "ON" 2 "FAULT" 3 "SNA";
VAL_ 562 BCREAR_mapLightRow3LeftStatus 0 "OFF" 1 "ON" 2 "FAULT" 3 "SNA";
VAL_ 562 BCREAR_mapLightRow3RightStatus 0 "OFF" 1 "ON" 2 "FAULT" 3 "SNA";
VAL_ 562 BCREAR_reverseLightLeftStatus 0 "OFF" 1 "ON" 2 "FAULT" 3 "SNA";
VAL_ 562 BCREAR_reverseLightRightStatus 0 "OFF" 1 "ON" 2 "FAULT" 3 "SNA";
VAL_ 562 BCREAR_seeYouHomeLightingActive 0 "INACTIVE" 1 "ACTIVE" 2 "FAULT" 3 "SNA";
VAL_ 562 BCREAR_stopLightLeftStatus 0 "OFF" 1 "ON" 2 "FAULT" 3 "SNA";
VAL_ 562 BCREAR_stopLightRightStatus 0 "OFF" 1 "ON" 2 "FAULT" 3 "SNA";
VAL_ 562 BCREAR_tailLightLeftStatus 0 "OFF" 1 "ON" 2 "FAULT" 3 "SNA";
VAL_ 562 BCREAR_tailLightRightStatus 0 "OFF" 1 "ON" 2 "FAULT" 3 "SNA";
VAL_ 562 BCREAR_trailerLightFog 0 "OFF" 1 "ON" 2 "FAULT" 3 "SNA";
VAL_ 562 BCREAR_trailerLightParkLeft 0 "OFF" 1 "ON" 2 "FAULT" 3 "SNA";
VAL_ 562 BCREAR_trailerLightParkRight 0 "OFF" 1 "ON" 2 "FAULT" 3 "SNA";
VAL_ 562 BCREAR_trailerLightReverse 0 "OFF" 1 "ON" 2 "FAULT" 3 "SNA";
VAL_ 562 BCREAR_trailerLightStopLeft 0 "OFF" 1 "ON" 2 "FAULT" 3 "SNA";
VAL_ 562 BCREAR_trailerLightStopRight 0 "OFF" 1 "ON" 2 "FAULT" 3 "SNA";
VAL_ 562 BCREAR_trailerLightTurnLeft 0 "OFF" 1 "ON" 2 "FAULT" 3 "SNA";
VAL_ 562 BCREAR_trailerLightTurnRight 0 "OFF" 1 "ON" 2 "FAULT" 3 "SNA";
VAL_ 562 BCREAR_trunkLightStatus 0 "OFF" 1 "ON" 2 "FAULT" 3 "SNA";
VAL_ 562 BCREAR_trunkShutFaceBackLight 0 "OFF" 1 "ON" 2 "FAULT" 3 "SNA";

VAL_ 511 BCREAR_PLGSimpleStatus 0 "INIT" 1 "OFF" 2 "BACKOFF" 3 "OPENING" 4 "CLOSING" 5 "CLOSED" 6 "UNKNOWN";
VAL_ 511 BCREAR_crashStatus 0 "INACTIVE" 1 "ACTIVE" 3 "SNA";
VAL_ 511 BCREAR_lastRequestSource 0 "NONE" 1 "MCU_SWITCH" 2 "EXTERIOR" 3 "SHUTFACE" 4 "KEY_TRUNK_BUTTON" 5 "CLOSE_ALL" 6 "MCU_CLOSE";
VAL_ 511 BCREAR_lockStatusConfirmation 0 "UNLOCKED" 1 "LOCKED" 2 "FAULT" 3 "SNA";
VAL_ 511 BCREAR_mvmntNotAllowedCondition 0 "NONE" 1 "LOW_12V" 2 "VEHICLE_AT_SPEED" 3 "UNCALIBRATED" 4 "EXTERIOR_PRESS_AT_MAX_OPEN" 5 "LOCKED";
VAL_ 511 BCREAR_plgLeftAndMidPinchStatus 0 "NOT_DETECTED" 1 "DETECTED" 2 "DETECTION_FAULT" 3 "DETECTION_SNA";
VAL_ 511 BCREAR_plgRightPinchStatus 0 "NOT_DETECTED" 1 "DETECTED" 2 "DETECTION_FAULT" 3 "DETECTION_SNA";
VAL_ 511 BCREAR_powerLiftgateStatus 0 "INIT" 1 "OFF" 2 "BACKOFF" 3 "OPENING" 4 "CLOSING" 5 "CLOSED" 6 "LATCH_OPENING" 7 "LATCH_CLOSING" 8 "UNKNOWN" 9 "LATCH_EXIT" 10 "END_OF_TRAVEL" 11 "LATCH_ENTRY";
VAL_ 511 BCREAR_spoilerStatus 0 "SNA" 1 "RETRACTED" 2 "VISION" 3 "AERO" 4 "RETRACTING" 5 "EXTENDING" 6 "CALIBRATING" 7 "FAULT";
VAL_ 511 BCREAR_stoppingCondition 0 "NONE" 1 "PINCH" 2 "OBSTACLE_STALL" 3 "LOW_12V" 4 "STATE_TIMEOUT" 5 "VEHICLE_AT_SPEED" 6 "OBSTACLE_CURRENT" 7 "OBSTACLE_TRAJ_POS" 8 "OBSTACLE_TRAJ_VEL" 9 "UNCALIBRATED" 10 "LATCH_FAULT" 11 "COUNT";
VAL_ 511 BCREAR_trailerLightDetection 0 "SNA" 1 "FAULT" 2 "DETECTED" 3 "NOT_DETECTED";
VAL_ 511 BCREAR_trunkExtReleaseStatus 0 "NOT_PRESSED" 1 "PRESSED" 2 "FAULT" 3 "SNA";
VAL_ 511 BCREAR_trunkLatchStatus 0 "SNA" 1 "OPENED" 2 "CLOSED" 3 "CLOSING" 4 "OPENING" 5 "AJAR" 6 "TIMEOUT" 7 "DEFAULT" 8 "FAULT";
VAL_ 511 BCREAR_trunkShutFaceSwitchStatus 0 "OFF" 1 "ON" 2 "FAULT" 3 "SNA";

VAL_ 1304 BCRPM_infoIndex 0 "DEPRECATED_0" 1 "DEPRECATED_1" 2 "DEPRECATED_2" 3 "DEPRECATED_3" 4 "DEPRECATED_4" 5 "DEPRECATED_5" 6 "DEPRECATED_6" 7 "DEPRECATED_7" 8 "DEPRECATED_8" 9 "DEPRECATED_9" 10 "BUILD_HWID_COMPONENTID" 11 "PCBAID_ASSYID_USAGEID" 13 "APP_CRC" 14 "BOOTLOADER_SVN" 15 "BOOTLOADER_CRC" 16 "SUBCOMPONENT1" 17 "APP_GITHASH" 18 "BOOTLOADER_GITHASH" 19 "VERSION_DEPRECATED" 20 "UDS_PROTOCOL_BOOTCRC" 23 "SUBCOMPONENT2" 24 "SUBCOMPONENT3" 31 "SUBCOMPONENT4" 255 "END";
VAL_ 1304 BCRPM_infoBuildType 0 "UNKNOWN_BUILD" 1 "PLATFORM_BUILD" 2 "LOCAL_BUILD" 3 "TRACEABLE_CI_BUILD" 4 "MFG_BUILD";
VAL_ 1304 BCRPM_infoAssemblyID 1 "ASSEMBLY1" 255 "ASSEMBLY_SNA";

VAL_ 519 BCRPM_ambientLightingStatus 0 "OFF" 1 "ON" 2 "FAULT" 3 "SNA";
VAL_ 519 BCRPM_backlightStatus 0 "OFF" 1 "ON" 2 "FAULT" 3 "SNA";
VAL_ 519 BCRPM_crashStatus 0 "INACTIVE" 1 "ACTIVE" 3 "SNA";
VAL_ 519 BCRPM_doorRequest 0 "IDLE" 1 "STOP" 2 "CLOSE" 3 "OPEN";
VAL_ 519 BCRPM_exteriorReleaseStatus 0 "NOT_PRESSED" 1 "PRESSED" 2 "FAULT" 3 "SNA";
VAL_ 519 BCRPM_latchLowerStatus 0 "SNA" 1 "OPENED" 2 "CLOSED" 3 "CLOSING" 4 "OPENING" 5 "AJAR" 6 "TIMEOUT" 7 "DEFAULT" 8 "FAULT";
VAL_ 519 BCRPM_lockStatusConfirmation 0 "UNLOCKED" 1 "LOCKED" 2 "FAULT" 3 "SNA";
VAL_ 519 BCRPM_puddleLampStatus 0 "OFF" 1 "ON" 2 "FAULT" 3 "SNA";
VAL_ 519 BCRPM_shutFaceSwitchStatus 0 "OFF" 1 "ON" 2 "FAULT" 3 "SNA";
VAL_ 519 BCRPM_windowStatus 0 "UNKNOWN" 1 "CLOSED" 2 "PARTIALLY_OPEN" 3 "FULLY_OPEN" 4 "FAULT" 5 "SNA";

VAL_ 1312 BCS2C_infoIndex 0 "DEPRECATED_0" 1 "DEPRECATED_1" 2 "DEPRECATED_2" 3 "DEPRECATED_3" 4 "DEPRECATED_4" 5 "DEPRECATED_5" 6 "DEPRECATED_6" 7 "DEPRECATED_7" 8 "DEPRECATED_8" 9 "DEPRECATED_9" 10 "BUILD_HWID_COMPONENTID" 11 "PCBAID_ASSYID_USAGEID" 13 "APP_CRC" 14 "BOOTLOADER_SVN" 15 "BOOTLOADER_CRC" 16 "SUBCOMPONENT1" 17 "APP_GITHASH" 18 "BOOTLOADER_GITHASH" 19 "VERSION_DEPRECATED" 20 "UDS_PROTOCOL_BOOTCRC" 23 "SUBCOMPONENT2" 24 "SUBCOMPONENT3" 31 "SUBCOMPONENT4" 255 "END";
VAL_ 1312 BCS2C_infoBuildType 0 "UNKNOWN_BUILD" 1 "PLATFORM_BUILD" 2 "LOCAL_BUILD" 3 "TRACEABLE_CI_BUILD" 4 "MFG_BUILD";
VAL_ 1312 BCS2C_infoAssemblyID 1 "ASSEMBLY1" 255 "ASSEMBLY_SNA";

VAL_ 667 BCS2C_isPitchMoving 0 "IS_MOVING_SNA" 1 "NOT_MOVING" 2 "MOVING" 3 "MOVING_UNKNOWN";
VAL_ 667 BCS2C_pitchPosition -762 "EASY_ENTRY_FORWARD" -138 "COMFORT_FORWARD" 0 "EASY_ENTRY_REVERSE" 118 "COMFORT_REVERSE";
VAL_ 667 BCS2C_pitchState 0 "OFF" 1 "FORWARD" 2 "REVERSE" 3 "STOPPING" 4 "EASY_ENTRY_FORWARD" 5 "EASY_ENTRY_REVERSE" 6 "CALIBRATING" 7 "COLLISION_RESOLUTION_FWD" 8 "COLLISION_RESOLUTION_REV" 9 "CRASH" 10 "CRASH_FWD" 11 "CRASH_REV" 12 "UNKNOWN" 13 "NOT_INSTALLED";

VAL_ 604 BCS2C_2RChimeTelltaleRequest 0 "OFF" 1 "ON" 2 "UNUSED" 3 "SNA";
VAL_ 604 BCS2C_2RowBuckleStatus 0 "UNLATCHED" 1 "LATCHED" 2 "FAULTED" 3 "SNA";
VAL_ 604 BCS2C_2RowOccupancyStatus 0 "UNOCCUPIED" 1 "OCCUPIED" 2 "FAULTED" 3 "SNA";
VAL_ 604 BCS2C_3RChimeTelltaleRequest 0 "OFF" 1 "ON" 2 "UNUSED" 3 "SNA";
VAL_ 604 BCS2C_3RowBuckleStatus 0 "UNLATCHED" 1 "LATCHED" 2 "FAULTED" 3 "SNA";
VAL_ 604 BCS2C_3RowOccupancyStatus 0 "UNOCCUPIED" 1 "OCCUPIED" 2 "FAULTED" 3 "SNA";

VAL_ 866 BCS2C_crashStatus 0 "INACTIVE" 1 "ACTIVE" 3 "SNA";

VAL_ 574 BCS2C_3RowFoldFlatSwitch 0 "SNA" 1 "FAULT" 2 "HEADREST_ONLY" 3 "HEADREST_AND_FOLD" 4 "IDLE";
VAL_ 574 BCS2C_comfortPitchSwitchStatus 0 "IDLE" 1 "FORWARD" 2 "BACKWARD" 3 "FAULT" 4 "SNA";
VAL_ 574 BCS2C_comfortTrackSwitchStatus 0 "IDLE" 1 "FORWARD" 2 "BACKWARD" 3 "FAULT" 4 "SNA";
VAL_ 574 BCS2C_easyEntryHallSensorStatus 0 "SNA" 1 "FAULT" 2 "ACTIVE" 3 "INACTIVE";
VAL_ 574 BCS2C_easyEntryLatchSensorStatus 0 "SNA" 1 "FAULT" 2 "LATCHED" 3 "NOT_LATCHED";
VAL_ 574 BCS2C_easyEntryReadyForward 0 "NOT_READY" 1 "READY" 2 "NEEDS_OVERRIDE" 3 "IN_PROGRESS";
VAL_ 574 BCS2C_easyEntryReadyReverse 0 "NOT_READY" 1 "READY" 2 "NEEDS_OVERRIDE" 3 "IN_PROGRESS";
VAL_ 574 BCS2C_easyEntrySwitchStatus 0 "IDLE" 1 "FORWARD" 2 "BACKWARD" 3 "FAULT" 4 "SNA";
VAL_ 574 BCS2C_easyEntrySwitchStatusLeft 0 "IDLE" 1 "FORWARD" 2 "BACKWARD" 3 "FAULT" 4 "SNA";
VAL_ 574 BCS2C_easyEntrySwitchStatusRight 0 "IDLE" 1 "FORWARD" 2 "BACKWARD" 3 "FAULT" 4 "SNA";
VAL_ 574 BCS2C_easyEntryUnlatchStatus 0 "SNA" 1 "FAULT" 2 "UNLATCHED" 3 "NOT_UNLATCHED";
VAL_ 574 BCS2C_trackHomeSensorStatus 0 "SNA" 1 "FAULT" 2 "ACTIVE" 3 "INACTIVE";

VAL_ 687 BCS2C_isTrackMoving 0 "IS_MOVING_SNA" 1 "NOT_MOVING" 2 "MOVING" 3 "MOVING_UNKNOWN";
VAL_ 687 BCS2C_trackMotorPosition -5097 "EASY_ENTRY_COMFORT_REVERSE" -600 "COMFORT_FORWARD" 13645 "EASY_ENTRY_FORWARD";
VAL_ 687 BCS2C_trackState 0 "OFF" 1 "FORWARD" 2 "REVERSE" 3 "STOPPING" 4 "STARTING_EASY_ENTRY" 5 "EASY_ENTRY_FORWARD" 6 "EASY_ENTRY_REVERSE" 7 "CALIBRATING_FORWARD" 8 "CALIBRATING_REVERSE" 9 "COLLISION_RESOLUTION_FWD" 10 "COLLISION_RESOLUTION_REV" 11 "CRASH" 12 "CRASH_FWD" 13 "CRASH_REV" 14 "UNKNOWN" 15 "NOT_INSTALLED";

VAL_ 699 BCS2L_6040ReclinerState 0 "FORWARD" 1 "BACK" 2 "UNKNOWN" 3 "NOT_INSTALLED" 4 "CRASH";
VAL_ 699 BCS2L_6040ReclinerStopReason 0 "NONE" 1 "TIMEOUT" 2 "CURRENT_THRESHOLD" 3 "NO_CURRENT" 4 "CURRENT_PEAK";
VAL_ 699 BCS2L_6040TrackState 0 "LOCKED" 1 "RELEASING" 2 "RELEASED" 3 "LOCKING" 4 "UNKNOWN" 5 "NOT_INSTALLED" 6 "RELEASED_HOLD" 7 "LOCKING_UNDERCURRENT";
VAL_ 699 BCS2L_6040TrackStopReason 0 "NONE" 1 "TIMEOUT" 2 "CURRENT_THRESHOLD" 3 "NO_CURRENT" 4 "CURRENT_PEAK";

VAL_ 1311 BCS2L_infoIndex 0 "DEPRECATED_0" 1 "DEPRECATED_1" 2 "DEPRECATED_2" 3 "DEPRECATED_3" 4 "DEPRECATED_4" 5 "DEPRECATED_5" 6 "DEPRECATED_6" 7 "DEPRECATED_7" 8 "DEPRECATED_8" 9 "DEPRECATED_9" 10 "BUILD_HWID_COMPONENTID" 11 "PCBAID_ASSYID_USAGEID" 13 "APP_CRC" 14 "BOOTLOADER_SVN" 15 "BOOTLOADER_CRC" 16 "SUBCOMPONENT1" 17 "APP_GITHASH" 18 "BOOTLOADER_GITHASH" 19 "VERSION_DEPRECATED" 20 "UDS_PROTOCOL_BOOTCRC" 23 "SUBCOMPONENT2" 24 "SUBCOMPONENT3" 31 "SUBCOMPONENT4" 255 "END";
VAL_ 1311 BCS2L_infoBuildType 0 "UNKNOWN_BUILD" 1 "PLATFORM_BUILD" 2 "LOCAL_BUILD" 3 "TRACEABLE_CI_BUILD" 4 "MFG_BUILD";
VAL_ 1311 BCS2L_infoAssemblyID 1 "ASSEMBLY1" 255 "ASSEMBLY_SNA";

VAL_ 666 BCS2L_isPitchMoving 0 "IS_MOVING_SNA" 1 "NOT_MOVING" 2 "MOVING" 3 "MOVING_UNKNOWN";
VAL_ 666 BCS2L_pitchPosition -762 "EASY_ENTRY_FORWARD" -138 "COMFORT_FORWARD" 0 "EASY_ENTRY_REVERSE" 118 "COMFORT_REVERSE";
VAL_ 666 BCS2L_pitchState 0 "OFF" 1 "FORWARD" 2 "REVERSE" 3 "STOPPING" 4 "EASY_ENTRY_FORWARD" 5 "EASY_ENTRY_REVERSE" 6 "CALIBRATING" 7 "COLLISION_RESOLUTION_FWD" 8 "COLLISION_RESOLUTION_REV" 9 "CRASH" 10 "CRASH_FWD" 11 "CRASH_REV" 12 "UNKNOWN" 13 "NOT_INSTALLED";

VAL_ 603 BCS2L_2RChimeTelltaleRequest 0 "OFF" 1 "ON" 2 "UNUSED" 3 "SNA";
VAL_ 603 BCS2L_2RowBuckleStatus 0 "UNLATCHED" 1 "LATCHED" 2 "FAULTED" 3 "SNA";
VAL_ 603 BCS2L_2RowOccupancyStatus 0 "UNOCCUPIED" 1 "OCCUPIED" 2 "FAULTED" 3 "SNA";
VAL_ 603 BCS2L_3RChimeTelltaleRequest 0 "OFF" 1 "ON" 2 "UNUSED" 3 "SNA";
VAL_ 603 BCS2L_3RowBuckleStatus 0 "UNLATCHED" 1 "LATCHED" 2 "FAULTED" 3 "SNA";
VAL_ 603 BCS2L_3RowOccupancyStatus 0 "UNOCCUPIED" 1 "OCCUPIED" 2 "FAULTED" 3 "SNA";

VAL_ 865 BCS2L_crashStatus 0 "INACTIVE" 1 "ACTIVE" 3 "SNA";

VAL_ 573 BCS2L_3RowFoldFlatSwitch 0 "SNA" 1 "FAULT" 2 "HEADREST_ONLY" 3 "HEADREST_AND_FOLD" 4 "IDLE";
VAL_ 573 BCS2L_comfortPitchSwitchStatus 0 "IDLE" 1 "FORWARD" 2 "BACKWARD" 3 "FAULT" 4 "SNA";
VAL_ 573 BCS2L_comfortTrackSwitchStatus 0 "IDLE" 1 "FORWARD" 2 "BACKWARD" 3 "FAULT" 4 "SNA";
VAL_ 573 BCS2L_easyEntryHallSensorStatus 0 "SNA" 1 "FAULT" 2 "ACTIVE" 3 "INACTIVE";
VAL_ 573 BCS2L_easyEntryLatchSensorStatus 0 "SNA" 1 "FAULT" 2 "LATCHED" 3 "NOT_LATCHED";
VAL_ 573 BCS2L_easyEntryReadyForward 0 "NOT_READY" 1 "READY" 2 "NEEDS_OVERRIDE" 3 "IN_PROGRESS";
VAL_ 573 BCS2L_easyEntryReadyReverse 0 "NOT_READY" 1 "READY" 2 "NEEDS_OVERRIDE" 3 "IN_PROGRESS";
VAL_ 573 BCS2L_easyEntrySwitchStatus 0 "IDLE" 1 "FORWARD" 2 "BACKWARD" 3 "FAULT" 4 "SNA";
VAL_ 573 BCS2L_easyEntrySwitchStatusLeft 0 "IDLE" 1 "FORWARD" 2 "BACKWARD" 3 "FAULT" 4 "SNA";
VAL_ 573 BCS2L_easyEntrySwitchStatusRight 0 "IDLE" 1 "FORWARD" 2 "BACKWARD" 3 "FAULT" 4 "SNA";
VAL_ 573 BCS2L_easyEntryUnlatchStatus 0 "SNA" 1 "FAULT" 2 "UNLATCHED" 3 "NOT_UNLATCHED";
VAL_ 573 BCS2L_trackHomeSensorStatus 0 "SNA" 1 "FAULT" 2 "ACTIVE" 3 "INACTIVE";

VAL_ 683 BCS2L_isTrackMoving 0 "IS_MOVING_SNA" 1 "NOT_MOVING" 2 "MOVING" 3 "MOVING_UNKNOWN";
VAL_ 683 BCS2L_trackMotorPosition -5097 "EASY_ENTRY_COMFORT_REVERSE" -600 "COMFORT_FORWARD" 13645 "EASY_ENTRY_FORWARD";
VAL_ 683 BCS2L_trackState 0 "OFF" 1 "FORWARD" 2 "REVERSE" 3 "STOPPING" 4 "STARTING_EASY_ENTRY" 5 "EASY_ENTRY_FORWARD" 6 "EASY_ENTRY_REVERSE" 7 "CALIBRATING_FORWARD" 8 "CALIBRATING_REVERSE" 9 "COLLISION_RESOLUTION_FWD" 10 "COLLISION_RESOLUTION_REV" 11 "CRASH" 12 "CRASH_FWD" 13 "CRASH_REV" 14 "UNKNOWN" 15 "NOT_INSTALLED";
